[part 7 of 23: package /Cluster]
AUTOSAR XML (schema 4-3-0)
package /Cluster  (continued)
  can cluster E3V_EVCANFD: baudrate=500000, protocol-name=CAN, protocol-version=2.0, bus-off-recovery={bor-counter-l-1-to-l-2=1, bor-time-l-1=0.05, bor-time-l-2=0.2}, can-fd-baudrate=2000000  (continued)
    can physical channel CHNL: comm-connectors=CN_E3V_EVCANFD  (continued)
      frame Motor_52_XIX_E3V_EVCANFD: id 0x14A, to Klima, frame-length=32, can-addressing-mode=STANDARD, can-frame-rx-behavior=CAN-FD, can-frame-tx-behavior=CAN-FD
        pdu Motor_52_XIX_E3V_EVCANFD: length=32, transmission-mode-true-timing=cyclic-timing={time-offset=0, time-period=0.02}, unused-bit-pattern=0
          signal Motor_52_CRC_XIX_Motor_52_XIX_E3V_EVCANFD: start 0, 8 bit, little-endian, data-type-policy=OVERRIDE, i-signal-type=PRIMITIVE, init-value=0, base-type=BT_Motor_52_CRC, compu {phys=raw for raw 0..255}, range phys 0..255, raw 0..255, transfer-property=PENDING  # Für MLB: "Berechnung siehe Lastenheft "Kommunikationsabsicherung für FlexRay und CAN"" Ab MQB und MLBevo: "Berechnung siehe Lastenheft "End-to-End Kommunikationsabsicherung"" Endwerte siehe Begleitdokument "S-PDU Kennungsfolgen"
          signal Motor_52_BZ_XIX_Motor_52_XIX_E3V_EVCANFD: start 8, 4 bit, little-endian, data-type-policy=OVERRIDE, i-signal-type=PRIMITIVE, init-value=0, base-type=BT_Motor_52_BZ, compu {phys=raw for raw 0..15}, range phys 0..15, raw 0..15, transfer-property=PENDING
          signal MO_Hochschaltdrehz_XIX_Motor_52_XIX_E3V_EVCANFD: start 21, 12 bit, little-endian, data-type-policy=OVERRIDE, i-signal-type=PRIMITIVE, init-value=0, base-type=BT_MO_Hochschaltdrehz, invalid-value=Invalid_MO_Hochschaltdrehz_XIX_Motor_52_XIX_E3V_EVCANFD:4095, compu {0=Cx0_keine_manuelle_Hochschaltung (CM_MO_Hochschaltdrehz_Cx0_keine_manuelle_Hochschaltung), phys=raw*3 for raw 1..4094, 4095=Cxfff_Fehler (CM_MO_Hochschaltdrehz_Cxfff_Fehler); unit Unit_MinutInver}, range phys 3..12282 Unit_MinutInver, raw 0..4095, unit=Unit_MinutInver, transfer-property=PENDING  # Hochschaltdrehzahl bei manuellem Gangwechsel über Lenkrad Tip-Up oder Gangwahlhebel falls dieser in Tippgasse. Nur AUDI RS-Modelle!
          signal MO_Anzeige_Verbr_Einheit_XIX_Motor_52_XIX_E3V_EVCANFD: start 33, 2 bit, little-endian, data-type-policy=OVERRIDE, i-signal-type=PRIMITIVE, init-value=0, base-type=BT_MO_Anzeige_Verbr_Einheit, compu {0=Cx0_l_h (CM_MO_Anzeige_Verbr_Einheit_Cx0_l_h), 1=Cx1_kg_h (CM_MO_Anzeige_Verbr_Einheit_Cx1_kg_h)}, range raw 0..1, transfer-property=PENDING  # Signal steht im Kontext MO_Anzeige_Verbrauch und überträgt die Verbrauchseinheit der aktuellen Antriebsart. Signal muss in der gleichen Botschaft wie MO_Anzeige_Verbrauch übertragen werden
          signal MO_Schaltblitz_Anz_XIX_Motor_52_XIX_E3V_EVCANFD: start 35, 7 bit, little-endian, data-type-policy=OVERRIDE, i-signal-type=PRIMITIVE, init-value=126, base-type=BT_MO_Schaltblitz_Anz, invalid-value=Invalid_MO_Schaltblitz_Anz_XIX_Motor_52_XIX_E3V_EVCANFD:127, compu {phys=raw for raw 0..100, 101=Cx65_blinkende_Anzeige (CM_MO_Schaltblitz_Anz_Cx65_blinkende_Anzeige), 126=Cx7e_Init_Funktion_nicht_aktiv (CM_MO_Schaltblitz_Anz_Cx7e_Init_Funktion_nicht_aktiv), 127=Cx7f_Fehler (CM_MO_Schaltblitz_Anz_Cx7f_Fehler); unit Unit_PerCent}, range phys 0..100 Unit_PerCent, raw 0..127, unit=Unit_PerCent, transfer-property=PENDING  # Signalisierung der drehzahlabhängigen Schaltblitzanzeige im Kombiinstrument (0-100%)
          signal MO_Anzeige_Drehmoment_XIX_Motor_52_XIX_E3V_EVCANFD: start 42, 11 bit, little-endian, data-type-policy=OVERRIDE, i-signal-type=PRIMITIVE, init-value=0, base-type=BT_MO_Anzeige_Drehmoment, invalid-value=Invalid_MO_Anzeige_Drehmoment_XIX_Motor_52_XIX_E3V_EVCANFD:2047, compu {phys=raw for raw 0..2045, 2046=Cx7fe_nicht_verbaut (CM_MO_Anzeige_Drehmoment_Cx7fe_nicht_verbaut), 2047=Cx7ff_Fehler (CM_MO_Anzeige_Drehmoment_Cx7ff_Fehler); unit Unit_NewtoMeter}, range phys 0..2045 Unit_NewtoMeter, raw 0..2047, unit=Unit_NewtoMeter, transfer-property=PENDING  # Drehmomentssignal für Sport-HMI im Kombi.
          signal MO_Anzeige_Leistung_XIX_Motor_52_XIX_E3V_EVCANFD: start 53, 11 bit, little-endian, data-type-policy=OVERRIDE, i-signal-type=PRIMITIVE, init-value=0, base-type=BT_MO_Anzeige_Leistung, invalid-value=Invalid_MO_Anzeige_Leistung_XIX_Motor_52_XIX_E3V_EVCANFD:2047, compu {phys=raw*0.6 for raw 0..2045, 2046=Cx7fe_nicht_verbaut (CM_MO_Anzeige_Leistung_Cx7fe_nicht_verbaut), 2047=Cx7ff_Fehler (CM_MO_Anzeige_Leistung_Cx7ff_Fehler); unit Unit_KiloWatt}, range phys 0..1227 Unit_KiloWatt, raw 0..2047, unit=Unit_KiloWatt, transfer-property=PENDING  # Leistungssignal für Sport-HMI im Kombi.
          signal MO_rel_Ladedruck_XIX_Motor_52_XIX_E3V_EVCANFD: start 64, 8 bit, little-endian, data-type-policy=OVERRIDE, i-signal-type=PRIMITIVE, init-value=0, base-type=BT_MO_rel_Ladedruck, invalid-value=Invalid_MO_rel_Ladedruck_XIX_Motor_52_XIX_E3V_EVCANFD:255, compu {phys=raw*0.4 for raw 0..250, 255=Cxff_Fehler (CM_MO_rel_Ladedruck_Cxff_Fehler); unit Unit_PerCent}, range phys 0..100 Unit_PerCent, raw 0..255, unit=Unit_PerCent, transfer-property=PENDING  # relativer Ladedruck (für Boostanzeige)
          signal MO_Istgang_XIX_Motor_52_XIX_E3V_EVCANFD: start 72, 4 bit, little-endian, data-type-policy=OVERRIDE, i-signal-type=PRIMITIVE, init-value=0, base-type=BT_MO_Istgang, compu {0=Cx0_kein_Gang_eingelegt (CM_MO_Istgang_Cx0_kein_Gang_eingelegt), 1=Cx1_Gang_1 (CM_MO_Istgang_Cx1_Gang_1), 2=Cx2_Gang_2 (CM_MO_Istgang_Cx2_Gang_2), 3=Cx3_Gang_3 (CM_MO_Istgang_Cx3_Gang_3), 4=Cx4_Gang_4 (CM_MO_Istgang_Cx4_Gang_4), 5=Cx5_Gang_5 (CM_MO_Istgang_Cx5_Gang_5), 6=Cx6_Gang_6 (CM_MO_Istgang_Cx6_Gang_6), 7=Cx7_Gang_7 (CM_MO_Istgang_Cx7_Gang_7), 8=Cx8_Gang_8 (CM_MO_Istgang_Cx8_Gang_8), 9=Cx9_Gang_9 (CM_MO_Istgang_Cx9_Gang_9)}, range raw 0..9, transfer-property=PENDING  # Aktueller Gang für Anzeige Hochschaltempfehlung (gültig, wenn MO_Schaltempf_verfbar = 1). Anzeige im Kombi: Sollgang == Istgang ==> Anzeige Istgang Sollgang != Istgang ==> Schaltempfehlung Sollgang == Istgang == 0 ==> keine Anzeige
          signal MO_Sollgang_XIX_Motor_52_XIX_E3V_EVCANFD: start 76, 4 bit, little-endian, data-type-policy=OVERRIDE, i-signal-type=PRIMITIVE, init-value=0, base-type=BT_MO_Sollgang, compu {0=Cx0_keine_Empfehlung (CM_MO_Sollgang_Cx0_keine_Empfehlung), 1=Cx1_Gang_1 (CM_MO_Sollgang_Cx1_Gang_1), 2=Cx2_Gang_2 (CM_MO_Sollgang_Cx2_Gang_2), 3=Cx3_Gang_3 (CM_MO_Sollgang_Cx3_Gang_3), 4=Cx4_Gang_4 (CM_MO_Sollgang_Cx4_Gang_4), 5=Cx5_Gang_5 (CM_MO_Sollgang_Cx5_Gang_5), 6=Cx6_Gang_6 (CM_MO_Sollgang_Cx6_Gang_6), 7=Cx7_Gang_7 (CM_MO_Sollgang_Cx7_Gang_7), 8=Cx8_Gang_8 (CM_MO_Sollgang_Cx8_Gang_8), 9=Cx9_Gang_9 (CM_MO_Sollgang_Cx9_Gang_9), 15=Cxf_Neutralgang (CM_MO_Sollgang_Cxf_Neutralgang)}, range raw 0..15, transfer-property=PENDING  # Motor sendet den Sollgang in den der Fahrer schalten soll. Wird im Kombi als Hochschaltempfehlung hervorgehoben (gültig, wenn MO_Schaltempf_verfbar = 1). Anzeige im Kombi: Sollgang == Istgang ==> Anzeige Istgang Sollgang != Istgang ==> Schaltempfehlung Sollgang == Istgang == 0 ==> keine Anzeige Sollgang == 15 ==> Schaltempfehlung in N
          signal MO_Oeldruck_XIX_Motor_52_XIX_E3V_EVCANFD: start 80, 8 bit, little-endian, data-type-policy=OVERRIDE, i-signal-type=PRIMITIVE, init-value=254, base-type=BT_MO_Oeldruck, invalid-value=Invalid_MO_Oeldruck_XIX_Motor_52_XIX_E3V_EVCANFD:255, compu {phys=raw*0.04 for raw 0..250, 254=Cxfe_Init (CM_MO_Oeldruck_Cxfe_Init), 255=Cxff_Fehler (CM_MO_Oeldruck_Cxff_Fehler); unit Unit_Bar}, range phys 0..10 Unit_Bar, raw 0..255, unit=Unit_Bar, transfer-property=PENDING  # Öldruck analog zur Anzeige
          signal MO_Anzeigedrehz_XIX_Motor_52_XIX_E3V_EVCANFD: start 88, 12 bit, little-endian, data-type-policy=OVERRIDE, i-signal-type=PRIMITIVE, init-value=0, base-type=BT_MO_Anzeigedrehz, compu {phys=raw*3 for raw 0..4094, 4095=Cxfff_reserviert (CM_MO_Anzeigedrehz_Cxfff_reserviert); unit Unit_MinutInver}, range phys 0..12282 Unit_MinutInver, raw 0..4095, unit=Unit_MinutInver, transfer-property=PENDING  # Optimierte Anzeigedrehzahl wegen sportlicherem Drehzahlmesser im Kombi. Bei Parallelhybrid: Anzeige VKM- Drehzahl nach Anzeigekonzept Hinweis: Ehemaliger Fehlerwert 0xFFF wird senderseitig nicht unterstützt. Diesen Wert aus Kompatibilitätsgründen nicht neu belegen!
          signal MO_Effizienzmodus_XIX_Motor_52_XIX_E3V_EVCANFD: start 100, 1 bit, little-endian, data-type-policy=OVERRIDE, i-signal-type=PRIMITIVE, init-value=0, base-type=BT_MO_Effizienzmodus, compu {0=Cx0_nicht_im_Effizienz_Modus (CM_MO_Effizienzmodus_Cx0_nicht_im_Effizienz_Modus), 1=Cx1_Effizienz_Modus (CM_MO_Effizienzmodus_Cx1_Effizienz_Modus)}, range raw 0..1, transfer-property=PENDING  # Bei Handschaltern wird das Fahrprogramm Effizienz signalisiert. Bei Automatikgetrieben wird das Fahrprogramm "D" durch "E" ersetzt.
          signal MO_Fehler_Oeldrucksensor_XIX_Motor_52_XIX_E3V_EVCANFD: start 101, 1 bit, little-endian, data-type-policy=OVERRIDE, i-signal-type=PRIMITIVE, init-value=0, base-type=BT_MO_Fehler_Oeldrucksensor, invalid-value=Invalid_MO_Fehler_Oeldrucksensor_XIX_Motor_52_XIX_E3V_EVCANFD:1, compu {0=Cx0_kein_Fehler (CM_MO_Fehler_Oeldrucksensor_Cx0_kein_Fehler), 1=Cx1_Fehler (CM_MO_Fehler_Oeldrucksensor_Cx1_Fehler)}, range raw 0..1, transfer-property=PENDING  # Steuert im Kombiinstrument die gelbe zentrale Warnlampe und das Symbol "gelbe Ölkanne" mit der Textmeldung "Sensorfehler: Werkstatt aufsuchen" an
          signal MO_Schaltempf_verfbar_XIX_Motor_52_XIX_E3V_EVCANFD: start 102, 1 bit, little-endian, data-type-policy=OVERRIDE, i-signal-type=PRIMITIVE, init-value=0, base-type=BT_MO_Schaltempf_verfbar, compu {0=Cx0_nicht_verfuegbar (CM_MO_Schaltempf_verfbar_Cx0_nicht_verfuegbar), 1=Cx1_verfuegbar (CM_MO_Schaltempf_verfbar_Cx1_verfuegbar)}, range raw 0..1, transfer-property=PENDING  # Info, ob Schaltempfehlung im Fzg. verfügbar. Statischer Wert, ändert sich für ein Fzg. nicht!
          signal MO_Ladedruck_XIX_Motor_52_XIX_E3V_EVCANFD: start 103, 9 bit, little-endian, data-type-policy=OVERRIDE, i-signal-type=PRIMITIVE, init-value=0, base-type=BT_MO_Ladedruck, invalid-value=Invalid_MO_Ladedruck_XIX_Motor_52_XIX_E3V_EVCANFD:511, compu {phys=raw*0.01 for raw 0..510, 511=Cx1ff_Fehler (CM_MO_Ladedruck_Cx1ff_Fehler); unit Unit_Bar}, range phys 0..5.1 Unit_Bar, raw 0..511, unit=Unit_Bar, transfer-property=PENDING  # absoluter Ladedruck
          signal MO_KVS_XIX_Motor_52_XIX_E3V_EVCANFD: start 112, 15 bit, little-endian, data-type-policy=OVERRIDE, i-signal-type=PRIMITIVE, init-value=0, base-type=BT_MO_KVS, compu {phys=raw for raw 0..32767; unit Unit_MicroLiter}, range phys 0..32767 Unit_MicroLiter, raw 0..32767, unit=Unit_MicroLiter, transfer-property=PENDING  # Motorsteuergerätinterner Verbrauchszähler, der vom Kombi zyklisch ausgelesen wird, um die Einspritzmenge zur Verbrauchsmessung aufzusummieren; aus diesem Zählerstand werden Momentan- und Durchschnittsverbrauch berechnet; das Überlauf-Bit ist zu berücksichtigen
          signal MO_KVS_Ueberlauf_XIX_Motor_52_XIX_E3V_EVCANFD: start 127, 1 bit, little-endian, data-type-policy=OVERRIDE, i-signal-type=PRIMITIVE, init-value=0, base-type=BT_MO_KVS_Ueberlauf, compu {0=Cx0_kein_Ueberlauf (CM_MO_KVS_Ueberlauf_Cx0_kein_Ueberlauf) (kein Ueberlauf), 1=Cx1_Kraftstoffverbrauchsignale_mindestens_1x_uebergelaufen (CM_MO_KVS_Ueberlauf_Cx1_Kraftstoffverbrauchsignale_mindestens_1x_uebergelaufen) (Kraftstoffverbrauchsignale mindestens 1x übergelaufen)}, range raw 0..1, transfer-property=PENDING  # Der motorsteuergeräteinterne Verbrauchszähler ist mindestens einmal übergelaufen. Dieses Bit wird genutzt, um erkennen zu können, daß das Motorsteuergerät aus dem Reset-Zustand hochläuft.
          signal MO_ePowermeter_XIX_Motor_52_XIX_E3V_EVCANFD: start 128, 8 bit, little-endian, data-type-policy=OVERRIDE, i-signal-type=PRIMITIVE, init-value=0, base-type=BT_MO_ePowermeter, compu {0=Cx0_Init_keine_Anzeige (CM_MO_ePowermeter_Cx0_Init_keine_Anzeige), phys=raw*0.4-0.4 for raw 1..253, 254=Cxfe_Funktion_deaktiv_Anzeige_ausgegraut (CM_MO_ePowermeter_Cxfe_Funktion_deaktiv_Anzeige_ausgegraut), 255=Cxff_Fehler_keine_Anzeige (CM_MO_ePowermeter_Cxff_Fehler_keine_Anzeige); unit Unit_PerCent}, range phys 0..100.8 Unit_PerCent, raw 0..255, unit=Unit_PerCent, transfer-property=PENDING  # Anzeige ePowermeter (Fahrreserve elektrisch bis Start Verbrennungsmotor (Verbrenner startet bei 100%))
          signal MO_ePerformance_XIX_Motor_52_XIX_E3V_EVCANFD: start 136, 8 bit, little-endian, data-type-policy=OVERRIDE, i-signal-type=PRIMITIVE, init-value=0, base-type=BT_MO_ePerformance, invalid-value=Invalid_MO_ePerformance_XIX_Motor_52_XIX_E3V_EVCANFD:255, compu {0=Cx0_Init (CM_MO_ePerformance_Cx0_Init), phys=raw*0.4-0.4 for raw 1..253, 254=Cxfe_Funktion_deaktiv_Anz_ausgegraut (CM_MO_ePerformance_Cxfe_Funktion_deaktiv_Anz_ausgegraut), 255=Cxff_Fehler (CM_MO_ePerformance_Cxff_Fehler); unit Unit_PerCent}, range phys 0..100.8 Unit_PerCent, raw 0..255, unit=Unit_PerCent, transfer-property=PENDING  # Zeigt die elektrische Leistungreserve bei BEV und PHEV Projekten an. Bei Init und Fehler soll keine Anzeige erfolgen.
          signal MO_Zust_Antrieb_XIX_Motor_52_XIX_E3V_EVCANFD: start 144, 4 bit, little-endian, data-type-policy=OVERRIDE, i-signal-type=PRIMITIVE, init-value=0, base-type=BT_MO_Zust_Antrieb, compu {0=Cx0_VM_bzw_Brennstoffz_aktiv (CM_MO_Zust_Antrieb_Cx0_VM_bzw_Brennstoffz_aktiv) (VM bzw. Brennstoffz. aktiv), 1=Cx1_EM_aktiv (CM_MO_Zust_Antrieb_Cx1_EM_aktiv) (EM aktiv), 2=Cx2_VM_bzw_Brennstoffz_u_EM_aktiv (CM_MO_Zust_Antrieb_Cx2_VM_bzw_Brennstoffz_u_EM_aktiv) (VM bzw. Brennstoffz. u. EM aktiv), 3=Cx3_Segeln_oder_Reku_aktiv (CM_MO_Zust_Antrieb_Cx3_Segeln_oder_Reku_aktiv) (Segeln oder Reku aktiv)}, range raw 0..3, transfer-property=PENDING  # Signalisiert die Zuordnung der Antriebsverbräuche zu den Antriebsmaschinen für die Restreichweitenberechnung, nicht gleichbedeutend mit Motorlauf EM oder VM bzw. Brennstoffzelle
          signal MO_Zust_Betriebsstrategie_XIX_Motor_52_XIX_E3V_EVCANFD: start 148, 3 bit, little-endian, data-type-policy=OVERRIDE, i-signal-type=PRIMITIVE, init-value=0, base-type=BT_MO_Zust_Betriebsstrategie, compu {0=Cx0_Kein_Hybrid (CM_MO_Zust_Betriebsstrategie_Cx0_Kein_Hybrid) (Kein Hybrid), 1=Cx1_Depleting (CM_MO_Zust_Betriebsstrategie_Cx1_Depleting), 2=Cx2_Soft_Depleting (CM_MO_Zust_Betriebsstrategie_Cx2_Soft_Depleting) (Soft-Depleting), 3=Cx3_Sustaining (CM_MO_Zust_Betriebsstrategie_Cx3_Sustaining), 4=Cx4_Increasing (CM_MO_Zust_Betriebsstrategie_Cx4_Increasing), 5=Cx5_Fremdgesteuert (CM_MO_Zust_Betriebsstrategie_Cx5_Fremdgesteuert)}, range raw 0..5, transfer-property=PENDING  # Signalisiert den aktuellen Zustand der Betriebsstrategie
          signal Ladezustand_02_XIX_Motor_52_XIX_E3V_EVCANFD: start 152, 8 bit, little-endian, data-type-policy=OVERRIDE, i-signal-type=PRIMITIVE, init-value=254, base-type=BT_Ladezustand_02, invalid-value=Invalid_Ladezustand_02_XIX_Motor_52_XIX_E3V_EVCANFD:255, compu {phys=raw*0.5 for raw 0..200, 254=Cxfe_Init (CM_Ladezustand_02_Cxfe_Init), 255=Cxff_Fehler (CM_Ladezustand_02_Cxff_Fehler); unit Unit_PerCent}, range phys 0..100 Unit_PerCent, raw 0..255, unit=Unit_PerCent, transfer-property=PENDING, to Klima(timeout 0.5 s)  # Aktueller relativer Ladezustand der HV-Batterie
          signal Ladezustand_gering_XIX_Motor_52_XIX_E3V_EVCANFD: start 160, 2 bit, little-endian, data-type-policy=OVERRIDE, i-signal-type=PRIMITIVE, init-value=0, base-type=BT_Ladezustand_gering, compu {0=Cx0_keine_Anzeige (CM_Ladezustand_gering_Cx0_keine_Anzeige), 1=Cx1_Ladezustand_gering (CM_Ladezustand_gering_Cx1_Ladezustand_gering), 2=Cx2_Batterie_fast_leer (CM_Ladezustand_gering_Cx2_Batterie_fast_leer), 3=Cx3_Batterie_leer (CM_Ladezustand_gering_Cx3_Batterie_leer)}, range raw 0..3, transfer-property=PENDING  # Fahrerwarnung bezüglich geringem Ladezustand der HV-Batterie
          signal MO_Powermeter_Elm_02_XIX_Motor_52_XIX_E3V_EVCANFD: start 168, 12 bit, little-endian, data-type-policy=OVERRIDE, i-signal-type=PRIMITIVE, init-value=4094, base-type=BT_MO_Powermeter_Elm_02, compu {0=Cx0_nicht_verbaut (CM_MO_Powermeter_Elm_02_Cx0_nicht_verbaut), phys=raw*0.05-102.4 for raw 48..4048, 4094=Cxffe_Init (CM_MO_Powermeter_Elm_02_Cxffe_Init); unit Unit_PerCent}, range phys -100..100 Unit_PerCent, raw 0..4094, unit=Unit_PerCent, transfer-property=PENDING  # relatives Moment / relative Leistung der elektrischen Maschine
          signal MO_Powermeter_XIX_Motor_52_XIX_E3V_EVCANFD: start 180, 12 bit, little-endian, data-type-policy=OVERRIDE, i-signal-type=PRIMITIVE, init-value=4093, base-type=BT_MO_Powermeter, compu {phys=raw for raw 0..4092, 4093=Cxffd_Off (CM_MO_Powermeter_Cxffd_Off)}, range phys 0..4092, raw 0..4093, transfer-property=PENDING  # Anzeigewerte im Kombi 0 = Unteres Ende Bremsen/grau; 340 = Unteres Ende CHARGE; 1020 = READY; 1870 = Oberes Ende EFFICIENCY; 3400 = 100%; 4080 = MAX;
          signal MO_OnePedalDriving_Warnung_XIX_Motor_52_XIX_E3V_EVCANFD: start 192, 2 bit, little-endian, data-type-policy=OVERRIDE, i-signal-type=PRIMITIVE, init-value=0, base-type=BT_MO_OnePedalDriving_Warnung, compu {0=Cx0_keine_Warnung (CM_MO_OnePedalDriving_Warnung_Cx0_keine_Warnung), 1=Cx1_Warnstufe_1 (CM_MO_OnePedalDriving_Warnung_Cx1_Warnstufe_1)}, range raw 0..1, transfer-property=PENDING  # Bewarnung des Fahrers, wenn keine ausreichende Verzögerung aus der Funktion OnePedalDriving dargestellt werden kann. MO_OnePedalDriving_Warnung = 0 -> keine Warnung MO_OnePedalDriving_Warnung = 1 -> 1. Warnstufe
          signal MO_VKMVirt_Drehzahl_XIX_Motor_52_XIX_E3V_EVCANFD: start 200, 16 bit, little-endian, data-type-policy=OVERRIDE, i-signal-type=PRIMITIVE, init-value=0, base-type=BT_MO_VKMVirt_Drehzahl, compu {phys=raw*0.25 for raw 0..65532; unit Unit_MinutInver}, range phys 0..16383 Unit_MinutInver, raw 0..65532, unit=Unit_MinutInver, transfer-property=PENDING  # Signal zeigt die virtuelle, simulierte VKM-Drehzahl an
      frame Motor_54_XIX_E3V_EVCANFD: id 0x14C, to Klima, frame-length=32, can-addressing-mode=STANDARD, can-frame-rx-behavior=CAN-FD, can-frame-tx-behavior=CAN-FD
        pdu Motor_54_XIX_E3V_EVCANFD: length=32, minimum-delay=0.01, transmission-mode-true-timing={cyclic-timing={time-offset=0.0, time-period=0.1}, event-controlled-timing={number-of-repetitions=0, repetition-period=0.0}}, unused-bit-pattern=0
          signal Motor_54_CRC_XIX_Motor_54_XIX_E3V_EVCANFD: start 0, 8 bit, little-endian, data-type-policy=OVERRIDE, i-signal-type=PRIMITIVE, base-type=BT_Motor_54_CRC, compu {phys=raw for raw 0..255}, range phys 0..255, raw 0..255, transfer-property=PENDING  # Für MLB: Berechnung siehe Lastenheft "Kommunikationsabsicherung für FlexRay und CAN" Ab MQB und MLBevo: Berechnung siehe Lastenheft "End-to-End Kommunikationsabsicherung" Endwerte siehe Begleitdokument "S-PDU Kennungsfolgen"
          signal Motor_54_BZ_XIX_Motor_54_XIX_E3V_EVCANFD: start 8, 4 bit, little-endian, data-type-policy=OVERRIDE, i-signal-type=PRIMITIVE, base-type=BT_Motor_54_BZ, compu {phys=raw for raw 0..15}, range phys 0..15, raw 0..15, transfer-property=PENDING  # 4bit Botschaftszähler, wird mit jeder Sendebotschaft inkrementiert
          signal MO_Anforderung_HMS_XIX_Motor_54_XIX_E3V_EVCANFD: start 12, 3 bit, little-endian, data-type-policy=OVERRIDE, i-signal-type=PRIMITIVE, init-value=0, base-type=BT_MO_Anforderung_HMS, compu {0=Cx0_keine_Anforderung (CM_MO_Anforderung_HMS_Cx0_keine_Anforderung), 1=Cx1_halten (CM_MO_Anforderung_HMS_Cx1_halten), 2=Cx2_parken (CM_MO_Anforderung_HMS_Cx2_parken), 3=Cx3_halten_Standby (CM_MO_Anforderung_HMS_Cx3_halten_Standby), 4=Cx4_anfahren (CM_MO_Anforderung_HMS_Cx4_anfahren), 5=Cx5_Loesen_ueber_Rampe (CM_MO_Anforderung_HMS_Cx5_Loesen_ueber_Rampe), 7=Cx7_HMS_uebernehmen (CM_MO_Anforderung_HMS_Cx7_HMS_uebernehmen)}, range raw 0..7, transfer-property=TRIGGERED-ON-CHANGE-WITHOUT-REPETITION  # Halteanforderung vom Motor an HMS
          signal FoD_DTC_TSK_GRA_XIX_Motor_54_XIX_E3V_EVCANFD: start 15, 1 bit, little-endian, data-type-policy=OVERRIDE, i-signal-type=PRIMITIVE, init-value=0, base-type=BT_FoD_DTC_TSK_GRA, compu {0=Cx0_Kein_DTC (CM_FoD_DTC_TSK_GRA_Cx0_Kein_DTC), 1=Cx1_DTC_vorhanden_oder_in_Quali (CM_FoD_DTC_TSK_GRA_Cx1_DTC_vorhanden_oder_in_Quali)}, range raw 0..1, transfer-property=PENDING  # DTC ist entweder bereits eingetragen oder wird eingetragen, sobald die zugehörige FoD Funktion freigeschaltet wird.
          signal TSK_vMax_aktuell_XIX_Motor_54_XIX_E3V_EVCANFD: start 16, 8 bit, little-endian, data-type-policy=OVERRIDE, i-signal-type=PRIMITIVE, init-value=255, base-type=BT_TSK_vMax_aktuell, compu {phys=raw for raw 0..253, 254=Cxfe_kein_Limit_aktiv (CM_TSK_vMax_aktuell_Cxfe_kein_Limit_aktiv), 255=Cxff_Init (CM_TSK_vMax_aktuell_Cxff_Init); unit Unit_KiloMeterPerHour}, range phys 0..253 Unit_KiloMeterPerHour, raw 0..255, unit=Unit_KiloMeterPerHour, transfer-property=PENDING  # Im aktuellen Betriebszustand global gültige Geschwindigkeitslimitierung.
          signal ISA_Status_XIX_Motor_54_XIX_E3V_EVCANFD: start 24, 3 bit, little-endian, data-type-policy=OVERRIDE, i-signal-type=PRIMITIVE, init-value=1, base-type=BT_ISA_Status, compu {0=Cx0_ISA_nicht_aktiv (CM_ISA_Status_Cx0_ISA_nicht_aktiv), 1=Cx1_Init (CM_ISA_Status_Cx1_Init), 2=Cx2_ISA_degradiert (CM_ISA_Status_Cx2_ISA_degradiert), 3=Cx3_ISA_aktiv (CM_ISA_Status_Cx3_ISA_aktiv), 4=Cx4_reserviert (CM_ISA_Status_Cx4_reserviert), 5=Cx5_reserviert (CM_ISA_Status_Cx5_reserviert), 6=Cx6_reserviert (CM_ISA_Status_Cx6_reserviert), 7=Cx7_reserviert (CM_ISA_Status_Cx7_reserviert)}, range raw 0..7, transfer-property=TRIGGERED-ON-CHANGE-WITHOUT-REPETITION  # Signalisiert den Status der Funktion Intelligent Speed Assist (ISA). Der Status zeigt an, ob ISA Tempolimits übernimmt und einregelt. Dabei wird unterschieden, ob es sich um eine globale Aktivierung/Deaktivierung der Funktion, oder um eine temporäre Einschränkung der Tempolimit-Übernahme handelt.
          signal ISA_Regelung_aktiv_XIX_Motor_54_XIX_E3V_EVCANFD: start 27, 1 bit, little-endian, data-type-policy=OVERRIDE, i-signal-type=PRIMITIVE, init-value=0, base-type=BT_ISA_Regelung_aktiv, compu {0=Cx0_ISA_Regelung_nicht_aktiv (CM_ISA_Regelung_aktiv_Cx0_ISA_Regelung_nicht_aktiv), 1=Cx1_ISA_Regelung_aktiv (CM_ISA_Regelung_aktiv_Cx1_ISA_Regelung_aktiv)}, range raw 0..1, transfer-property=TRIGGERED-ON-CHANGE-WITHOUT-REPETITION  # Signalisiert, dass die Regelung zur Überführung der Fahrzeuggeschwindigkeit auf ein gültiges Tempolimit der Funktion Intelligent Speed Assist (ISA) aktiv ist.
          signal MO_Red_El_Fahrleistung_XIX_Motor_54_XIX_E3V_EVCANFD: start 29, 3 bit, little-endian, data-type-policy=OVERRIDE, i-signal-type=PRIMITIVE, init-value=0, base-type=BT_MO_Red_El_Fahrleistung, compu {0=Cx0_keine_Anzeige (CM_MO_Red_El_Fahrleistung_Cx0_keine_Anzeige), 1=Cx1_mehr_als_20Prcnt_Red (CM_MO_Red_El_Fahrleistung_Cx1_mehr_als_20Prcnt_Red), 2=Cx2_Reserve_1 (CM_MO_Red_El_Fahrleistung_Cx2_Reserve_1), 3=Cx3_Reserve_2 (CM_MO_Red_El_Fahrleistung_Cx3_Reserve_2), 4=Cx4_unter_GBB_Schwelle_Anhaenger (CM_MO_Red_El_Fahrleistung_Cx4_unter_GBB_Schwelle_Anhaenger), 5=Cx5_unter_GBB_Schwelle (CM_MO_Red_El_Fahrleistung_Cx5_unter_GBB_Schwelle), 6=Cx6_unter_minimal_Schwelle (CM_MO_Red_El_Fahrleistung_Cx6_unter_minimal_Schwelle), 7=Cx7_kein_Vortrieb (CM_MO_Red_El_Fahrleistung_Cx7_kein_Vortrieb)}, range raw 0..7, transfer-property=PENDING  # Anzeige einer eingeschränkten Fahrleistung
          signal TSK_Status_EA_XIX_Motor_54_XIX_E3V_EVCANFD: start 32, 3 bit, little-endian, data-type-policy=OVERRIDE, i-signal-type=PRIMITIVE, init-value=1, base-type=BT_TSK_Status_EA, invalid-value=Invalid_TSK_Status_EA_XIX_Motor_54_XIX_E3V_EVCANFD:7, compu {0=Cx0_Aus (CM_TSK_Status_EA_Cx0_Aus), 1=Cx1_Init_oder_nicht_verbaut (CM_TSK_Status_EA_Cx1_Init_oder_nicht_verbaut), 3=Cx3_Aktiv (CM_TSK_Status_EA_Cx3_Aktiv), 4=Cx4_Uebertreten (CM_TSK_Status_EA_Cx4_Uebertreten), 5=Cx5_Abschaltung_laeuft (CM_TSK_Status_EA_Cx5_Abschaltung_laeuft), 6=Cx6_Reversibel_aus (CM_TSK_Status_EA_Cx6_Reversibel_aus), 7=Cx7_Fehler (CM_TSK_Status_EA_Cx7_Fehler)}, range raw 0..7, transfer-property=TRIGGERED-ON-CHANGE-WITHOUT-REPETITION  # Funktionsstatus des Triebstrangkoordinators für den Anforderer Emergency Assist
          signal FoD_DTC_TSK_ACC_XIX_Motor_54_XIX_E3V_EVCANFD: start 35, 1 bit, little-endian, data-type-policy=OVERRIDE, i-signal-type=PRIMITIVE, init-value=0, base-type=BT_FoD_DTC_TSK_ACC, compu {0=Cx0_Kein_DTC (CM_FoD_DTC_TSK_ACC_Cx0_Kein_DTC), 1=Cx1_DTC_vorhanden_oder_in_Quali (CM_FoD_DTC_TSK_ACC_Cx1_DTC_vorhanden_oder_in_Quali)}, range raw 0..1, transfer-property=PENDING  # DTC ist entweder bereits eingetragen oder wird eingetragen, sobald die zugehörige FOD Funktion freigeschaltet wird.
          signal TSK_ACC_FoD_Status_XIX_Motor_54_XIX_E3V_EVCANFD: start 36, 2 bit, little-endian, data-type-policy=OVERRIDE, i-signal-type=PRIMITIVE, init-value=0, base-type=BT_TSK_ACC_FoD_Status, compu {0=Cx0_default (CM_TSK_ACC_FoD_Status_Cx0_default), 1=Cx1_nicht_aktiv (CM_TSK_ACC_FoD_Status_Cx1_nicht_aktiv), 2=Cx2_aktiv (CM_TSK_ACC_FoD_Status_Cx2_aktiv), 3=Cx3_nicht_genutzt (CM_TSK_ACC_FoD_Status_Cx3_nicht_genutzt)}, range raw 0..3, transfer-property=PENDING  # Information, ob die TSK-ACC-Funktion freigeschaltet ist oder nicht.
          signal TSK_GRA_FoD_Status_XIX_Motor_54_XIX_E3V_EVCANFD: start 38, 2 bit, little-endian, data-type-policy=OVERRIDE, i-signal-type=PRIMITIVE, init-value=0, base-type=BT_TSK_GRA_FoD_Status, compu {0=Cx0_default (CM_TSK_GRA_FoD_Status_Cx0_default), 1=Cx1_nicht_aktiv (CM_TSK_GRA_FoD_Status_Cx1_nicht_aktiv), 2=Cx2_aktiv (CM_TSK_GRA_FoD_Status_Cx2_aktiv), 3=Cx3_nicht_genutzt (CM_TSK_GRA_FoD_Status_Cx3_nicht_genutzt)}, range raw 0..3, transfer-property=PENDING  # Information, ob die TSK-GRA-Funktion freigeschaltet ist oder nicht.
          signal TSK_vMax_Fahrerassistenz_XIX_Motor_54_XIX_E3V_EVCANFD: start 40, 9 bit, little-endian, data-type-policy=OVERRIDE, i-signal-type=PRIMITIVE, init-value=511, base-type=BT_TSK_vMax_Fahrerassistenz, compu {phys=raw for raw 0..510, 511=Cx1ff_Init_ungueltig_keine_Beschraenkung (CM_TSK_vMax_Fahrerassistenz_Cx1ff_Init_ungueltig_keine_Beschraenkung)}, range phys 0..510, raw 0..511, transfer-property=PENDING  # maximale Sollgeschwindigkeit für GRA/ACC/Limiter Hinweis: Signal ist mit Signal TSK_Einheit_vMax_Fahrerassistenz zu interpretieren. Das Signal wird abwechselnd in km/h und mph gesendet.
          signal TSK_Einheit_vMax_Fahrerassistenz_XIX_Motor_54_XIX_E3V_EVCANFD: start 49, 1 bit, little-endian, data-type-policy=OVERRIDE, i-signal-type=PRIMITIVE, init-value=0, base-type=BT_TSK_Einheit_vMax_Fahrerassistenz, compu {0=Cx0_kmh (CM_TSK_Einheit_vMax_Fahrerassistenz_Cx0_kmh), 1=Cx1_mph (CM_TSK_Einheit_vMax_Fahrerassistenz_Cx1_mph)}, range raw 0..1, transfer-property=PENDING  # Einheit zu Signal TSK_vMax_Fahrerassistenz
          signal TSK_Status_PLA_XIX_Motor_54_XIX_E3V_EVCANFD: start 50, 3 bit, little-endian, data-type-policy=OVERRIDE, i-signal-type=PRIMITIVE, init-value=1, base-type=BT_TSK_Status_PLA, invalid-value=Invalid_TSK_Status_PLA_XIX_Motor_54_XIX_E3V_EVCANFD:7, compu {0=Cx0_Aus_Funktionsbereit (CM_TSK_Status_PLA_Cx0_Aus_Funktionsbereit), 1=Cx1_Init_oder_nicht_verbaut (CM_TSK_Status_PLA_Cx1_Init_oder_nicht_verbaut), 2=Cx2_aktivierbar (CM_TSK_Status_PLA_Cx2_aktivierbar), 3=Cx3_aktiv (CM_TSK_Status_PLA_Cx3_aktiv), 5=Cx5_Abschaltung_laeuft (CM_TSK_Status_PLA_Cx5_Abschaltung_laeuft), 6=Cx6_reversibel_aus (CM_TSK_Status_PLA_Cx6_reversibel_aus), 7=Cx7_Fehler (CM_TSK_Status_PLA_Cx7_Fehler)}, range raw 0..7, transfer-property=TRIGGERED-ON-CHANGE-WITHOUT-REPETITION  # Funktionsstatus des Triebstrangkoordinators für den Speedlimiter des Parkassistenten
          signal TSK_aktives_System_XIX_Motor_54_XIX_E3V_EVCANFD: start 53, 3 bit, little-endian, data-type-policy=OVERRIDE, i-signal-type=PRIMITIVE, init-value=0, base-type=BT_TSK_aktives_System, compu {0=Cx0_keine_Funktion_aktiv (CM_TSK_aktives_System_Cx0_keine_Funktion_aktiv), 1=Cx1_GRA_ACC (CM_TSK_aktives_System_Cx1_GRA_ACC), 2=Cx2_ARA (CM_TSK_aktives_System_Cx2_ARA), 3=Cx3_Speedlimiter (CM_TSK_aktives_System_Cx3_Speedlimiter), 4=Cx4_IPA (CM_TSK_aktives_System_Cx4_IPA), 5=Cx5_PLA (CM_TSK_aktives_System_Cx5_PLA), 6=Cx6_PEA_Ausrollassistent (CM_TSK_aktives_System_Cx6_PEA_Ausrollassistent), 7=Cx7_EA (CM_TSK_aktives_System_Cx7_EA)}, range raw 0..7, transfer-property=TRIGGERED-ON-CHANGE-WITHOUT-REPETITION  # Anzeige der in der TSK-Längsführung aktiven Funktion
          signal TSK_erhoehter_Fahrwiderstand_XIX_Motor_54_XIX_E3V_EVCANFD: start 56, 1 bit, little-endian, data-type-policy=OVERRIDE, i-signal-type=PRIMITIVE, init-value=0, base-type=BT_TSK_erhoehter_Fahrwiderstand, compu {0=Cx0_kein_erhoehter_Fahrwiderstand (CM_TSK_erhoehter_Fahrwiderstand_Cx0_kein_erhoehter_Fahrwiderstand), 1=Cx1_erhoehter_Fahrwiderstand (CM_TSK_erhoehter_Fahrwiderstand_Cx1_erhoehter_Fahrwiderstand)}, range raw 0..1, transfer-property=TRIGGERED-ON-CHANGE-WITHOUT-REPETITION  # Rueckmeldung vom Triebstrangkoordinator, dass eine große Reglerdifferenz detektiert wurde. Soll ermoeglichen, einen ggfs. unbekannten Fahrwiderstand am Boden zu erkennen.
          signal TSK_Anf_Antriebsmoment_XIX_Motor_54_XIX_E3V_EVCANFD: start 57, 1 bit, little-endian, data-type-policy=OVERRIDE, i-signal-type=PRIMITIVE, init-value=0, base-type=BT_TSK_Anf_Antriebsmoment, compu {0=Cx0_keine_Anforderung (CM_TSK_Anf_Antriebsmoment_Cx0_keine_Anforderung), 1=Cx1_Anforderung_aktiv (CM_TSK_Anf_Antriebsmoment_Cx1_Anforderung_aktiv)}, range raw 0..1, transfer-property=TRIGGERED-ON-CHANGE-WITHOUT-REPETITION  # Das Signal zeigt an, ob die TSK-Laengsregelung aktuell Antriebsmoment anfordert, zur Verwendung in der ASR/EDS-Funktion
          signal TSK_Status_ARA_XIX_Motor_54_XIX_E3V_EVCANFD: start 58, 3 bit, little-endian, data-type-policy=OVERRIDE, i-signal-type=PRIMITIVE, init-value=1, base-type=BT_TSK_Status_ARA, invalid-value=Invalid_TSK_Status_ARA_XIX_Motor_54_XIX_E3V_EVCANFD:7, compu {0=Cx0_Aus (CM_TSK_Status_ARA_Cx0_Aus), 1=Cx1_Init_oder_nicht_verbaut (CM_TSK_Status_ARA_Cx1_Init_oder_nicht_verbaut), 2=Cx2_aktivierbar (CM_TSK_Status_ARA_Cx2_aktivierbar), 3=Cx3_aktiv (CM_TSK_Status_ARA_Cx3_aktiv), 5=Cx5_abschaltung_laeuft (CM_TSK_Status_ARA_Cx5_abschaltung_laeuft), 6=Cx6_reversibel_aus (CM_TSK_Status_ARA_Cx6_reversibel_aus), 7=Cx7_Fehler (CM_TSK_Status_ARA_Cx7_Fehler)}, range raw 0..7, transfer-property=TRIGGERED-ON-CHANGE-WITHOUT-REPETITION  # Funktionsstatus des Triebstrangkoordinators für den Anhängerrangierassistenten
          signal TSK_Status_IPA_XIX_Motor_54_XIX_E3V_EVCANFD: start 61, 3 bit, little-endian, data-type-policy=OVERRIDE, i-signal-type=PRIMITIVE, init-value=1, base-type=BT_TSK_Status_IPA, invalid-value=Invalid_TSK_Status_IPA_XIX_Motor_54_XIX_E3V_EVCANFD:7, compu {0=Cx0_Aus_Funktionsbereit (CM_TSK_Status_IPA_Cx0_Aus_Funktionsbereit), 1=Cx1_Init_oder_nicht_verbaut (CM_TSK_Status_IPA_Cx1_Init_oder_nicht_verbaut), 2=Cx2_aktivierbar (CM_TSK_Status_IPA_Cx2_aktivierbar), 3=Cx3_aktiv (CM_TSK_Status_IPA_Cx3_aktiv), 4=Cx4_Fahreruebernahme_angefordert (CM_TSK_Status_IPA_Cx4_Fahreruebernahme_angefordert), 5=Cx5_Abschaltung_laueft (CM_TSK_Status_IPA_Cx5_Abschaltung_laueft), 6=Cx6_reversibel_aus (CM_TSK_Status_IPA_Cx6_reversibel_aus), 7=Cx7_Fehler (CM_TSK_Status_IPA_Cx7_Fehler)}, range raw 0..7, transfer-property=TRIGGERED-ON-CHANGE-WITHOUT-REPETITION  # Funktionsstatus des Triebstrangkoordinators für die Längsführung des Einparkassistenten
          signal TSK_aktives_System_02_XIX_Motor_54_XIX_E3V_EVCANFD: start 64, 4 bit, little-endian, data-type-policy=OVERRIDE, i-signal-type=PRIMITIVE, init-value=0, base-type=BT_TSK_aktives_System_02, compu {0=Cx0_keine_Funktion_aktiv (CM_TSK_aktives_System_02_Cx0_keine_Funktion_aktiv), 1=Cx1_GRA_ACC (CM_TSK_aktives_System_02_Cx1_GRA_ACC), 2=Cx2_ARA (CM_TSK_aktives_System_02_Cx2_ARA), 3=Cx3_Speedlimiter (CM_TSK_aktives_System_02_Cx3_Speedlimiter), 4=Cx4_IPA (CM_TSK_aktives_System_02_Cx4_IPA), 5=Cx5_PLA (CM_TSK_aktives_System_02_Cx5_PLA), 6=Cx6_PEA_Ausrollassistent (CM_TSK_aktives_System_02_Cx6_PEA_Ausrollassistent), 7=Cx7_EA (CM_TSK_aktives_System_02_Cx7_EA), 8=Cx8_Staupilot (CM_TSK_aktives_System_02_Cx8_Staupilot), 9=Cx9_RHP (CM_TSK_aktives_System_02_Cx9_RHP)}, range raw 0..9, transfer-property=TRIGGERED-ON-CHANGE-WITHOUT-REPETITION  # Anzeige der in der TSK-Längsführung aktiven Funktion
          signal TSK_Status_RHP_XIX_Motor_54_XIX_E3V_EVCANFD: start 68, 3 bit, little-endian, data-type-policy=OVERRIDE, i-signal-type=PRIMITIVE, init-value=0, base-type=BT_TSK_Status_RHP, compu {0=Cx0_off (CM_TSK_Status_RHP_Cx0_off), 1=Cx1_init (CM_TSK_Status_RHP_Cx1_init), 2=Cx2_standby (CM_TSK_Status_RHP_Cx2_standby), 3=Cx3_active (CM_TSK_Status_RHP_Cx3_active), 4=Cx4_driver_override (CM_TSK_Status_RHP_Cx4_driver_override), 5=Cx5_shutdown (CM_TSK_Status_RHP_Cx5_shutdown), 6=Cx6_reversible_failure (CM_TSK_Status_RHP_Cx6_reversible_failure), 7=Cx7_irreversible_failure (CM_TSK_Status_RHP_Cx7_irreversible_failure)}, range raw 0..7, transfer-property=TRIGGERED-ON-CHANGE-WITHOUT-REPETITION  # Functional status of the drive train coordinator for the longitudinal guidance of the rush hour pilot.
          signal MO_OnePedalDriving_integriert_XIX_Motor_54_XIX_E3V_EVCANFD: start 71, 1 bit, little-endian, data-type-policy=OVERRIDE, i-signal-type=PRIMITIVE, init-value=0, base-type=BT_MO_OnePedalDriving_integriert, compu {0=Cx0_OPD_nicht_integriert (CM_MO_OnePedalDriving_integriert_Cx0_OPD_nicht_integriert), 1=Cx1_OPD_integriert (CM_MO_OnePedalDriving_integriert_Cx1_OPD_integriert)}, range raw 0..1, transfer-property=PENDING  # Zeigt an, dass das Antriebssteuergerät die Funktion OnePedalDriving unterstützt.
          signal MO_Klima_Regelmodus_XIX_Motor_54_XIX_E3V_EVCANFD: start 74, 2 bit, little-endian, data-type-policy=OVERRIDE, i-signal-type=PRIMITIVE, init-value=0, base-type=BT_MO_Klima_Regelmodus, compu {0=Cx0_Init (CM_MO_Klima_Regelmodus_Cx0_Init), 1=Cx1_Regelmodus_1 (CM_MO_Klima_Regelmodus_Cx1_Regelmodus_1), 2=Cx2_Regelmodus_2 (CM_MO_Klima_Regelmodus_Cx2_Regelmodus_2), 3=Cx3_Regelmodus_3 (CM_MO_Klima_Regelmodus_Cx3_Regelmodus_3)}, range raw 0..3, transfer-property=PENDING, to Klima(timeout 1 s)  # Anforderung an Klima SG zur Regelungsanpassung der HV Klimakomponenten bei bestimmten Umweltbedingungen
          signal MO_Fahrbereitschaft_XIX_Motor_54_XIX_E3V_EVCANFD: start 76, 2 bit, little-endian, data-type-policy=OVERRIDE, i-signal-type=PRIMITIVE, init-value=0, base-type=BT_MO_Fahrbereitschaft, compu {0=Cx0_Fahrzykl_inaktiv_kein_Antrieb (CM_MO_Fahrbereitschaft_Cx0_Fahrzykl_inaktiv_kein_Antrieb) (Fahrzykl_inaktiv__kein_Antrieb), 1=Cx1_Fahrzykl_aktiv_kein_Antrieb (CM_MO_Fahrbereitschaft_Cx1_Fahrzykl_aktiv_kein_Antrieb) (Fahrzykl_aktiv__kein_Antrieb), 2=Cx2_Fahrzykl_aktiv_Antrieb_moeglich (CM_MO_Fahrbereitschaft_Cx2_Fahrzykl_aktiv_Antrieb_moeglich) (Fahrzykl_aktiv__Antrieb_moeglich)}, range raw 0..2, transfer-property=TRIGGERED-ON-CHANGE-WITHOUT-REPETITION  # Das Signal MO_Fahrbereitschaft zeigt in mehreren Stufen an, ob der Motor in einem anfahrbereiten Zustand ist.
          signal MO_Freilauf_Info_XIX_Motor_54_XIX_E3V_EVCANFD: start 78, 2 bit, little-endian, data-type-policy=OVERRIDE, i-signal-type=PRIMITIVE, init-value=0, base-type=BT_MO_Freilauf_Info, compu {0=Cx0_Freilauf_freigegeben (CM_MO_Freilauf_Info_Cx0_Freilauf_freigegeben), 1=Cx1_Weiches_Veto_uebertippbar (CM_MO_Freilauf_Info_Cx1_Weiches_Veto_uebertippbar), 2=Cx2_Hartes_Veto_Abbruch (CM_MO_Freilauf_Info_Cx2_Hartes_Veto_Abbruch), 3=Cx3_Freilauf_Anforderung (CM_MO_Freilauf_Info_Cx3_Freilauf_Anforderung)}, range raw 0..3, transfer-property=TRIGGERED-ON-CHANGE-WITHOUT-REPETITION  # Freilauf Informationssignal vom Motorsteuergerät zum Getriebesteuergerät. Das Motorsteuergerät kann über dieses Signal den Freilauf freigeben, verhindern bzw. explizit anfordern.
          signal MO_Krit_Heckobjekt_XIX_Motor_54_XIX_E3V_EVCANFD: start 81, 3 bit, little-endian, data-type-policy=OVERRIDE, i-signal-type=PRIMITIVE, init-value=0, base-type=BT_MO_Krit_Heckobjekt, invalid-value=Invalid_MO_Krit_Heckobjekt_XIX_Motor_54_XIX_E3V_EVCANFD:7, compu {0=Cx0_Init_kein_relevantes_Objekt (CM_MO_Krit_Heckobjekt_Cx0_Init_kein_relevantes_Objekt), 1=Cx1_Entfernung_grosser_Abstand (CM_MO_Krit_Heckobjekt_Cx1_Entfernung_grosser_Abstand), 2=Cx2_Annaeherung_grosser_Abstand (CM_MO_Krit_Heckobjekt_Cx2_Annaeherung_grosser_Abstand), 3=Cx3_Entfernung_geringer_Abstand (CM_MO_Krit_Heckobjekt_Cx3_Entfernung_geringer_Abstand), 4=Cx4_Annaeherung_geringer_Abstand (CM_MO_Krit_Heckobjekt_Cx4_Annaeherung_geringer_Abstand), 7=Cx7_Fehler (CM_MO_Krit_Heckobjekt_Cx7_Fehler)}, range raw 0..7, transfer-property=PENDING  # Beschreibt die Kritikalität des hinter einem in der Spur fahrenden Fahrzeuges
          signal MO_NGS_Gangpos_XIX_Motor_54_XIX_E3V_EVCANFD: start 84, 3 bit, little-endian, data-type-policy=OVERRIDE, i-signal-type=PRIMITIVE, init-value=0, base-type=BT_MO_NGS_Gangpos, invalid-value=Invalid_MO_NGS_Gangpos_XIX_Motor_54_XIX_E3V_EVCANFD:7, compu {0=Cx0_nicht_bedient (CM_MO_NGS_Gangpos_Cx0_nicht_bedient), 1=Cx1_1_3_oder_5 (CM_MO_NGS_Gangpos_Cx1_1_3_oder_5), 2=Cx2_2_4_6_oder_R (CM_MO_NGS_Gangpos_Cx2_2_4_6_oder_R), 3=Cx3_R (CM_MO_NGS_Gangpos_Cx3_R), 4=Cx4_Neutralposition (CM_MO_NGS_Gangpos_Cx4_Neutralposition), 5=Cx5_Zwischenposition (CM_MO_NGS_Gangpos_Cx5_Zwischenposition), 6=Cx6_Sensor_temp_nicht_verfuegbar (CM_MO_NGS_Gangpos_Cx6_Sensor_temp_nicht_verfuegbar), 7=Cx7_Fehler (CM_MO_NGS_Gangpos_Cx7_Fehler)}, range raw 0..7, transfer-property=TRIGGERED-ON-CHANGE-WITHOUT-REPETITION  # Gang- bzw. Neutralinformation des erweiterten Neutralgangsensors. Bedingt durch den eingeschränkten Erfassungssbereich des Sensors sind die Ganginformationen als eingelegt bzw. fast eingelegt/vorausgewählt zu interpretieren (nur Handschalter)
          signal MO_Freilauf_Status_XIX_Motor_54_XIX_E3V_EVCANFD: start 87, 3 bit, little-endian, data-type-policy=OVERRIDE, i-signal-type=PRIMITIVE, init-value=0, base-type=BT_MO_Freilauf_Status, invalid-value=Invalid_MO_Freilauf_Status_XIX_Motor_54_XIX_E3V_EVCANFD:7, compu {0=Cx0_Freilauf_inaktiv_aber_moeglich (CM_MO_Freilauf_Status_Cx0_Freilauf_inaktiv_aber_moeglich), 1=Cx1_Freilauf_aktiv (CM_MO_Freilauf_Status_Cx1_Freilauf_aktiv), 2=Cx2_Freilauf_nicht_moegl_1Verhinderer (CM_MO_Freilauf_Status_Cx2_Freilauf_nicht_moegl_1Verhinderer), 3=Cx3_Freilauf_nicht_moegl_gr_1Verhinderer (CM_MO_Freilauf_Status_Cx3_Freilauf_nicht_moegl_gr_1Verhinderer), 7=Cx7_Fehler (CM_MO_Freilauf_Status_Cx7_Fehler)}, range raw 0..7, transfer-property=TRIGGERED-ON-CHANGE-WITHOUT-REPETITION  # Freilauf-Status-Signal vom Frailauf-Master an aktive Freilauf-Teilnehmer. In diesem Signal zeigt der Freilauf-Master an, welchen aktuellen Status die Freilauf-Betriebsstrategie hat.
          signal MO_EBoost_verf_praed_XIX_Motor_54_XIX_E3V_EVCANFD: start 90, 2 bit, little-endian, data-type-policy=OVERRIDE, i-signal-type=PRIMITIVE, init-value=0, base-type=BT_MO_EBoost_verf_praed, compu {0=Cx0_Init_oder_nicht_verfuegbar (CM_MO_EBoost_verf_praed_Cx0_Init_oder_nicht_verfuegbar), 1=Cx1_EBoost_kurzzeit_verfuegbar (CM_MO_EBoost_verf_praed_Cx1_EBoost_kurzzeit_verfuegbar), 2=Cx2_EBoost_langzeit_verfuegbar (CM_MO_EBoost_verf_praed_Cx2_EBoost_langzeit_verfuegbar)}, range raw 0..2, transfer-property=PENDING  # Zeigt an, ob für eine im Projekt definierte Zeit (max. 10s) E-Boost in Höhe von EM1_maxPred_Moment verfügbar sein wird. 0 - Init_oder_nicht_verfügbar 1 - EBoost_kurzzeit_verfügbar (~3Sek.) 2 - EBoost_langzeit_verfügbar (~10Sek)
          signal MO_Heckspoiler_Anf_XIX_Motor_54_XIX_E3V_EVCANFD: start 92, 1 bit, little-endian, data-type-policy=OVERRIDE, i-signal-type=PRIMITIVE, init-value=0, base-type=BT_MO_Heckspoiler_Anf, compu {0=Cx0_nicht_angefordert (CM_MO_Heckspoiler_Anf_Cx0_nicht_angefordert), 1=Cx1_angefordert (CM_MO_Heckspoiler_Anf_Cx1_angefordert)}, range raw 0..1, transfer-property=PENDING  # Anforderung den Heckspoiler zur Ladeluft- bzw. Motorraumkühlung auszufahren.
          signal MO_eLaunch_verf_XIX_Motor_54_XIX_E3V_EVCANFD: start 93, 2 bit, little-endian, data-type-policy=OVERRIDE, i-signal-type=PRIMITIVE, init-value=0, base-type=BT_MO_eLaunch_verf, compu {0=Cx0_Init (CM_MO_eLaunch_verf_Cx0_Init), 1=Cx1_nicht_verfuegbar (CM_MO_eLaunch_verf_Cx1_nicht_verfuegbar), 2=Cx2_verfuegbar (CM_MO_eLaunch_verf_Cx2_verfuegbar)}, range raw 0..2, transfer-property=PENDING  # Zeigt an, ob aus Antriebssicht E-Launch verfügbar ist.
          signal MO_Positionierung_aktiv_XIX_Motor_54_XIX_E3V_EVCANFD: start 95, 1 bit, little-endian, data-type-policy=OVERRIDE, i-signal-type=PRIMITIVE, init-value=0, base-type=BT_MO_Positionierung_aktiv, compu {0=Cx0_keine_Positionierung_aktiv (CM_MO_Positionierung_aktiv_Cx0_keine_Positionierung_aktiv), 1=Cx1_Positionierung_aktiv (CM_MO_Positionierung_aktiv_Cx1_Positionierung_aktiv)}, range raw 0..1, transfer-property=PENDING  # Zeigt an, dass die Motorpositionierung mit Hilfe des Riemenstartergenerator momentan aktiv ist.
          signal MO_Startwunsch_XIX_Motor_54_XIX_E3V_EVCANFD: start 100, 1 bit, little-endian, data-type-policy=OVERRIDE, i-signal-type=PRIMITIVE, init-value=0, base-type=BT_MO_Startwunsch, compu {0=Cx0_kein_Startwunsch (CM_MO_Startwunsch_Cx0_kein_Startwunsch), 1=Cx1_Startwunsch (CM_MO_Startwunsch_Cx1_Startwunsch)}, range raw 0..1, transfer-property=TRIGGERED-ON-CHANGE-WITHOUT-REPETITION  # o Setzen bei Erfüllung der kompletten Fahrerbedienhandlung (z.B. Zündanlasstaster + Bremse + Fahrstufe P/N [klassisch] oder Fahrstufe D/R + Bremse [MEB]), je nach Fahrzeug z.T. bereits vor oder immer erst nach Einschalten der Klemme 15; o Rücksetzen bei Startausführung, bei Nichterfüllung der Startvoraussetzungen vor der Startausführung (z.B. Verlassen Bremspedal), bei Verhinderungsgrund (z.B. gesteckter Ladestecker, Diebstahlschutz) sowie bei Timeout (Ausbleiben von Freigabebedingungen, z.B. Klemme 15, WFS, Ladesteckerstatus etc.) o nie gesetzt bei konventionellem Start
          signal OBDProtocol_req_XIX_Motor_54_XIX_E3V_EVCANFD: start 112, 4 bit, little-endian, data-type-policy=OVERRIDE, i-signal-type=PRIMITIVE, base-type=BT_OBDProtocol_req, invalid-value=Invalid_OBDProtocol_req_XIX_Motor_54_XIX_E3V_EVCANFD:15, compu {0=Cx0_not_available (CM_OBDProtocol_req_Cx0_not_available), 1=Cx1_OBDclassic (CM_OBDProtocol_req_Cx1_OBDclassic), 2=Cx2_OBDonUDS (CM_OBDProtocol_req_Cx2_OBDonUDS), 3=Cx3_ZEVonUDS (CM_OBDProtocol_req_Cx3_ZEVonUDS), 14=Cxe_Init (CM_OBDProtocol_req_Cxe_Init), 15=Cxf_Fehler (CM_OBDProtocol_req_Cxf_Fehler)}, range raw 0..15, transfer-property=PENDING, to Klima(timeout 1 s)  # OBD protocol information 'used OBD protocol' from MIL master
          signal MO_Anforderung_Anzeige_Halten_XIX_Motor_54_XIX_E3V_EVCANFD: start 120, 1 bit, little-endian, data-type-policy=OVERRIDE, i-signal-type=PRIMITIVE, init-value=0, base-type=BT_MO_Anforderung_Anzeige_Halten, compu {0=Cx0_Keine_Anzeige_Halten (CM_MO_Anforderung_Anzeige_Halten_Cx0_Keine_Anzeige_Halten), 1=Cx1_Anzeige_Halten (CM_MO_Anforderung_Anzeige_Halten_Cx1_Anzeige_Halten)}, range raw 0..1, transfer-property=TRIGGERED-ON-CHANGE-WITHOUT-REPETITION  # Statusanzeige, ob "Hold"-Anzeige aktiv werden soll. Im Status Halten wird die "Hold" Anzeige aktiviert. Im Status Rückrollsicherung wird die "Hold" Anzeige nicht aktiviert.
          signal KVA_Ist_Pos_XIX_Motor_54_XIX_E3V_EVCANFD: start 121, 7 bit, little-endian, data-type-policy=OVERRIDE, i-signal-type=PRIMITIVE, init-value=126, base-type=BT_KVA_Ist_Pos, invalid-value=Invalid_KVA_Ist_Pos_XIX_Motor_54_XIX_E3V_EVCANFD:127, compu {phys=raw for raw 0..100, 125=Cx7d_SKE_nicht_verbaut (CM_KVA_Ist_Pos_Cx7d_SKE_nicht_verbaut), 126=Cx7e_Init (CM_KVA_Ist_Pos_Cx7e_Init), 127=Cx7f_Fehler (CM_KVA_Ist_Pos_Cx7f_Fehler); unit Unit_PerCent}, range phys 0..100 Unit_PerCent, raw 0..127, unit=Unit_PerCent, transfer-property=PENDING, to Klima(timeout 1 s)  # KVA Istpositionsrückmeldung
          signal OBD_Calc_Load_Val_XIX_Motor_54_XIX_E3V_EVCANFD: start 128, 8 bit, little-endian, data-type-policy=OVERRIDE, i-signal-type=PRIMITIVE, init-value=255, base-type=BT_OBD_Calc_Load_Val, compu {phys=raw*0.3921568627 for raw 0..255; unit Unit_PerCent}, range phys 0..100 Unit_PerCent, raw 0..255, unit=Unit_PerCent, transfer-property=PENDING, to Klima(timeout 1 s)  # Calculated Load Value Übertragung von Meßgrößen an das Getriebesteuergerät für Freeze Frame Abspeicherung bei Getriebefehlern PID $04 Calculated Load Value; 0 .. 100% mit 100/255 % per bit
          signal OBD_Eng_Cool_Temp_XIX_Motor_54_XIX_E3V_EVCANFD: start 136, 8 bit, little-endian, data-type-policy=OVERRIDE, i-signal-type=PRIMITIVE, init-value=255, base-type=BT_OBD_Eng_Cool_Temp, compu {phys=raw-40 for raw 0..255; unit Unit_DegreCelsi}, range phys -40..215 Unit_DegreCelsi, raw 0..255, unit=Unit_DegreCelsi, transfer-property=PENDING, to Klima(timeout 1 s)  # Engine Coolant Temperature Übertragung von Meßgrößen an das Getriebesteuergerät für Freeze Frame Abspeicherung bei Getriebefehlern PID $05 Engine Coolant Temperature; -40 .. +215°C mit 1°C/bit und 40°C Offset
          signal OBD_Abs_Throttle_Pos_XIX_Motor_54_XIX_E3V_EVCANFD: start 144, 8 bit, little-endian, data-type-policy=OVERRIDE, i-signal-type=PRIMITIVE, init-value=255, base-type=BT_OBD_Abs_Throttle_Pos, compu {phys=raw*0.3921568627 for raw 0..255; unit Unit_PerCent}, range phys 0..100 Unit_PerCent, raw 0..255, unit=Unit_PerCent, transfer-property=PENDING, to Klima(timeout 1 s)  # Absolute Throttle Position Übertragung von Meßgrößen an das Getriebesteuergerät für Freeze Frame Abspeicherung bei Getriebefehlern PID $11 Absolute Throttle Position; 0 .. 100% mit 100/255 %/bit
          signal OBD_Abs_Load_Val_XIX_Motor_54_XIX_E3V_EVCANFD: start 152, 16 bit, little-endian, data-type-policy=OVERRIDE, i-signal-type=PRIMITIVE, init-value=65535, base-type=BT_OBD_Abs_Load_Val, compu {phys=raw*0.3921568627 for raw 0..65535; unit Unit_PerCent}, range phys 0..25700 Unit_PerCent, raw 0..65535, unit=Unit_PerCent, transfer-property=PENDING, to Klima(timeout 1 s)  # Absolute Load Value Übertragung von Meßgrößen an das Getriebesteuergerät für Freeze Frame Abspeicherung bei Getriebefehlern PID $43 Absolute Load Value; 0 .. 25700% mit 100/255 %/bit
          signal OBD_Abs_Pedal_Pos_XIX_Motor_54_XIX_E3V_EVCANFD: start 168, 8 bit, little-endian, data-type-policy=OVERRIDE, i-signal-type=PRIMITIVE, init-value=255, base-type=BT_OBD_Abs_Pedal_Pos, compu {phys=raw*0.3921568627 for raw 0..255; unit Unit_PerCent}, range phys 0..100 Unit_PerCent, raw 0..255, unit=Unit_PerCent, transfer-property=PENDING, to Klima(timeout 1 s)  # Absolute Pedal Position Übertragung von Meßgrößen an das Getriebesteuergerät für Freeze Frame Abspeicherung bei Getriebefehlern PID $49 Accelerator Pedal Position D; 0 .. 100% mit 100/255 %/bit
          signal MO_Servicemodus_XIX_Motor_54_XIX_E3V_EVCANFD: start 176, 4 bit, little-endian, data-type-policy=OVERRIDE, i-signal-type=PRIMITIVE, init-value=0, base-type=BT_MO_Servicemodus, compu {0=Cx0_nicht_aktiv (CM_MO_Servicemodus_Cx0_nicht_aktiv), 1=Cx1_Service_Mode_1 (CM_MO_Servicemodus_Cx1_Service_Mode_1), 2=Cx2_Service_Mode_2 (CM_MO_Servicemodus_Cx2_Service_Mode_2), 3=Cx3_Service_Mode_3 (CM_MO_Servicemodus_Cx3_Service_Mode_3), 4=Cx4_Service_Mode_4 (CM_MO_Servicemodus_Cx4_Service_Mode_4), 5=Cx5_Service_Mode_5 (CM_MO_Servicemodus_Cx5_Service_Mode_5), 6=Cx6_Service_Mode_6 (CM_MO_Servicemodus_Cx6_Service_Mode_6), 7=Cx7_Service_Mode_7 (CM_MO_Servicemodus_Cx7_Service_Mode_7), 8=Cx8_Service_Mode_8 (CM_MO_Servicemodus_Cx8_Service_Mode_8), 9=Cx9_Service_Mode_9 (CM_MO_Servicemodus_Cx9_Service_Mode_9), 10=Cxa_Service_Mode_10 (CM_MO_Servicemodus_Cxa_Service_Mode_10), 11=Cxb_Service_Mode_11 (CM_MO_Servicemodus_Cxb_Service_Mode_11), 12=Cxc_Service_Mode_12 (CM_MO_Servicemodus_Cxc_Service_Mode_12), 13=Cxd_Service_Mode_13 (CM_MO_Servicemodus_Cxd_Service_Mode_13), 14=Cxe_Service_Mode_14 (CM_MO_Servicemodus_Cxe_Service_Mode_14), 15=Cxf_Service_Mode_15 (CM_MO_Servicemodus_Cxf_Service_Mode_15)}, range raw 0..15, transfer-property=PENDING  # Ausgabe aktiver Service-Mode
          signal MO_FoD_Performance_Status_XIX_Motor_54_XIX_E3V_EVCANFD: start 181, 2 bit, little-endian, data-type-policy=OVERRIDE, i-signal-type=PRIMITIVE, init-value=0, base-type=BT_MO_FoD_Performance_Status, compu {0=Cx0_init (CM_MO_FoD_Performance_Status_Cx0_init), 1=Cx1_notPossible (CM_MO_FoD_Performance_Status_Cx1_notPossible), 2=Cx2_notActivated (CM_MO_FoD_Performance_Status_Cx2_notActivated), 3=Cx3_activated (CM_MO_FoD_Performance_Status_Cx3_activated)}, range raw 0..3, transfer-property=TRIGGERED-ON-CHANGE-WITHOUT-REPETITION  # Aktueller Fahrzeug Performanceupgrade Status
          signal OBD_ClearMem_Inhibit_XIX_Motor_54_XIX_E3V_EVCANFD: start 183, 1 bit, little-endian, data-type-policy=OVERRIDE, i-signal-type=PRIMITIVE, init-value=0, base-type=BT_OBD_ClearMem_Inhibit, compu {0=Cx0_FSP_Loeschen_zulaessig (CM_OBD_ClearMem_Inhibit_Cx0_FSP_Loeschen_zulaessig), 1=Cx1_FSP_Loeschen_nicht_zulaessig (CM_OBD_ClearMem_Inhibit_Cx1_FSP_Loeschen_nicht_zulaessig)}, range raw 0..1, transfer-property=PENDING  # Bei FSP_Loeschen_zulässig müssen alle OBD-ECUs im Gesamtfahrzeug einen Service 04hex Request (Ereignisspeicher löschen) korrekt ausführen. In MLB-, MLBevo-, MQB-Fahrzeugkonzepten muss der MIL-Master/Motorsteuergerät bei Kl.15 ein, projektabhängig, konstant OBD_ClearMem_Inhibit = 0 senden, sofern das Löschen des Ereignisspeichers noch in jedem Betriebszustand (auch bei laufendem Motor, etc.) gefordert ist. Projektspezifisch im MLB-, MLBevo-, und MQB-Fahrzeugkonzepten und vollumfänglich in MQB_37W- und MLB3-Fahrzeugkonzepten wird das Ereignisspeicher löschen in allen OBD-ECUs auf den Betriebszustand stehendes Fahrzeug und stehender Motor beschränkt und die entsprechende Freigabe das Ereignisspeicher Löschens vom MIL-Master über das Bussignal OBD_ClearMem_Inhibit für alle anderen OBD-ECUs im Gesamtfahrzeug signalisiert. Hinweis: Steuergerät- oder Komponentenspezifische Randbedingungen sind unter Abhängigkeit des Sicherheitskonzepts zu prüfen und zu bewerten.
          signal OBD_Sperrung_Kaltstart_Denom_XIX_Motor_54_XIX_E3V_EVCANFD: start 184, 1 bit, little-endian, data-type-policy=OVERRIDE, i-signal-type=PRIMITIVE, init-value=0, base-type=BT_OBD_Sperrung_Kaltstart_Denom, compu {0=Cx0_EVAP_Berechnung_freigegeben (CM_OBD_Sperrung_Kaltstart_Denom_Cx0_EVAP_Berechnung_freigegeben), 1=Cx1_EVAP_Berechnung_gesperrt (CM_OBD_Sperrung_Kaltstart_Denom_Cx1_EVAP_Berechnung_gesperrt)}, range raw 0..1, transfer-property=PENDING  # Information vom MIL Master, dass die Bildung des EVAP Denominators im Motor nicht möglich ist und damit der noECM-Denominator gesperrt werden darf.
          signal MO_QBit_Aussen_Temp_XIX_Motor_54_XIX_E3V_EVCANFD: start 185, 1 bit, little-endian, data-type-policy=OVERRIDE, i-signal-type=PRIMITIVE, init-value=1, base-type=BT_MO_QBit_Aussen_Temp, compu {0=Cx0_gueltiger_Wert (CM_MO_QBit_Aussen_Temp_Cx0_gueltiger_Wert), 1=Cx1_Ersatz_Init_oder_Fehlerwert (CM_MO_QBit_Aussen_Temp_Cx1_Ersatz_Init_oder_Fehlerwert)}, range raw 0..1, transfer-property=PENDING, to Klima(timeout 1 s)  # QBit der Aussentemperatur. Gesetzt bei Ersatzwert, Init oder Fehler.
          signal OBD_Sperrung_IUMPR_XIX_Motor_54_XIX_E3V_EVCANFD: start 186, 1 bit, little-endian, data-type-policy=OVERRIDE, i-signal-type=PRIMITIVE, init-value=0, base-type=BT_OBD_Sperrung_IUMPR, compu {0=Cx0_IUMPR_Berechnung_freigegeben (CM_OBD_Sperrung_IUMPR_Cx0_IUMPR_Berechnung_freigegeben), 1=Cx1_IUMPR_Berechnung_gesperrt (CM_OBD_Sperrung_IUMPR_Cx1_IUMPR_Berechnung_gesperrt)}, range raw 0..1, transfer-property=PENDING, to Klima(timeout 1 s)  # Wenn der General Denominator auf Grund eines Fehlers in den Eingangsgrößen gesperrt wird, wird diese Information über Bussystem als OBD-Statusinformation OBD_Sperrung_IUMPR für andere OBD-Steuergeräte bereitgestellt. Das MSG (MIL-Master) setzt dieses Bit, wenn auf Grund vorliegender Sperrbedingungen keine Inkrementierung des GeneralDenominator mehr stattfindet. Im Empfänger-SG ist entsprechend die Inkrementierung des oder der Numeratoren einzufrieren.
          signal OBD_Kaltstart_Denominator_XIX_Motor_54_XIX_E3V_EVCANFD: start 187, 1 bit, little-endian, data-type-policy=OVERRIDE, i-signal-type=PRIMITIVE, init-value=0, base-type=BT_OBD_Kaltstart_Denominator, compu {0=Cx0_Denominator_nicht_hochzaehlen (CM_OBD_Kaltstart_Denominator_Cx0_Denominator_nicht_hochzaehlen), 1=Cx1_Bedingungen_zum_Inkr_des_Kaltstart_Denom_erf (CM_OBD_Kaltstart_Denominator_Cx1_Bedingungen_zum_Inkr_des_Kaltstart_Denom_erf)}, range raw 0..1, transfer-property=PENDING, to Klima(timeout 1 s)  # Bestimmte Diagnosen werden nur unter Kaltstartbedingungen durchgeführt, der entsprechende Denominator bei IUMPR-pflichtigen Systemen wird anhand dieses vom MSG gebildeten Signals inkrementiert. (Entspricht EVAP-Denominator)
          signal OBD_Minimum_Trip_XIX_Motor_54_XIX_E3V_EVCANFD: start 188, 1 bit, little-endian, data-type-policy=OVERRIDE, i-signal-type=PRIMITIVE, init-value=0, base-type=BT_OBD_Minimum_Trip, compu {0=Cx0_kein_Min_Normed_Trip (CM_OBD_Minimum_Trip_Cx0_kein_Min_Normed_Trip), 1=Cx1_Min_Normed_Trip (CM_OBD_Minimum_Trip_Cx1_Min_Normed_Trip)}, range raw 0..1, transfer-property=PENDING, to Klima(timeout 1 s)  # Grundlage OBD-Gesetz CCR 1968.2 (d)(4.3) Denominator Specifications Bildung des General Denominator "Normed Trip": 600 sec. (kumulativ) Zeit nach Motorstart 300 sec. (kumulativ) mit Fahrzeuggeschwindigkeit > 25 mph (40 km/h) 30 sec. (kontinuierlich) Leerlauf Wenn alle diese Bedingungen erfüllt wurden ist ein OBD_Min_Normed_Trip erfüllt
          signal OBD_Driving_Cycle_XIX_Motor_54_XIX_E3V_EVCANFD: start 189, 1 bit, little-endian, data-type-policy=OVERRIDE, i-signal-type=PRIMITIVE, init-value=0, base-type=BT_OBD_Driving_Cycle, compu {0=Cx0_kein_Driving_Cycle_erkannt (CM_OBD_Driving_Cycle_Cx0_kein_Driving_Cycle_erkannt), 1=Cx1_Driving_Cycle_erkannt (CM_OBD_Driving_Cycle_Cx1_Driving_Cycle_erkannt)}, range raw 0..1, transfer-property=PENDING, to Klima(timeout 1 s)  # Signalisierung Driving Cycle Qualifizierung - Trigger Ignition Cycle Counter
          signal OBD_Warm_Up_Cycle_XIX_Motor_54_XIX_E3V_EVCANFD: start 190, 1 bit, little-endian, data-type-policy=OVERRIDE, i-signal-type=PRIMITIVE, init-value=0, base-type=BT_OBD_Warm_Up_Cycle, compu {0=Cx0_kein_Warm_Up_Cycle_erkannt (CM_OBD_Warm_Up_Cycle_Cx0_kein_Warm_Up_Cycle_erkannt), 1=Cx1_Warm_Up_Cycle_erkannt (CM_OBD_Warm_Up_Cycle_Cx1_Warm_Up_Cycle_erkannt)}, range raw 0..1, transfer-property=PENDING, to Klima(timeout 1 s)  # Mit dem Warm-Up-Cycle wird der zentrale Verlernzähler vom Gateway inkrementiert
          signal OBD_Normed_Trip_XIX_Motor_54_XIX_E3V_EVCANFD: start 191, 1 bit, little-endian, data-type-policy=OVERRIDE, i-signal-type=PRIMITIVE, init-value=0, base-type=BT_OBD_Normed_Trip, compu {0=Cx0_kein_Normed_Trip (CM_OBD_Normed_Trip_Cx0_kein_Normed_Trip), 1=Cx1_Normed_Trip (CM_OBD_Normed_Trip_Cx1_Normed_Trip)}, range raw 0..1, transfer-property=PENDING, to Klima(timeout 1 s)  # Gesetzlich definierte "Normed Condition" erfüllt, "General Denominator" darf erhöht werden
          signal MO_FoD_Performance_Switch_Status_XIX_Motor_54_XIX_E3V_EVCANFD: start 234, 3 bit, little-endian, data-type-policy=OVERRIDE, i-signal-type=PRIMITIVE, init-value=0, base-type=BT_MO_FoD_Performance_Switch_Status, compu {0=Cx0_init (CM_MO_FoD_Performance_Switch_Status_Cx0_init), 1=Cx1_notActiv (CM_MO_FoD_Performance_Switch_Status_Cx1_notActiv), 2=Cx2_changeInProgress (CM_MO_FoD_Performance_Switch_Status_Cx2_changeInProgress), 3=Cx3_changeFailedRetryInNextClampCycl (CM_MO_FoD_Performance_Switch_Status_Cx3_changeFailedRetryInNextClampCycl), 4=Cx4_changeFailed (CM_MO_FoD_Performance_Switch_Status_Cx4_changeFailed)}, range raw 0..4, transfer-property=TRIGGERED-ON-CHANGE-WITHOUT-REPETITION  # Status zum Wechsel des Performance upgrades
          signal MO_UBE_Reserve_XIX_Motor_54_XIX_E3V_EVCANFD: start 238, 10 bit, little-endian, data-type-policy=OVERRIDE, i-signal-type=PRIMITIVE, init-value=1023, base-type=BT_MO_UBE_Reserve, compu {phys=raw*5 for raw 0..1022, 1023=Cx3ff_Init (CM_MO_UBE_Reserve_Cx3ff_Init); unit Unit_WattHour}, range phys 0..5110 Unit_WattHour, raw 0..1023, unit=Unit_WattHour, transfer-property=PENDING  # Seitens Antrieb erforderliche Energiereserve der HV-Batterie, die den Fußpunkt der „Usable Battery Energy“ (BMS_UBE) verschiebt. Die Reserve dient der Gewährleistung von Sicherheitsfunktionen und ggf. Emissionierungsmaßnahmen unterhalb des Fahrbetriebs im EV-Mode eines Hybridfahrzeuges bzw. dem regulären Fahrbetrieb eines Elektrofahrzeuges. Der Reservewert ist für eine Homologation (z.B. Interpolationsfamilie der WLTP Homologation) fest definiert.
          signal OBD_Aussen_Temp_gef_XIX_Motor_54_XIX_E3V_EVCANFD: start 248, 8 bit, little-endian, data-type-policy=OVERRIDE, i-signal-type=PRIMITIVE, init-value=254, base-type=BT_OBD_Aussen_Temp_gef, invalid-value=Invalid_OBD_Aussen_Temp_gef_XIX_Motor_54_XIX_E3V_EVCANFD:255, compu {phys=raw-40 for raw 0..253, 254=Cxfe_Initwert (CM_OBD_Aussen_Temp_gef_Cxfe_Initwert), 255=Cxff_Fehler (CM_OBD_Aussen_Temp_gef_Cxff_Fehler); unit Unit_DegreCelsi}, range phys -40..213 Unit_DegreCelsi, raw 0..255, unit=Unit_DegreCelsi, transfer-property=PENDING  # Gefilterte Aussentemperatur vom Motor für OBD Funktionen.
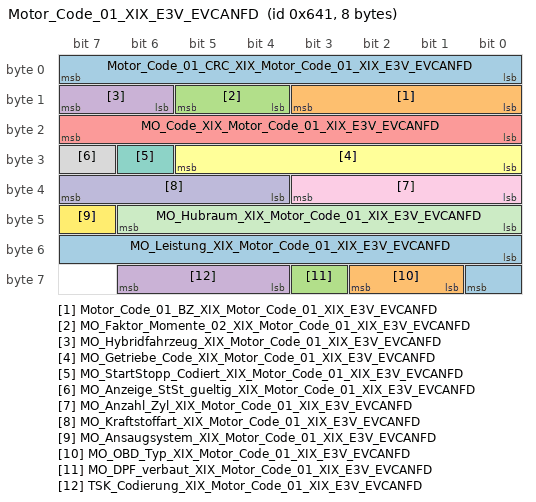
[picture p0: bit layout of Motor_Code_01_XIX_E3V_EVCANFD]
      frame Motor_Code_01_XIX_E3V_EVCANFD: id 0x641, to Klima, frame-length=8, can-addressing-mode=STANDARD, can-frame-rx-behavior=CAN-FD, can-frame-tx-behavior=CAN-FD
        pdu Motor_Code_01_XIX_E3V_EVCANFD: length=8, transmission-mode-true-timing=cyclic-timing={time-offset=0.0, time-period=1.0}, unused-bit-pattern=0  # ab MQB mit CRC-8
          signal Motor_Code_01_CRC_XIX_Motor_Code_01_XIX_E3V_EVCANFD: start 0, 8 bit, little-endian, data-type-policy=OVERRIDE, i-signal-type=PRIMITIVE, base-type=BT_Motor_Code_01_CRC, compu {phys=raw for raw 0..255}, range phys 0..255, raw 0..255, transfer-property=PENDING  # Für MLB: "Berechnung siehe Lastenheft "Kommunikationsabsicherung für FlexRay und CAN"" Ab MQB und MLBevo: "Berechnung siehe Lastenheft "End-to-End Kommunikationsabsicherung"" Endwerte siehe Begleitdokument "S-PDU Kennungsfolgen"
          signal Motor_Code_01_BZ_XIX_Motor_Code_01_XIX_E3V_EVCANFD: start 8, 4 bit, little-endian, data-type-policy=OVERRIDE, i-signal-type=PRIMITIVE, base-type=BT_Motor_Code_01_BZ, compu {phys=raw for raw 0..15}, range phys 0..15, raw 0..15, transfer-property=PENDING
          signal MO_Faktor_Momente_02_XIX_Motor_Code_01_XIX_E3V_EVCANFD: start 12, 2 bit, little-endian, data-type-policy=OVERRIDE, i-signal-type=PRIMITIVE, base-type=BT_MO_Faktor_Momente_02, compu {0=Cx0_nicht_belegt (CM_MO_Faktor_Momente_02_Cx0_nicht_belegt), phys=raw for raw 1..3; unit Unit_NewtoMeter}, range phys 1..3 Unit_NewtoMeter, raw 0..3, unit=Unit_NewtoMeter, transfer-property=PENDING  # Dieses Signal schaltet den Wertebereich aller Momente vom Motor, Getriebe, TSK, Bremse ... um! Die Momente besitzen somit einen variablen Wertebereich, weil sich durch den Faktor die Momente sowohl in Auflösung als auch Maximalwerten ändert. 0x0 nicht belegt 0x1 Faktor x 1 Nm 0x2 Faktor x 2 Nm 0x3 Faktor x 3 Nm Defaultwert ist 0x3. Dieser Wert muss angenommen werden wenn für Empfänger kein Signal "MO_Fakor_Momente_02" zur Verfügung steht.
          signal MO_Hybridfahrzeug_XIX_Motor_Code_01_XIX_E3V_EVCANFD: start 14, 2 bit, little-endian, data-type-policy=OVERRIDE, i-signal-type=PRIMITIVE, base-type=BT_MO_Hybridfahrzeug, compu {0=Cx0_kein_Hybridfahrzeug (CM_MO_Hybridfahrzeug_Cx0_kein_Hybridfahrzeug), 1=Cx1_Mild_Hybrid (CM_MO_Hybridfahrzeug_Cx1_Mild_Hybrid), 2=Cx2_Full_Hybrid (CM_MO_Hybridfahrzeug_Cx2_Full_Hybrid), 3=Cx3_PlugIn_Hybrid (CM_MO_Hybridfahrzeug_Cx3_PlugIn_Hybrid)}, range raw 0..3, transfer-property=PENDING, to Klima(timeout 5 s)  # Anhand dieses Signals plausibilisiert die Lenkhilfe das Bit Fahrbereitschaft. Im Projekt Cayenne PHEV (und ggf. auch VW526 PHEV) ist aus Gründen der Abwärtskompatibilität der Wert "2" zu senden.
          signal MO_Code_XIX_Motor_Code_01_XIX_E3V_EVCANFD: start 16, 8 bit, little-endian, data-type-policy=OVERRIDE, i-signal-type=PRIMITIVE, init-value=0, base-type=BT_MO_Code, compu {phys=raw for raw 0..255}, range phys 0..255, raw 0..255, transfer-property=PENDING  # Motorcodierinformation Version 16 (Details siehe Anhang)
          signal MO_Getriebe_Code_XIX_Motor_Code_01_XIX_E3V_EVCANFD: start 24, 6 bit, little-endian, data-type-policy=OVERRIDE, i-signal-type=PRIMITIVE, init-value=0, base-type=BT_MO_Getriebe_Code, compu {0=Cx0_Init (CM_MO_Getriebe_Code_Cx0_Init), 2=Cx2_DL501 (CM_MO_Getriebe_Code_Cx2_DL501), 3=Cx3_DL800 (CM_MO_Getriebe_Code_Cx3_DL800), 4=Cx4_VL381 (CM_MO_Getriebe_Code_Cx4_VL381), 5=Cx5_DL382_Front (CM_MO_Getriebe_Code_Cx5_DL382_Front), 6=Cx6_DL382_Allrad (CM_MO_Getriebe_Code_Cx6_DL382_Allrad), 7=Cx7_DL702 (CM_MO_Getriebe_Code_Cx7_DL702), 8=Cx8_AL552_Allrad (CM_MO_Getriebe_Code_Cx8_AL552_Allrad), 9=Cx9_AL552_Front (CM_MO_Getriebe_Code_Cx9_AL552_Front), 10=Cxa_AL651 (CM_MO_Getriebe_Code_Cxa_AL651), 11=Cxb_AL551_AL951_AL1000_8A (CM_MO_Getriebe_Code_Cxb_AL551_AL951_AL1000_8A) (AL551__AL951__AL1000_8A), 12=Cxc_PDK_PAG (CM_MO_Getriebe_Code_Cxc_PDK_PAG), 13=Cxd_AL551_Hybrid (CM_MO_Getriebe_Code_Cxd_AL551_Hybrid), 15=Cxf_Handschalter_konventionell (CM_MO_Getriebe_Code_Cxf_Handschalter_konventionell), 16=Cx10_AQ250_160 (CM_MO_Getriebe_Code_Cx10_AQ250_160), 17=Cx11_AQ450 (CM_MO_Getriebe_Code_Cx11_AQ450), 18=Cx12_DQ200 (CM_MO_Getriebe_Code_Cx12_DQ200), 19=Cx13_DQ250 (CM_MO_Getriebe_Code_Cx13_DQ250), 20=Cx14_DQ500 (CM_MO_Getriebe_Code_Cx14_DQ500), 21=Cx15_SQ100 (CM_MO_Getriebe_Code_Cx15_SQ100), 22=Cx16_SQ200 (CM_MO_Getriebe_Code_Cx16_SQ200), 23=Cx17_DQ400E (CM_MO_Getriebe_Code_Cx17_DQ400E), 24=Cx18_DQ381 (CM_MO_Getriebe_Code_Cx18_DQ381), 25=Cx19_AL550 (CM_MO_Getriebe_Code_Cx19_AL550), 26=Cx1a_AQ300 (CM_MO_Getriebe_Code_Cx1a_AQ300), 31=Cx1f_DL800E (CM_MO_Getriebe_Code_Cx1f_DL800E), 32=Cx20_Single_Gear_ohne_GSG_WH_am_MSG (CM_MO_Getriebe_Code_Cx20_Single_Gear_ohne_GSG_WH_am_MSG) (Single_Gear__ohne_GSG_WH_am_MSG), 33=Cx21_EQ550_2P (CM_MO_Getriebe_Code_Cx21_EQ550_2P)}, range raw 0..33, transfer-property=PENDING  # Getriebecodierung des Motors
          signal MO_StartStopp_Codiert_XIX_Motor_Code_01_XIX_E3V_EVCANFD: start 30, 1 bit, little-endian, data-type-policy=OVERRIDE, i-signal-type=PRIMITIVE, init-value=0, base-type=BT_MO_StartStopp_Codiert, compu {0=Cx0_Start_Stopp_nicht_verbaut (CM_MO_StartStopp_Codiert_Cx0_Start_Stopp_nicht_verbaut), 1=Cx1_Start_Stopp_verbaut (CM_MO_StartStopp_Codiert_Cx1_Start_Stopp_verbaut)}, range raw 0..1, transfer-property=PENDING  # Funktion StartStopp im aktuellen Klemmenzyklus verbaut
          signal MO_Anzeige_StSt_gueltig_XIX_Motor_Code_01_XIX_E3V_EVCANFD: start 31, 1 bit, little-endian, data-type-policy=OVERRIDE, i-signal-type=PRIMITIVE, init-value=0, base-type=BT_MO_Anzeige_StSt_gueltig, compu {0=Cx0_MO_Text_Motorstart_gueltig (CM_MO_Anzeige_StSt_gueltig_Cx0_MO_Text_Motorstart_gueltig), 1=Cx1_Signale_MO_Anzeige_StSt_gueltig (CM_MO_Anzeige_StSt_gueltig_Cx1_Signale_MO_Anzeige_StSt_gueltig)}, range raw 0..1, transfer-property=PENDING  # Zeigt die Gültigkeit der neuen StSt-Anzeigesignale an, MO_Anzeige_StSt_Text und MO_Anzeige_Symbol. Mo_Text_Motorstart 1..5 sind zu ignorieren.
          signal MO_Anzahl_Zyl_XIX_Motor_Code_01_XIX_E3V_EVCANFD: start 32, 4 bit, little-endian, data-type-policy=OVERRIDE, i-signal-type=PRIMITIVE, init-value=0, base-type=BT_MO_Anzahl_Zyl, compu {0=Cx0_kein_Zylinder (CM_MO_Anzahl_Zyl_Cx0_kein_Zylinder), 1=Cx1_1_Zylinder (CM_MO_Anzahl_Zyl_Cx1_1_Zylinder), 2=Cx2_2_Zylinder (CM_MO_Anzahl_Zyl_Cx2_2_Zylinder), 3=Cx3_3_Zylinder (CM_MO_Anzahl_Zyl_Cx3_3_Zylinder), 4=Cx4_4_Zylinder (CM_MO_Anzahl_Zyl_Cx4_4_Zylinder), 5=Cx5_5_Zylinder (CM_MO_Anzahl_Zyl_Cx5_5_Zylinder), 6=Cx6_6_Zylinder (CM_MO_Anzahl_Zyl_Cx6_6_Zylinder), 7=Cx7_7_Zylinder (CM_MO_Anzahl_Zyl_Cx7_7_Zylinder), 8=Cx8_8_Zylinder (CM_MO_Anzahl_Zyl_Cx8_8_Zylinder), 9=Cx9_9_Zylinder (CM_MO_Anzahl_Zyl_Cx9_9_Zylinder), 10=Cxa_10_Zylinder (CM_MO_Anzahl_Zyl_Cxa_10_Zylinder), 11=Cxb_11_Zylinder (CM_MO_Anzahl_Zyl_Cxb_11_Zylinder), 12=Cxc_12_Zylinder (CM_MO_Anzahl_Zyl_Cxc_12_Zylinder), 13=Cxd_15_Zylinder (CM_MO_Anzahl_Zyl_Cxd_15_Zylinder), 14=Cxe_16_Zylinder (CM_MO_Anzahl_Zyl_Cxe_16_Zylinder), 15=Cxf_18_Zylinder (CM_MO_Anzahl_Zyl_Cxf_18_Zylinder)}, range raw 0..15, transfer-property=PENDING  # Zylinderzahl des Verbrennungsmotors
          signal MO_Kraftstoffart_XIX_Motor_Code_01_XIX_E3V_EVCANFD: start 36, 4 bit, little-endian, data-type-policy=OVERRIDE, i-signal-type=PRIMITIVE, base-type=BT_MO_Kraftstoffart, compu {0=Cx0_Diesel (CM_MO_Kraftstoffart_Cx0_Diesel), 1=Cx1_Benzin_inkl_E25_E85 (CM_MO_Kraftstoffart_Cx1_Benzin_inkl_E25_E85), 2=Cx2_CNG (CM_MO_Kraftstoffart_Cx2_CNG), 3=Cx3_LPG (CM_MO_Kraftstoffart_Cx3_LPG), 4=Cx4_Wasserstoff (CM_MO_Kraftstoffart_Cx4_Wasserstoff), 5=Cx5_E100_Ethanol (CM_MO_Kraftstoffart_Cx5_E100_Ethanol), 15=Cxf_kein_Verbrennungskraftstoff (CM_MO_Kraftstoffart_Cxf_kein_Verbrennungskraftstoff)}, range raw 0..15, transfer-property=PENDING  # Primärkraftstoff zum Antrieb des Fahrzeugs
          signal MO_Hubraum_XIX_Motor_Code_01_XIX_E3V_EVCANFD: start 40, 7 bit, little-endian, data-type-policy=OVERRIDE, i-signal-type=PRIMITIVE, base-type=BT_MO_Hubraum, compu {phys=raw*0.1 for raw 0..127; unit Unit_Liter}, range phys 0..12.7 Unit_Liter, raw 0..127, unit=Unit_Liter, transfer-property=PENDING  # Hubraum des Verbrennungsmotors
          signal MO_Ansaugsystem_XIX_Motor_Code_01_XIX_E3V_EVCANFD: start 47, 1 bit, little-endian, data-type-policy=OVERRIDE, i-signal-type=PRIMITIVE, init-value=0, base-type=BT_MO_Ansaugsystem, compu {0=Cx0_Turbo (CM_MO_Ansaugsystem_Cx0_Turbo), 1=Cx1_Sauger (CM_MO_Ansaugsystem_Cx1_Sauger)}, range raw 0..1, transfer-property=PENDING  # Art des Ansaugsystems des Verbrennungsmotors
          signal MO_Leistung_XIX_Motor_Code_01_XIX_E3V_EVCANFD: start 48, 9 bit, little-endian, data-type-policy=OVERRIDE, i-signal-type=PRIMITIVE, base-type=BT_MO_Leistung, compu {phys=raw for raw 0..511; unit Unit_KiloWatt}, range phys 0..511 Unit_KiloWatt, raw 0..511, unit=Unit_KiloWatt, transfer-property=PENDING  # Nennleistung des Verbrennungsmotors Im reinen E-Fahrzeug (BEV): Ausgabe der elektrischen Systemleistung
          signal MO_OBD_Typ_XIX_Motor_Code_01_XIX_E3V_EVCANFD: start 57, 2 bit, little-endian, data-type-policy=OVERRIDE, i-signal-type=PRIMITIVE, base-type=BT_MO_OBD_Typ, compu {0=Cx0_NoOBD_RdW (CM_MO_OBD_Typ_Cx0_NoOBD_RdW), 1=Cx1_EOBD (CM_MO_OBD_Typ_Cx1_EOBD), 2=Cx2_US_OBD (CM_MO_OBD_Typ_Cx2_US_OBD), 3=Cx3_reserviert (CM_MO_OBD_Typ_Cx3_reserviert)}, range raw 0..3, transfer-property=PENDING, to Klima(timeout 5 s)  # Abgastyp OBD Hinweis: In Fahrzeugen mit dem Zielmarkt China und einer Zertifizierung ab China 6 muss auf dem Signal "MO_OBD_Typ" der Wert "US_OBD" gesendet werden.
          signal MO_DPF_verbaut_XIX_Motor_Code_01_XIX_E3V_EVCANFD: start 59, 1 bit, little-endian, data-type-policy=OVERRIDE, i-signal-type=PRIMITIVE, init-value=0, base-type=BT_MO_DPF_verbaut, compu {0=Cx0_kein_DPF_verbaut (CM_MO_DPF_verbaut_Cx0_kein_DPF_verbaut), 1=Cx1_DPF_verbaut (CM_MO_DPF_verbaut_Cx1_DPF_verbaut)}, range raw 0..1, transfer-property=PENDING  # Verbauinformation Diesel-Partikel-Filter
          signal TSK_Codierung_XIX_Motor_Code_01_XIX_E3V_EVCANFD: start 60, 3 bit, little-endian, data-type-policy=OVERRIDE, i-signal-type=PRIMITIVE, init-value=7, base-type=BT_TSK_Codierung, compu {0=Cx0_kein_Fahrgeschwindigkeitsregler (CM_TSK_Codierung_Cx0_kein_Fahrgeschwindigkeitsregler), 1=Cx1_GRA (CM_TSK_Codierung_Cx1_GRA), 2=Cx2_GRA_Plus (CM_TSK_Codierung_Cx2_GRA_Plus), 3=Cx3_Basis_ACC (CM_TSK_Codierung_Cx3_Basis_ACC), 4=Cx4_ACC_Follow_to_Stop (CM_TSK_Codierung_Cx4_ACC_Follow_to_Stop), 5=Cx5_ACC_Stop_and_Go (CM_TSK_Codierung_Cx5_ACC_Stop_and_Go), 7=Cx7_Codierung_in_Plausibilisierungsphase (CM_TSK_Codierung_Cx7_Codierung_in_Plausibilisierungsphase)}, range raw 0..7, transfer-property=PENDING  # Information über den plausibilisierten Codierungszustand des Triebstrangskoordinators auf ACC oder GRA.
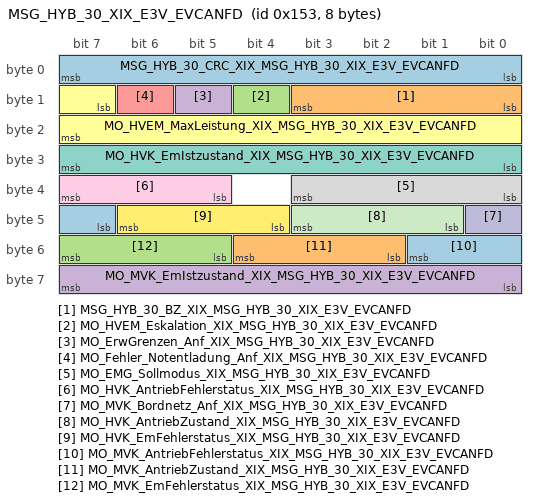
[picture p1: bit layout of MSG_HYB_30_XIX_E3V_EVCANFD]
      frame MSG_HYB_30_XIX_E3V_EVCANFD: id 0x153, to Klima, frame-length=8, can-addressing-mode=STANDARD, can-frame-rx-behavior=CAN-FD, can-frame-tx-behavior=CAN-FD
        pdu MSG_HYB_30_XIX_E3V_EVCANFD: length=8, minimum-delay=0.01, transmission-mode-true-timing={cyclic-timing={time-offset=0.0, time-period=0.2}, event-controlled-timing={number-of-repetitions=0, repetition-period=0.0}}, unused-bit-pattern=0  # CAN-Botschaft
          signal MSG_HYB_30_CRC_XIX_MSG_HYB_30_XIX_E3V_EVCANFD: start 0, 8 bit, little-endian, data-type-policy=OVERRIDE, i-signal-type=PRIMITIVE, init-value=0, base-type=BT_MSG_HYB_30_CRC, compu {phys=raw for raw 0..255}, range phys 0..255, raw 0..255, transfer-property=PENDING  # CRC für die Botschaft MSG_HYB_30
          signal MSG_HYB_30_BZ_XIX_MSG_HYB_30_XIX_E3V_EVCANFD: start 8, 4 bit, little-endian, data-type-policy=OVERRIDE, i-signal-type=PRIMITIVE, init-value=0, base-type=BT_MSG_HYB_30_BZ, compu {phys=raw for raw 0..15}, range phys 0..15, raw 0..15, transfer-property=PENDING  # BZ für die Botschaft MSG_HYB_30
          signal MO_HVEM_Eskalation_XIX_MSG_HYB_30_XIX_E3V_EVCANFD: start 12, 1 bit, little-endian, data-type-policy=OVERRIDE, i-signal-type=PRIMITIVE, init-value=0, base-type=BT_MO_HVEM_Eskalation, compu {0=Cx0_keine_Eskalation_HVEM (CM_MO_HVEM_Eskalation_Cx0_keine_Eskalation_HVEM), 1=Cx1_Eskalation_HVEM (CM_MO_HVEM_Eskalation_Cx1_Eskalation_HVEM)}, range raw 0..1, transfer-property=TRIGGERED-ON-CHANGE-WITHOUT-REPETITION  # Eskalationsbit, mit diesem zusammen darf MO_HVEM_MaxLeistung < der minimal angeforderten Leistung sein und ist durch das HVEM durch Ergreifung aller Eskalationsmaßnahmen umzusetzen (Bei neg. Ladebilanz z.B. im Leerlauf nötig, um die HVBatt vor Entladung etc. zu schützen) VW120/7 und MQB Omega: Anforderung, HV-Verbraucher sofort abzuschalten (minimale Reaktionszeit gefordert).
          signal MO_ErwGrenzen_Anf_XIX_MSG_HYB_30_XIX_E3V_EVCANFD: start 13, 1 bit, little-endian, data-type-policy=OVERRIDE, i-signal-type=PRIMITIVE, init-value=0, base-type=BT_MO_ErwGrenzen_Anf, compu {0=Cx0_normal (CM_MO_ErwGrenzen_Anf_Cx0_normal), 1=Cx1_erweitert (CM_MO_ErwGrenzen_Anf_Cx1_erweitert)}, range raw 0..1, transfer-property=TRIGGERED-ON-CHANGE-WITHOUT-REPETITION  # temporäre Anforderung erweiterter Leistungsgrenzen 0 = normaler Betrieb angefordert 1 = erweiterte Leistungsgrenzen angefordert BMS und EMS liefern ggf. erweiterte Leistungsgrenzen, um VKM-Start auch unter schwierigen Bedingungen gewährleisten zu können
          signal MO_Fehler_Notentladung_Anf_XIX_MSG_HYB_30_XIX_E3V_EVCANFD: start 14, 1 bit, little-endian, data-type-policy=OVERRIDE, i-signal-type=PRIMITIVE, init-value=0, base-type=BT_MO_Fehler_Notentladung_Anf, compu {0=Cx0_Init (CM_MO_Fehler_Notentladung_Anf_Cx0_Init)}, range raw 0, transfer-property=TRIGGERED-ON-CHANGE-WITHOUT-REPETITION  # Aufforderung zur schnellstmöglichen Entladeung des HV-Zwischenkreises aufgrund Crash-Erkennung / Abriss Pilotlinie
          signal MO_HVEM_MaxLeistung_XIX_MSG_HYB_30_XIX_E3V_EVCANFD: start 15, 9 bit, little-endian, data-type-policy=OVERRIDE, i-signal-type=PRIMITIVE, init-value=510, base-type=BT_MO_HVEM_MaxLeistung, compu {phys=raw*50 for raw 0..509, 510=Cx1fe_Init (CM_MO_HVEM_MaxLeistung_Cx1fe_Init); unit Unit_Watt}, range phys 0..25450 Unit_Watt, raw 0..510, unit=Unit_Watt, transfer-property=PENDING, to Klima(timeout 2 s)  # Maximal zulässige Leistung, die das HVEM einzustellen hat. Ohne Eskalationsbit ist diese Anforderung >= der Minimal benötigten Leistung des HVEM Hinweis: Ehemaliger Fehlerwert 0x1FF wird senderseitig nicht unterstützt. Diesen Wert aus Kompatibilitätsgründen nicht neu belegen!
          signal MO_HVK_EmIstzustand_XIX_MSG_HYB_30_XIX_E3V_EVCANFD: start 24, 8 bit, little-endian, data-type-policy=OVERRIDE, i-signal-type=PRIMITIVE, init-value=255, base-type=BT_MO_HVK_EmIstzustand, compu {0=Cx0_HvOff (CM_MO_HVK_EmIstzustand_Cx0_HvOff), 1=Cx1_HvStbyReq (CM_MO_HVK_EmIstzustand_Cx1_HvStbyReq), 2=Cx2_HvStbyOk (CM_MO_HVK_EmIstzustand_Cx2_HvStbyOk), 3=Cx3_HvBattOnReq (CM_MO_HVK_EmIstzustand_Cx3_HvBattOnReq), 4=Cx4_HvBattOnOk (CM_MO_HVK_EmIstzustand_Cx4_HvBattOnOk), 10=Cxa_HvOnIdle (CM_MO_HVK_EmIstzustand_Cxa_HvOnIdle), 18=Cx12_HvOnDrvReq (CM_MO_HVK_EmIstzustand_Cx12_HvOnDrvReq), 19=Cx13_HvOnDrvOk (CM_MO_HVK_EmIstzustand_Cx13_HvOnDrvOk), 20=Cx14_HvOnDrvRdy (CM_MO_HVK_EmIstzustand_Cx14_HvOnDrvRdy), 28=Cx1c_HvStepUpReq (CM_MO_HVK_EmIstzustand_Cx1c_HvStepUpReq), 29=Cx1d_HvStepUpOk (CM_MO_HVK_EmIstzustand_Cx1d_HvStepUpOk), 30=Cx1e_HvStepUp (CM_MO_HVK_EmIstzustand_Cx1e_HvStepUp), 38=Cx26_HvStepDownReq (CM_MO_HVK_EmIstzustand_Cx26_HvStepDownReq), 39=Cx27_HvStepDownOk (CM_MO_HVK_EmIstzustand_Cx27_HvStepDownOk), 40=Cx28_HvStepDown (CM_MO_HVK_EmIstzustand_Cx28_HvStepDown), 46=Cx2e_HvAcChPreReq (CM_MO_HVK_EmIstzustand_Cx2e_HvAcChPreReq), 47=Cx2f_HvAcChPreOk (CM_MO_HVK_EmIstzustand_Cx2f_HvAcChPreOk), 48=Cx30_HvAcChReq (CM_MO_HVK_EmIstzustand_Cx30_HvAcChReq), 49=Cx31_HvAcChOk (CM_MO_HVK_EmIstzustand_Cx31_HvAcChOk), 50=Cx32_HvAcCh (CM_MO_HVK_EmIstzustand_Cx32_HvAcCh), 56=Cx38_HvDcChPreReq (CM_MO_HVK_EmIstzustand_Cx38_HvDcChPreReq), 57=Cx39_HvDcChPreOk (CM_MO_HVK_EmIstzustand_Cx39_HvDcChPreOk), 58=Cx3a_HvDcChReq (CM_MO_HVK_EmIstzustand_Cx3a_HvDcChReq), 59=Cx3b_HvDcChOk (CM_MO_HVK_EmIstzustand_Cx3b_HvDcChOk), 60=Cx3c_HvDcCh (CM_MO_HVK_EmIstzustand_Cx3c_HvDcCh), 67=Cx43_HvChOffReq (CM_MO_HVK_EmIstzustand_Cx43_HvChOffReq), 68=Cx44_HvChOffOk (CM_MO_HVK_EmIstzustand_Cx44_HvChOffOk), 69=Cx45_HvOnIdleReq (CM_MO_HVK_EmIstzustand_Cx45_HvOnIdleReq), 70=Cx46_HvOnIdleOk (CM_MO_HVK_EmIstzustand_Cx46_HvOnIdleOk), 96=Cx60_HvCpntOffReq (CM_MO_HVK_EmIstzustand_Cx60_HvCpntOffReq), 97=Cx61_HvCpntOffOk (CM_MO_HVK_EmIstzustand_Cx61_HvCpntOffOk), 98=Cx62_HvBattOffReq (CM_MO_HVK_EmIstzustand_Cx62_HvBattOffReq), 99=Cx63_HvBattOffOk (CM_MO_HVK_EmIstzustand_Cx63_HvBattOffOk), 109=Cx6d_HvDcDcFailOffReq (CM_MO_HVK_EmIstzustand_Cx6d_HvDcDcFailOffReq), 110=Cx6e_HvDcDcFail (CM_MO_HVK_EmIstzustand_Cx6e_HvDcDcFail), 119=Cx77_HvElmOffReq (CM_MO_HVK_EmIstzustand_Cx77_HvElmOffReq), 120=Cx78_HvElmOff (CM_MO_HVK_EmIstzustand_Cx78_HvElmOff), 126=Cx7e_HvFailCpntOffReq (CM_MO_HVK_EmIstzustand_Cx7e_HvFailCpntOffReq), 127=Cx7f_HvFailCpntOffOk (CM_MO_HVK_EmIstzustand_Cx7f_HvFailCpntOffOk), 128=Cx80_HvFailBattOffReq (CM_MO_HVK_EmIstzustand_Cx80_HvFailBattOffReq), 129=Cx81_HvFailBattOffOk (CM_MO_HVK_EmIstzustand_Cx81_HvFailBattOffOk), 130=Cx82_HvFailBattOff (CM_MO_HVK_EmIstzustand_Cx82_HvFailBattOff), 138=Cx8a_HvFailUCtlReq (CM_MO_HVK_EmIstzustand_Cx8a_HvFailUCtlReq), 139=Cx8b_HvFailUCtlOk (CM_MO_HVK_EmIstzustand_Cx8b_HvFailUCtlOk), 140=Cx8c_HvFailUCtl (CM_MO_HVK_EmIstzustand_Cx8c_HvFailUCtl), 150=Cx96_HvEmgcyOff (CM_MO_HVK_EmIstzustand_Cx96_HvEmgcyOff), 255=Cxff_Init (CM_MO_HVK_EmIstzustand_Cxff_Init)}, range raw 0..255, transfer-property=TRIGGERED-ON-CHANGE-WITHOUT-REPETITION  # Aktueller Istzustand der Elm_State 0 : HvOff 1 : HvStbyReq 2 : HvStbyOk 3 : HvBattOnReq 4 : HvBattOnOk 10 : HvOnIdle 18 : HvOnDrvReq 19 : HvOnDrvOk 20 : HvOnDrvRdy 28 : HvStepUpReq 29 : HvStepUpOk 30 : HvStepUp 38 : HvStepDownReq 39 : HvStepDownOk 40 : HvStepDown 46 : HvAcChPreReq 47 : HvAcChPreOk 48 : HvAcChReq 49 : HvAcChOk 50 : HvAcCh 56 : HvDcChPreReq 57 : HvDcChPreOk 58 : HvDcChReq 59 : HvDcChOk 60 : HvDcCh 67 : HvChOffReq 68 : HvChOffOk 69 : HvOnIdleReq 70 : HvOnIdleOk 96 : HvCpntOffReq 97 : HvCpntOffOk 98 : HvBattOffReq 99 : HvBattOffOk 109 : HvDcDcFailOffReq 110 : HvDcDcFail 119 : HvElmOffReq 120 : HvElmOff 126 : HvFailCpntOffReq 127 : HvFailCpntOffOk 128 : HvBattFailOffReq 129 : HvBattFailOffOk 130 : HvBattFail 138 : HvFailUCtlReq 139 : HvFailUCtlOk 140 : HvFailUCtl 150 : HvEmgcyOff 255 : Init
          signal MO_EMG_Sollmodus_XIX_MSG_HYB_30_XIX_E3V_EVCANFD: start 32, 4 bit, little-endian, data-type-policy=OVERRIDE, i-signal-type=PRIMITIVE, init-value=15, base-type=BT_MO_EMG_Sollmodus, compu {0=Cx0_Standby (CM_MO_EMG_Sollmodus_Cx0_Standby), 1=Cx1_Momentenreg (CM_MO_EMG_Sollmodus_Cx1_Momentenreg), 2=Cx2_Int_Drehzahlreg (CM_MO_EMG_Sollmodus_Cx2_Int_Drehzahlreg), 3=Cx3_Spannungsreg (CM_MO_EMG_Sollmodus_Cx3_Spannungsreg), 4=Cx4_Spannungsreg_Batt_Ab (CM_MO_EMG_Sollmodus_Cx4_Spannungsreg_Batt_Ab), 6=Cx6_Kalibrierung (CM_MO_EMG_Sollmodus_Cx6_Kalibrierung), 8=Cx8_Freilauf (CM_MO_EMG_Sollmodus_Cx8_Freilauf), 9=Cx9_Momentenreg_Komfortfunktionen (CM_MO_EMG_Sollmodus_Cx9_Momentenreg_Komfortfunktionen), 10=Cxa_Asynchrones_Bremsen (CM_MO_EMG_Sollmodus_Cxa_Asynchrones_Bremsen), 11=Cxb_Positionieren (CM_MO_EMG_Sollmodus_Cxb_Positionieren), 12=Cxc_Int_Diagnose (CM_MO_EMG_Sollmodus_Cxc_Int_Diagnose), 15=Cxf_Init (CM_MO_EMG_Sollmodus_Cxf_Init)}, range raw 0..15, transfer-property=TRIGGERED-ON-CHANGE-WITHOUT-REPETITION  # Anforderung der Betriebsart der E-Maschine Werte: 0: Standby; Kommunikation aktiv 1: Momentenregelung 2: Drehzahlregelung (interner Regelkreis) 3: Spannungsregelung 4: Spannungsregelung Batterie Ab 6: Kalibrierung / Anlernen einer neuen EM 8: Freilauf (nur im VW360/7 und VW120/7) 9: Momentenregelung (Komfortfunktionen) 10: Asynchrones Bremsen 11: Positionieren 12: Int_Diagnose 15: MSG befindet sich in der Init-Phase; aktuelle Signalwerte nicht gültig; PWR soll aktuellen Modus beibehalten (Beibehalten des aktuellen Modus ohne gültigen Sollmodus nur für eine maximale Dauer erlaubt)
          signal MO_HVK_AntriebFehlerstatus_XIX_MSG_HYB_30_XIX_E3V_EVCANFD: start 37, 3 bit, little-endian, data-type-policy=OVERRIDE, i-signal-type=PRIMITIVE, init-value=7, base-type=BT_MO_HVK_AntriebFehlerstatus, compu {0=Cx0_Komponente_IO (CM_MO_HVK_AntriebFehlerstatus_Cx0_Komponente_IO), 6=Cx6_Keine_Komponentenfunktion (CM_MO_HVK_AntriebFehlerstatus_Cx6_Keine_Komponentenfunktion), 7=Cx7_Init (CM_MO_HVK_AntriebFehlerstatus_Cx7_Init)}, range raw 0..7, transfer-property=TRIGGERED-ON-CHANGE-WITHOUT-REPETITION  # aktueller Fehlerstatus des Antriebs 0: Komponente IO (keine HVK relevanter Fehler) 1 - 5: reserve 6: Keine Komponentenfunktion (Aus) 7: Init
          signal MO_MVK_Bordnetz_Anf_XIX_MSG_HYB_30_XIX_E3V_EVCANFD: start 40, 1 bit, little-endian, data-type-policy=OVERRIDE, i-signal-type=PRIMITIVE, init-value=0, base-type=BT_MO_MVK_Bordnetz_Anf, compu {0=Cx0_keine_Anforderung (CM_MO_MVK_Bordnetz_Anf_Cx0_keine_Anforderung), 1=Cx1_Bordnetzaktivitaet_gefordert (CM_MO_MVK_Bordnetz_Anf_Cx1_Bordnetzaktivitaet_gefordert)}, range raw 0..1, transfer-property=TRIGGERED-ON-CHANGE-WITHOUT-REPETITION  # Explizite Anforderung des Motors zur Aktivierung bzw. Aufrechterhaltung des Mittelvolt-Bordnetzes für die Ausführung von Motorfunktionen
          signal MO_HVK_AntriebZustand_XIX_MSG_HYB_30_XIX_E3V_EVCANFD: start 41, 3 bit, little-endian, data-type-policy=OVERRIDE, i-signal-type=PRIMITIVE, init-value=7, base-type=BT_MO_HVK_AntriebZustand, compu {0=Cx0_Antrieb_AUS (CM_MO_HVK_AntriebZustand_Cx0_Antrieb_AUS), 1=Cx1_Antrieb_Startphase (CM_MO_HVK_AntriebZustand_Cx1_Antrieb_Startphase), 2=Cx2_E_Fahren (CM_MO_HVK_AntriebZustand_Cx2_E_Fahren), 3=Cx3_Hybrid_Fahren (CM_MO_HVK_AntriebZustand_Cx3_Hybrid_Fahren), 7=Cx7_Init (CM_MO_HVK_AntriebZustand_Cx7_Init)}, range raw 0..7, transfer-property=TRIGGERED-ON-CHANGE-WITHOUT-REPETITION  # Aktueller Zustand des Antriebs: 0 : Antrieb_AUS 1 : Antrieb_Startphase 2 : E-Fahren 3 : Hybrid-Fahren 4 : reserve 5 : reserve 6 : Keine_Komponentenfunktion 7 : Init
          signal MO_HVK_EmFehlerstatus_XIX_MSG_HYB_30_XIX_E3V_EVCANFD: start 44, 3 bit, little-endian, data-type-policy=OVERRIDE, i-signal-type=PRIMITIVE, init-value=7, base-type=BT_MO_HVK_EmFehlerstatus, compu {0=Cx0_Komponente_IO (CM_MO_HVK_EmFehlerstatus_Cx0_Komponente_IO), 1=Cx1_Eingeschr_KompFkt_Teilbetrieb (CM_MO_HVK_EmFehlerstatus_Cx1_Eingeschr_KompFkt_Teilbetrieb), 3=Cx3_Eingeschr_KompFkt_Interlock (CM_MO_HVK_EmFehlerstatus_Cx3_Eingeschr_KompFkt_Interlock), 6=Cx6_Keine_Komponentenfunktion (CM_MO_HVK_EmFehlerstatus_Cx6_Keine_Komponentenfunktion), 7=Cx7_Init (CM_MO_HVK_EmFehlerstatus_Cx7_Init)}, range raw 0..7, transfer-property=TRIGGERED-ON-CHANGE-WITHOUT-REPETITION  # aktueller Fehlerstatus des elektrischen Antriebes (E-Maschine und PWR) 0: Komponente IO (keine HVK relevanter Fehler) 1: Eingeschränkter Betrieb wg. Teilbetrieb 2: reserve 3: Eingeschr_KompFkt_Interlock 4 - 5: reserve 6: Keine Komponentenfunktion (Aus) 7: Init
          signal MO_MVK_AntriebFehlerstatus_XIX_MSG_HYB_30_XIX_E3V_EVCANFD: start 47, 3 bit, little-endian, data-type-policy=OVERRIDE, i-signal-type=PRIMITIVE, init-value=7, base-type=BT_MO_MVK_AntriebFehlerstatus, compu {0=Cx0_Komponente_IO (CM_MO_MVK_AntriebFehlerstatus_Cx0_Komponente_IO), 6=Cx6_Keine_Komponentenfunktion (CM_MO_MVK_AntriebFehlerstatus_Cx6_Keine_Komponentenfunktion), 7=Cx7_Init (CM_MO_MVK_AntriebFehlerstatus_Cx7_Init)}, range raw 0..7, transfer-property=TRIGGERED-ON-CHANGE-WITHOUT-REPETITION  # aktueller Fehlerstatus des Antriebs 0: Komponente IO (keine MVK relevanter Fehler) 1 - 5: reserve 6: Keine Komponentenfunktion (Aus) 7: Init
          signal MO_MVK_AntriebZustand_XIX_MSG_HYB_30_XIX_E3V_EVCANFD: start 50, 3 bit, little-endian, data-type-policy=OVERRIDE, i-signal-type=PRIMITIVE, init-value=7, base-type=BT_MO_MVK_AntriebZustand, compu {0=Cx0_Antrieb_AUS (CM_MO_MVK_AntriebZustand_Cx0_Antrieb_AUS), 1=Cx1_Antrieb_Startphase (CM_MO_MVK_AntriebZustand_Cx1_Antrieb_Startphase), 2=Cx2_FreilaufMotorAus (CM_MO_MVK_AntriebZustand_Cx2_FreilaufMotorAus), 7=Cx7_Init (CM_MO_MVK_AntriebZustand_Cx7_Init)}, range raw 0..7, transfer-property=TRIGGERED-ON-CHANGE-WITHOUT-REPETITION  # Aktueller Zustand des Antriebs: 0 : Antrieb_AUS 1 : Antrieb_Startphase 2 : FreilaufMotorAus 3 : reserve 4 : reserve 5 : reserve 6 : Keine_Komponentenfunktion 7 : Init
          signal MO_MVK_EmFehlerstatus_XIX_MSG_HYB_30_XIX_E3V_EVCANFD: start 53, 3 bit, little-endian, data-type-policy=OVERRIDE, i-signal-type=PRIMITIVE, init-value=7, base-type=BT_MO_MVK_EmFehlerstatus, compu {0=Cx0_Komponente_IO (CM_MO_MVK_EmFehlerstatus_Cx0_Komponente_IO), 1=Cx1_Eingeschr_KompFkt_Teilbetrieb (CM_MO_MVK_EmFehlerstatus_Cx1_Eingeschr_KompFkt_Teilbetrieb), 6=Cx6_Keine_Komponentenfunktion (CM_MO_MVK_EmFehlerstatus_Cx6_Keine_Komponentenfunktion), 7=Cx7_Init (CM_MO_MVK_EmFehlerstatus_Cx7_Init)}, range raw 0..7, transfer-property=TRIGGERED-ON-CHANGE-WITHOUT-REPETITION  # aktueller Fehlerstatus der elektrischen Maschine (RSG) 0: Komponente IO (keine MVK relevanter Fehler) 1: Eingeschränkter Betrieb wg. Teilbetrieb 2: reserve 3 - 5: reserve 6: Keine Komponentenfunktion (Aus) 7: Init
          signal MO_MVK_EmIstzustand_XIX_MSG_HYB_30_XIX_E3V_EVCANFD: start 56, 8 bit, little-endian, data-type-policy=OVERRIDE, i-signal-type=PRIMITIVE, init-value=255, base-type=BT_MO_MVK_EmIstzustand, compu {0=Cx0_MvOff (CM_MO_MVK_EmIstzustand_Cx0_MvOff), 1=Cx1_MvStbyReq (CM_MO_MVK_EmIstzustand_Cx1_MvStbyReq), 2=Cx2_MvStbyOk (CM_MO_MVK_EmIstzustand_Cx2_MvStbyOk), 3=Cx3_MvBattOnReq (CM_MO_MVK_EmIstzustand_Cx3_MvBattOnReq), 4=Cx4_MvBattOnOk (CM_MO_MVK_EmIstzustand_Cx4_MvBattOnOk), 10=Cxa_MvOnIdle (CM_MO_MVK_EmIstzustand_Cxa_MvOnIdle), 18=Cx12_MvOnDrvReq (CM_MO_MVK_EmIstzustand_Cx12_MvOnDrvReq), 19=Cx13_MvOnDrvOk (CM_MO_MVK_EmIstzustand_Cx13_MvOnDrvOk), 20=Cx14_MvOnDrv (CM_MO_MVK_EmIstzustand_Cx14_MvOnDrv), 28=Cx1c_MvStepUpReq (CM_MO_MVK_EmIstzustand_Cx1c_MvStepUpReq), 29=Cx1d_MvStepUpOk (CM_MO_MVK_EmIstzustand_Cx1d_MvStepUpOk), 30=Cx1e_MvStepUp (CM_MO_MVK_EmIstzustand_Cx1e_MvStepUp), 38=Cx26_MvStepDownReq (CM_MO_MVK_EmIstzustand_Cx26_MvStepDownReq), 39=Cx27_MvStepDownOk (CM_MO_MVK_EmIstzustand_Cx27_MvStepDownOk), 40=Cx28_MvStepDown (CM_MO_MVK_EmIstzustand_Cx28_MvStepDown), 96=Cx60_MvCpntOffReq (CM_MO_MVK_EmIstzustand_Cx60_MvCpntOffReq), 97=Cx61_MvCpntOffOk (CM_MO_MVK_EmIstzustand_Cx61_MvCpntOffOk), 98=Cx62_MvBattOffReq (CM_MO_MVK_EmIstzustand_Cx62_MvBattOffReq), 99=Cx63_MvBattOffOk (CM_MO_MVK_EmIstzustand_Cx63_MvBattOffOk), 109=Cx6d_MvDcDcFailOffReq (CM_MO_MVK_EmIstzustand_Cx6d_MvDcDcFailOffReq), 110=Cx6e_MvDcDcFail (CM_MO_MVK_EmIstzustand_Cx6e_MvDcDcFail), 119=Cx77_MvElmFailOffReq (CM_MO_MVK_EmIstzustand_Cx77_MvElmFailOffReq), 120=Cx78_MvElmFail (CM_MO_MVK_EmIstzustand_Cx78_MvElmFail), 126=Cx7e_MvFailCpntOffReq (CM_MO_MVK_EmIstzustand_Cx7e_MvFailCpntOffReq), 127=Cx7f_MvFailCpntOffOk (CM_MO_MVK_EmIstzustand_Cx7f_MvFailCpntOffOk), 128=Cx80_MvFailBattOffReq (CM_MO_MVK_EmIstzustand_Cx80_MvFailBattOffReq), 129=Cx81_MvFailBattOffOk (CM_MO_MVK_EmIstzustand_Cx81_MvFailBattOffOk), 130=Cx82_MvFailBattOff (CM_MO_MVK_EmIstzustand_Cx82_MvFailBattOff), 138=Cx8a_MvFailUCtlReq (CM_MO_MVK_EmIstzustand_Cx8a_MvFailUCtlReq), 139=Cx8b_MvFailUCtlOk (CM_MO_MVK_EmIstzustand_Cx8b_MvFailUCtlOk), 140=Cx8c_MvFailUCtl (CM_MO_MVK_EmIstzustand_Cx8c_MvFailUCtl), 150=Cx96_MvEmgcyOff (CM_MO_MVK_EmIstzustand_Cx96_MvEmgcyOff), 255=Cxff_Init (CM_MO_MVK_EmIstzustand_Cxff_Init)}, range raw 0..255, transfer-property=TRIGGERED-ON-CHANGE-WITHOUT-REPETITION  # Aktueller Istzustand der Elm_State 0 : MvOff 1 : MvStbyReq 2 : MvStbyOk 3 : MvBattOnReq 4 : MvBattOnOk 10 : MvOnIdle 18 : MvOnDrvReq 19 : MvOnDrvOk 20 : MvOnDrv 28 : MvStepUpReq 29 : MvStepUpOk 30 : MvStepUp 38 : MvStepDownReq 39 : MvStepDownOk 40 : MvStepDown 96 : MvCpntOffReq 97 : MvCpntOffOk 98 : MvBattOffReq 99 : MvBattOffOk 109 : MvDcDcFailOffReq 110 : MvDcDcFail 119 : MvElmFailOffReq 120 : MvElmFail 126 : MvFailCpntOffReq 127 : MvFailCpntOffOk 128 : MvBattFailOffReq 129 : MvBattFailOffOk 130 : MvBattFail 138 : MvFailUCtlReq 139 : MvFailUCtlOk 140 : MvFailUCtl 150 : MvEmgcyOff 255 : Init
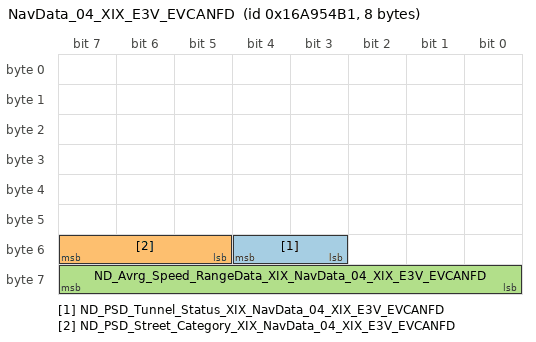
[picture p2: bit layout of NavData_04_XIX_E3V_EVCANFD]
      frame NavData_04_XIX_E3V_EVCANFD: id 0x16A954B1, to Klima, frame-length=8, can-addressing-mode=EXTENDED, can-frame-rx-behavior=CAN-FD, can-frame-tx-behavior=CAN-FD
        pdu NavData_04_XIX_E3V_EVCANFD: length=8, transmission-mode-true-timing=cyclic-timing={time-offset=0, time-period=0.2}, unused-bit-pattern=0
          signal ND_PSD_Tunnel_Status_XIX_NavData_04_XIX_E3V_EVCANFD: start 51, 2 bit, little-endian, data-type-policy=OVERRIDE, i-signal-type=PRIMITIVE, init-value=0, base-type=BT_ND_PSD_Tunnel_Status, compu {0=Cx0_keine_Information_Init (CM_ND_PSD_Tunnel_Status_Cx0_keine_Information_Init), 1=Cx1_freie_Strecke (CM_ND_PSD_Tunnel_Status_Cx1_freie_Strecke), 2=Cx2_Tunnelvorwarnung (CM_ND_PSD_Tunnel_Status_Cx2_Tunnelvorwarnung), 3=Cx3_Tunneldurchfahrt (CM_ND_PSD_Tunnel_Status_Cx3_Tunneldurchfahrt)}, range raw 0..3, transfer-property=PENDING, to Klima(timeout 2 s)  # Information von Navigation/PSD über Tunneldurchfahrt und Tunnelvorwarnung
          signal ND_PSD_Street_Category_XIX_NavData_04_XIX_E3V_EVCANFD: start 53, 3 bit, little-endian, data-type-policy=OVERRIDE, i-signal-type=PRIMITIVE, init-value=7, base-type=BT_ND_PSD_Street_Category, compu {0=Cx0_Rest_Feldweg_Schotterweg_Privatw (CM_ND_PSD_Street_Category_Cx0_Rest_Feldweg_Schotterweg_Privatw), 1=Cx1_Ortsstrasse (CM_ND_PSD_Street_Category_Cx1_Ortsstrasse), 2=Cx2_Kreisstrasse (CM_ND_PSD_Street_Category_Cx2_Kreisstrasse), 3=Cx3_Landstrasse (CM_ND_PSD_Street_Category_Cx3_Landstrasse), 4=Cx4_Bundesstrasse (CM_ND_PSD_Street_Category_Cx4_Bundesstrasse), 5=Cx5_Autobahn (CM_ND_PSD_Street_Category_Cx5_Autobahn), 6=Cx6_nicht_belegt (CM_ND_PSD_Street_Category_Cx6_nicht_belegt), 7=Cx7_Init (CM_ND_PSD_Street_Category_Cx7_Init)}, range raw 0..7, transfer-property=PENDING  # The navigation system shall sent the street category for the current car position within the CAN signal ND_PSD_Street_Category. The street category shall correspond to the category sent in the signal PSD_Strassenkategorie for this position.
          signal ND_Avrg_Speed_RangeData_XIX_NavData_04_XIX_E3V_EVCANFD: start 56, 8 bit, little-endian, data-type-policy=OVERRIDE, i-signal-type=PRIMITIVE, init-value=254, base-type=BT_ND_Avrg_Speed_RangeData, invalid-value=Invalid_ND_Avrg_Speed_RangeData_XIX_NavData_04_XIX_E3V_EVCANFD:255, compu {phys=raw for raw 0..253, 254=Cxfe_Init (CM_ND_Avrg_Speed_RangeData_Cxfe_Init), 255=Cxff_Fehler (CM_ND_Avrg_Speed_RangeData_Cxff_Fehler); unit Unit_KiloMeterPerHour}, range phys 0..253 Unit_KiloMeterPerHour, raw 0..255, unit=Unit_KiloMeterPerHour, transfer-property=PENDING  # Durchschnittsgeschwindigkeit der aktuell befahrenen Strassenkante (Ist-Position Fahrzeug) fuer die Berechnung der routenbasierenden Reichweite.
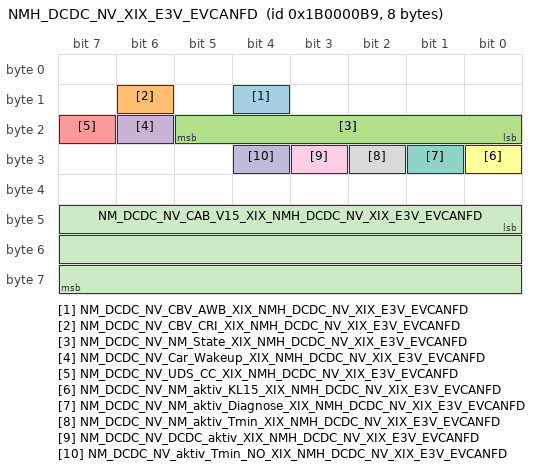
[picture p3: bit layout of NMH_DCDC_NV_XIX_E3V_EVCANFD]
      frame NMH_DCDC_NV_XIX_E3V_EVCANFD: id 0x1B0000B9, to Klima, frame-length=8, can-addressing-mode=EXTENDED, can-frame-rx-behavior=CAN-20, can-frame-tx-behavior=CAN-20, rx-identifier-range={lower-can-id=452984832, upper-can-id=452985855}
        nm pdu NMH_DCDC_NV_XIX_E3V_EVCANFD: length=8, unused-bit-pattern=0
          signal NM_DCDC_NV_CBV_AWB_XIX_NMH_DCDC_NV_XIX_E3V_EVCANFD: start 12, 1 bit, little-endian, data-type-policy=OVERRIDE, i-signal-type=PRIMITIVE, init-value=0, base-type=BT_NM_DCDC_NV_CBV_AWB, compu {0=Cx0_Passiver_WakeUp (CM_NM_DCDC_NV_CBV_AWB_Cx0_Passiver_WakeUp), 1=Cx1_Aktiver_WakeUp (CM_NM_DCDC_NV_CBV_AWB_Cx1_Aktiver_WakeUp)}, range raw 0..1, transfer-property=TRIGGERED  # Das Signal ist zu setzen, wenn das SG aktiv den Bus geweckt hat 0 = Passiver_WakeUp = SG hat das Netzwerk nicht aktiv geweckt 1 = Akitiver_WakeUp = SG hat das Netzwerk aktiv geweckt
          signal NM_DCDC_NV_CBV_CRI_XIX_NMH_DCDC_NV_XIX_E3V_EVCANFD: start 14, 1 bit, little-endian, data-type-policy=OVERRIDE, i-signal-type=PRIMITIVE, init-value=0, base-type=BT_NM_DCDC_NV_CBV_CRI, compu {0=Cx0_NM_ohne_Clusteranforderungen (CM_NM_DCDC_NV_CBV_CRI_Cx0_NM_ohne_Clusteranforderungen), 1=Cx1_NM_mit_Clusteranforderungen (CM_NM_DCDC_NV_CBV_CRI_Cx1_NM_mit_Clusteranforderungen)}, range raw 0..1, transfer-property=TRIGGERED  # Das Signal ist dauerhaft gesetzt, wenn das NM-Layout Cluster- Anforderungen enthält
          signal NM_DCDC_NV_NM_State_XIX_NMH_DCDC_NV_XIX_E3V_EVCANFD: start 16, 6 bit, little-endian, data-type-policy=OVERRIDE, i-signal-type=PRIMITIVE, init-value=0, base-type=BT_NM_DCDC_NV_NM_State, compu {0=Cx0_Init (CM_NM_DCDC_NV_NM_State_Cx0_Init), 1=Cx1_NM_RM_aus_BSM (CM_NM_DCDC_NV_NM_State_Cx1_NM_RM_aus_BSM), 2=Cx2_NM_RM_aus_PBSM (CM_NM_DCDC_NV_NM_State_Cx2_NM_RM_aus_PBSM), 4=Cx4_NM_NO_aus_RM (CM_NM_DCDC_NV_NM_State_Cx4_NM_NO_aus_RM), 8=Cx8_NM_NO_aus_RS (CM_NM_DCDC_NV_NM_State_Cx8_NM_NO_aus_RS), 16=Cx10_reserved (CM_NM_DCDC_NV_NM_State_Cx10_reserved), 32=Cx20_reserved (CM_NM_DCDC_NV_NM_State_Cx20_reserved)}, range raw 0..32, transfer-property=TRIGGERED, to Klima(timeout 2 s)  # 1 = Zustand Repeat Message (<-- Bus-Sleep Mode) 2 = Zustand Repeat Message (<-- Prepare Bus-Sleep Mode) 4 = Zustand Normal Operation (<-- Repeat Message) 8 = Zustand Normal Operation (<-- Ready Sleep)
          signal NM_DCDC_NV_Car_Wakeup_XIX_NMH_DCDC_NV_XIX_E3V_EVCANFD: start 22, 1 bit, little-endian, data-type-policy=OVERRIDE, i-signal-type=PRIMITIVE, init-value=0, base-type=BT_NM_DCDC_NV_Car_Wakeup, compu {0=Cx0_Inaktiv (CM_NM_DCDC_NV_Car_Wakeup_Cx0_Inaktiv), 1=Cx1_Car_Wakeup (CM_NM_DCDC_NV_Car_Wakeup_Cx1_Car_Wakeup)}, range raw 0..1, transfer-property=TRIGGERED  # Car Wakeup (Gateway wertet aus) MQB: aktuell kein Car Wakeup Grund seitens DCDC NV
          signal NM_DCDC_NV_UDS_CC_XIX_NMH_DCDC_NV_XIX_E3V_EVCANFD: start 23, 1 bit, little-endian, data-type-policy=OVERRIDE, i-signal-type=PRIMITIVE, init-value=0, base-type=BT_NM_DCDC_NV_UDS_CC, compu {0=Cx0_Inaktiv (CM_NM_DCDC_NV_UDS_CC_Cx0_Inaktiv), 1=Cx1_CC_aktiv (CM_NM_DCDC_NV_UDS_CC_Cx1_CC_aktiv)}, range raw 0..1, transfer-property=TRIGGERED  # Funktionseinschränkung aufgrund aktivem UDS-Communication Control, siehe VW80124
          signal NM_DCDC_NV_NM_aktiv_KL15_XIX_NMH_DCDC_NV_XIX_E3V_EVCANFD: start 24, 1 bit, little-endian, data-type-policy=OVERRIDE, i-signal-type=PRIMITIVE, init-value=0, base-type=BT_NM_DCDC_NV_NM_aktiv_KL15, compu {0=Cx0_Inaktiv (CM_NM_DCDC_NV_NM_aktiv_KL15_Cx0_Inaktiv), 1=Cx1_KL15_EIN (CM_NM_DCDC_NV_NM_aktiv_KL15_Cx1_KL15_EIN)}, range raw 0..1, transfer-property=TRIGGERED  # Steuergerät hat KL15-EIN erkannt
          signal NM_DCDC_NV_NM_aktiv_Diagnose_XIX_NMH_DCDC_NV_XIX_E3V_EVCANFD: start 25, 1 bit, little-endian, data-type-policy=OVERRIDE, i-signal-type=PRIMITIVE, init-value=0, base-type=BT_NM_DCDC_NV_NM_aktiv_Diagnose, compu {0=Cx0_Inaktiv (CM_NM_DCDC_NV_NM_aktiv_Diagnose_Cx0_Inaktiv), 1=Cx1_Diagnose_aktiv (CM_NM_DCDC_NV_NM_aktiv_Diagnose_Cx1_Diagnose_aktiv)}, range raw 0..1, transfer-property=TRIGGERED  # Diagnose befindet sich nach VW80124 in einer NonDefaultDiagnostic-Session, z.B. ExtendedDiagnostic-Session
          signal NM_DCDC_NV_NM_aktiv_Tmin_XIX_NMH_DCDC_NV_XIX_E3V_EVCANFD: start 26, 1 bit, little-endian, data-type-policy=OVERRIDE, i-signal-type=PRIMITIVE, init-value=0, base-type=BT_NM_DCDC_NV_NM_aktiv_Tmin, compu {0=Cx0_Inaktiv (CM_NM_DCDC_NV_NM_aktiv_Tmin_Cx0_Inaktiv), 1=Cx1_Mindestaktivzeit (CM_NM_DCDC_NV_NM_aktiv_Tmin_Cx1_Mindestaktivzeit)}, range raw 0..1, transfer-property=TRIGGERED  # Mindestaktivzeit ist noch nicht abgelaufen (bei jedem Weckereignis wird die Mindestaktivzeit neu gestartet)
          signal NM_DCDC_NV_DCDC_aktiv_XIX_NMH_DCDC_NV_XIX_E3V_EVCANFD: start 27, 1 bit, little-endian, data-type-policy=OVERRIDE, i-signal-type=PRIMITIVE, init-value=0, base-type=BT_NM_DCDC_NV_DCDC_aktiv, compu {0=Cx0_Inaktiv (CM_NM_DCDC_NV_DCDC_aktiv_Cx0_Inaktiv), 1=Cx1_DCDC_NV_aktiv (CM_NM_DCDC_NV_DCDC_aktiv_Cx1_DCDC_NV_aktiv)}, range raw 0..1, transfer-property=TRIGGERED  # Dieser Bus wird wachgehalten, weil DCDC_NV aktiv
          signal NM_DCDC_NV_aktiv_Tmin_NO_XIX_NMH_DCDC_NV_XIX_E3V_EVCANFD: start 28, 1 bit, little-endian, data-type-policy=OVERRIDE, i-signal-type=PRIMITIVE, init-value=0, base-type=BT_NM_DCDC_NV_aktiv_Tmin_NO, compu {0=Cx0_Inaktiv (CM_NM_DCDC_NV_aktiv_Tmin_NO_Cx0_Inaktiv), 1=Cx1_Mindestaktivzeit_NormalOperation (CM_NM_DCDC_NV_aktiv_Tmin_NO_Cx1_Mindestaktivzeit_NormalOperation)}, range raw 0..1, transfer-property=TRIGGERED  # Mindestaktivzeit in NormalOperation ist noch nicht abgelaufen
          signal NM_DCDC_NV_CAB_V15_XIX_NMH_DCDC_NV_XIX_E3V_EVCANFD: start 40, 24 bit, opaque, data-type-policy=OVERRIDE, i-signal-type=ARRAY, init-value=[0b00000000, 0b00000000, 0b00000000], base-type=BT_NM_DCDC_NV_CAB_V15, compu {0=Cx0_Init (CM_NM_DCDC_NV_CAB_V15_Cx0_Init), 1=Cx1_CAB_01_Antrieb (CM_NM_DCDC_NV_CAB_V15_Cx1_CAB_01_Antrieb), 2=Cx2_CAB_02_Hybrid_Laden (CM_NM_DCDC_NV_CAB_V15_Cx2_CAB_02_Hybrid_Laden), 4=Cx4_CAB_03_Fahrwerk (CM_NM_DCDC_NV_CAB_V15_Cx4_CAB_03_Fahrwerk), 8=Cx8_CAB_04_Fahrerassistenz (CM_NM_DCDC_NV_CAB_V15_Cx8_CAB_04_Fahrerassistenz), 16=Cx10_CAB_05_Komfort (CM_NM_DCDC_NV_CAB_V15_Cx10_CAB_05_Komfort), 32=Cx20_CAB_06_Anzeige (CM_NM_DCDC_NV_CAB_V15_Cx20_CAB_06_Anzeige), 64=Cx40_CAB_07_Connect (CM_NM_DCDC_NV_CAB_V15_Cx40_CAB_07_Connect), 128=Cx80_CAB_08_MIB (CM_NM_DCDC_NV_CAB_V15_Cx80_CAB_08_MIB), 256=Cx100_CAB_09_Standheizung (CM_NM_DCDC_NV_CAB_V15_Cx100_CAB_09_Standheizung), 512=Cx200_CAB_10_MDK (CM_NM_DCDC_NV_CAB_V15_Cx200_CAB_10_MDK), 1024=Cx400_CAB_11_VLAN_Fahrerassistenz (CM_NM_DCDC_NV_CAB_V15_Cx400_CAB_11_VLAN_Fahrerassistenz), 4096=Cx1000_CAB_13_VLAN_Connect (CM_NM_DCDC_NV_CAB_V15_Cx1000_CAB_13_VLAN_Connect), 8192=Cx2000_CAB_14_VLAN_Infotainment (CM_NM_DCDC_NV_CAB_V15_Cx2000_CAB_14_VLAN_Infotainment), 16384=Cx4000_CAB_15_Laden (CM_NM_DCDC_NV_CAB_V15_Cx4000_CAB_15_Laden), 32768=Cx8000_CAB_16_Licht (CM_NM_DCDC_NV_CAB_V15_Cx8000_CAB_16_Licht), 65536=Cx10000_CAB_17_RTM (CM_NM_DCDC_NV_CAB_V15_Cx10000_CAB_17_RTM)}, range raw 0..65536, transfer-property=TRIGGERED  # CAB = Clusteraktivbits (V15)
      frame NMH_Gateway_XIX_E3V_EVCANFD: id 0x1B000010, to Klima, frame-length=8, can-addressing-mode=EXTENDED, can-frame-rx-behavior=CAN-20, can-frame-tx-behavior=CAN-20, rx-identifier-range={lower-can-id=452984832, upper-can-id=452985855}
        nm pdu NMH_Gateway_XIX_E3V_EVCANFD: length=8, unused-bit-pattern=0
          signal NM_Gateway_CBV_AWB_XIX_NMH_Gateway_XIX_E3V_EVCANFD: start 12, 1 bit, little-endian, data-type-policy=OVERRIDE, i-signal-type=PRIMITIVE, init-value=0, base-type=BT_NM_Gateway_CBV_AWB, compu {0=Cx0_Passiver_WakeUp (CM_NM_Gateway_CBV_AWB_Cx0_Passiver_WakeUp), 1=Cx1_Aktiver_WakeUp (CM_NM_Gateway_CBV_AWB_Cx1_Aktiver_WakeUp)}, range raw 0..1, transfer-property=TRIGGERED  # Das Signal ist zu setzen, wenn das SG aktiv den Bus geweckt hat 0 = Passiver_WakeUp = SG hat das Netzwerk nicht aktiv geweckt 1 = Akitiver_WakeUp = SG hat das Netzwerk aktiv geweckt
          signal NM_Gateway_CBV_CRI_XIX_NMH_Gateway_XIX_E3V_EVCANFD: start 14, 1 bit, little-endian, data-type-policy=OVERRIDE, i-signal-type=PRIMITIVE, base-type=BT_NM_Gateway_CBV_CRI, compu {0=Cx0_NM_ohne_Clusteranforderungen (CM_NM_Gateway_CBV_CRI_Cx0_NM_ohne_Clusteranforderungen), 1=Cx1_NM_mit_Clusteranforderungen (CM_NM_Gateway_CBV_CRI_Cx1_NM_mit_Clusteranforderungen)}, range raw 0..1, transfer-property=TRIGGERED  # Das Signal ist dauerhaft gesetzt, wenn das NM-Layout Cluster- Anforderungen enthält
          signal NM_Gateway_NM_State_XIX_NMH_Gateway_XIX_E3V_EVCANFD: start 16, 6 bit, little-endian, data-type-policy=OVERRIDE, i-signal-type=PRIMITIVE, init-value=0, base-type=BT_NM_Gateway_NM_State, compu {0=Cx0_Init (CM_NM_Gateway_NM_State_Cx0_Init), 1=Cx1_NM_RM_aus_BSM (CM_NM_Gateway_NM_State_Cx1_NM_RM_aus_BSM), 2=Cx2_NM_RM_aus_PBSM (CM_NM_Gateway_NM_State_Cx2_NM_RM_aus_PBSM), 4=Cx4_NM_NO_aus_RM (CM_NM_Gateway_NM_State_Cx4_NM_NO_aus_RM), 8=Cx8_NM_NO_aus_RS (CM_NM_Gateway_NM_State_Cx8_NM_NO_aus_RS), 16=Cx10_NM_RM_aus_RS (CM_NM_Gateway_NM_State_Cx10_NM_RM_aus_RS), 32=Cx20_NM_RM_aus_NO (CM_NM_Gateway_NM_State_Cx20_NM_RM_aus_NO)}, range raw 0..32, transfer-property=TRIGGERED, to Klima(timeout 2 s)  # 1 = Zustand Repeat Message (<-- Bus-Sleep Mode) 2 = Zustand Repeat Message (<-- Prepare Bus-Sleep Mode) 4 = Zustand Normal Operation (<-- Repeat Message) 8 = Zustand Normal Operation (<-- Ready Sleep) 16 = Zustand Repeat Message (<-- Ready Sleep) 32 = Zustand Repeat Message (<-- Normal Operation)
          signal NM_Gateway_Car_Wakeup_XIX_NMH_Gateway_XIX_E3V_EVCANFD: start 22, 1 bit, little-endian, data-type-policy=OVERRIDE, i-signal-type=PRIMITIVE, init-value=0, base-type=BT_NM_Gateway_Car_Wakeup, compu {0=Cx0_Inaktiv (CM_NM_Gateway_Car_Wakeup_Cx0_Inaktiv), 1=Cx1_Car_Wakeup (CM_NM_Gateway_Car_Wakeup_Cx1_Car_Wakeup)}, range raw 0..1, transfer-property=TRIGGERED  # Car Wakeup (Subbusmaster wertet aus) MQB: -Diagnose- oder Komponentenschutzmaster-Funktion weckt den schlafenden Subbus (z.B. MOST) E3_Volumen: - Diagnose aktiv -aktive Diagnosekommunikation am OBD-Stecker MQBw_Baseline: - Diagnose aktiv -aktive Diagnosekommunikation am OBD-Stecker
          signal NM_Gateway_UDS_CC_XIX_NMH_Gateway_XIX_E3V_EVCANFD: start 23, 1 bit, little-endian, data-type-policy=OVERRIDE, i-signal-type=PRIMITIVE, init-value=0, base-type=BT_NM_Gateway_UDS_CC, compu {0=Cx0_Inaktiv (CM_NM_Gateway_UDS_CC_Cx0_Inaktiv), 1=Cx1_CC_aktiv (CM_NM_Gateway_UDS_CC_Cx1_CC_aktiv)}, range raw 0..1, transfer-property=TRIGGERED  # Funktionseinschränkung aufgrund aktivem UDS-Communication Control, siehe VW80124
          signal NM_Gateway_NM_aktiv_KL15_XIX_NMH_Gateway_XIX_E3V_EVCANFD: start 24, 1 bit, little-endian, data-type-policy=OVERRIDE, i-signal-type=PRIMITIVE, init-value=0, base-type=BT_NM_Gateway_NM_aktiv_KL15, compu {0=Cx0_Inaktiv (CM_NM_Gateway_NM_aktiv_KL15_Cx0_Inaktiv), 1=Cx1_KL15_EIN (CM_NM_Gateway_NM_aktiv_KL15_Cx1_KL15_EIN)}, range raw 0..1, transfer-property=TRIGGERED  # Steuergerät hat KL15-EIN erkannt
          signal NM_Gateway_NM_aktiv_Diagnose_XIX_NMH_Gateway_XIX_E3V_EVCANFD: start 25, 1 bit, little-endian, data-type-policy=OVERRIDE, i-signal-type=PRIMITIVE, init-value=0, base-type=BT_NM_Gateway_NM_aktiv_Diagnose, compu {0=Cx0_Init (CM_NM_Gateway_NM_aktiv_Diagnose_Cx0_Init), 1=Cx1_Diagnose_aktiv (CM_NM_Gateway_NM_aktiv_Diagnose_Cx1_Diagnose_aktiv)}, range raw 0..1, transfer-property=TRIGGERED  # Diagnose befindet sich nach VW80124 in einer NonDefaultDiagnostic-Session, z.B. ExtendedDiagnostic-Session
          signal NM_Gateway_NM_aktiv_Tmin_XIX_NMH_Gateway_XIX_E3V_EVCANFD: start 26, 1 bit, little-endian, data-type-policy=OVERRIDE, i-signal-type=PRIMITIVE, init-value=0, base-type=BT_NM_Gateway_NM_aktiv_Tmin, compu {0=Cx0_Inaktiv (CM_NM_Gateway_NM_aktiv_Tmin_Cx0_Inaktiv), 1=Cx1_Mindestaktivzeit (CM_NM_Gateway_NM_aktiv_Tmin_Cx1_Mindestaktivzeit)}, range raw 0..1, transfer-property=TRIGGERED  # Mindestaktivzeit ist noch nicht abgelaufen (bei jedem Weckereignis wird die Mindestaktivzeit neu gestartet)
          signal NM_Gateway_NM_aktiv_Kessy_XIX_NMH_Gateway_XIX_E3V_EVCANFD: start 27, 1 bit, little-endian, data-type-policy=OVERRIDE, i-signal-type=PRIMITIVE, init-value=0, base-type=BT_NM_Gateway_NM_aktiv_Kessy, compu {0=Cx0_Inaktiv (CM_NM_Gateway_NM_aktiv_Kessy_Cx0_Inaktiv), 1=Cx1_Kessy_aktiv (CM_NM_Gateway_NM_aktiv_Kessy_Cx1_Kessy_aktiv)}, range raw 0..1, transfer-property=TRIGGERED  # Dieser Bus wird auf Grund einer Aktivität der Funktion Kessy wachgehalten
          signal NM_Gateway_NM_aktiv_Energie_XIX_NMH_Gateway_XIX_E3V_EVCANFD: start 28, 1 bit, little-endian, data-type-policy=OVERRIDE, i-signal-type=PRIMITIVE, init-value=0, base-type=BT_NM_Gateway_NM_aktiv_Energie, compu {0=Cx0_Inaktiv (CM_NM_Gateway_NM_aktiv_Energie_Cx0_Inaktiv), 1=Cx1_Energie_aktiv (CM_NM_Gateway_NM_aktiv_Energie_Cx1_Energie_aktiv)}, range raw 0..1, transfer-property=TRIGGERED  # Dieser Bus wird auf Grund einer Aktivität der Funktion EMHLR, HVEM, Dynamic Charging POI, Charging-Management-Server oder Extended Charging Monitoring wachgehalten
          signal NM_Gateway_NM_aktiv_Licht_XIX_NMH_Gateway_XIX_E3V_EVCANFD: start 29, 1 bit, little-endian, data-type-policy=OVERRIDE, i-signal-type=PRIMITIVE, init-value=0, base-type=BT_NM_Gateway_NM_aktiv_Licht, compu {0=Cx0_Inaktiv (CM_NM_Gateway_NM_aktiv_Licht_Cx0_Inaktiv), 1=Cx1_Licht_aktiv (CM_NM_Gateway_NM_aktiv_Licht_Cx1_Licht_aktiv)}, range raw 0..1, transfer-property=TRIGGERED  # Dieser Bus wird auf Grund einer Aktivität der Funktion Dimmung oder Standard Außenlicht wachgehalten
          signal NM_Gateway_NM_aktiv_USS_XIX_NMH_Gateway_XIX_E3V_EVCANFD: start 30, 1 bit, little-endian, data-type-policy=OVERRIDE, i-signal-type=PRIMITIVE, init-value=0, base-type=BT_NM_Gateway_NM_aktiv_USS, compu {0=Cx0_Inaktiv (CM_NM_Gateway_NM_aktiv_USS_Cx0_Inaktiv), 1=Cx1_USS_aktiv (CM_NM_Gateway_NM_aktiv_USS_Cx1_USS_aktiv)}, range raw 0..1, transfer-property=TRIGGERED  # Dieser Bus wird auf Grund einer Aktivität des User State Servers wachgehalten
          signal NM_Gateway_NM_aktiv_IAA_PSO_XIX_NMH_Gateway_XIX_E3V_EVCANFD: start 31, 1 bit, little-endian, data-type-policy=OVERRIDE, i-signal-type=PRIMITIVE, init-value=0, base-type=BT_NM_Gateway_NM_aktiv_IAA_PSO, compu {0=Cx0_Inaktiv (CM_NM_Gateway_NM_aktiv_IAA_PSO_Cx0_Inaktiv), 1=Cx1_Personalisierung_aktiv (CM_NM_Gateway_NM_aktiv_IAA_PSO_Cx1_Personalisierung_aktiv)}, range raw 0..1, transfer-property=TRIGGERED  # Dieser Bus wird auf Grund einer Aktivität der Personalisierung wachgehalten
          signal NM_Gateway_NM_aktiv_CAB_XIX_NMH_Gateway_XIX_E3V_EVCANFD: start 32, 1 bit, little-endian, data-type-policy=OVERRIDE, i-signal-type=PRIMITIVE, init-value=0, base-type=BT_NM_Gateway_NM_aktiv_CAB, compu {0=Cx0_Inaktiv (CM_NM_Gateway_NM_aktiv_CAB_Cx0_Inaktiv), 1=Cx1_CAB_aktiv (CM_NM_Gateway_NM_aktiv_CAB_Cx1_CAB_aktiv)}, range raw 0..1, transfer-property=TRIGGERED  # Nachlauf aufgrund Kopplung mehrerer Busse. z.B. K-CAN und K2-CAN, Clusteranforderung über CAB und Car Wakeup Anforderung.
          signal NM_Gateway_NM_aktiv_KS_XIX_NMH_Gateway_XIX_E3V_EVCANFD: start 33, 1 bit, little-endian, data-type-policy=OVERRIDE, i-signal-type=PRIMITIVE, init-value=0, base-type=BT_NM_Gateway_NM_aktiv_KS, compu {0=Cx0_Inaktiv (CM_NM_Gateway_NM_aktiv_KS_Cx0_Inaktiv), 1=Cx1_KS_aktiv (CM_NM_Gateway_NM_aktiv_KS_Cx1_KS_aktiv)}, range raw 0..1, transfer-property=TRIGGERED  # Dieser Bus wird auf Grund einer Aktivität des Komponentenschutzes wachgehalten
          signal NM_Gateway_NM_aktiv_PaCo_XIX_NMH_Gateway_XIX_E3V_EVCANFD: start 34, 1 bit, little-endian, data-type-policy=OVERRIDE, i-signal-type=PRIMITIVE, init-value=0, base-type=BT_NM_Gateway_NM_aktiv_PaCo, compu {0=Cx0_Inaktiv (CM_NM_Gateway_NM_aktiv_PaCo_Cx0_Inaktiv), 1=Cx1_PaCo_aktiv (CM_NM_Gateway_NM_aktiv_PaCo_Cx1_PaCo_aktiv)}, range raw 0..1, transfer-property=TRIGGERED  # Dieser Bus wird auf Grund einer Aktivität des Park Koordinators wachgehalten
          signal NM_Gateway_NM_aktiv_Standklima_XIX_NMH_Gateway_XIX_E3V_EVCANFD: start 35, 1 bit, little-endian, data-type-policy=OVERRIDE, i-signal-type=PRIMITIVE, init-value=0, base-type=BT_NM_Gateway_NM_aktiv_Standklima, compu {0=Cx0_Inaktiv (CM_NM_Gateway_NM_aktiv_Standklima_Cx0_Inaktiv), 1=Cx1_STK_aktiv (CM_NM_Gateway_NM_aktiv_Standklima_Cx1_STK_aktiv)}, range raw 0..1, transfer-property=TRIGGERED  # Dieser Bus wird auf Grund einer Aktivität der Standklimatisierung wachgehalten
          signal NM_Gateway_NM_aktiv_ZV_XIX_NMH_Gateway_XIX_E3V_EVCANFD: start 36, 1 bit, little-endian, data-type-policy=OVERRIDE, i-signal-type=PRIMITIVE, init-value=0, base-type=BT_NM_Gateway_NM_aktiv_ZV, compu {0=Cx0_Inaktiv (CM_NM_Gateway_NM_aktiv_ZV_Cx0_Inaktiv), 1=Cx1_ZV_aktiv (CM_NM_Gateway_NM_aktiv_ZV_Cx1_ZV_aktiv)}, range raw 0..1, transfer-property=TRIGGERED  # Dieser Bus wird auf Grund einer Aktivität der Zentralverriegelung wachgehalten
          signal NM_Gateway_NM_aktiv_RTM_XIX_NMH_Gateway_XIX_E3V_EVCANFD: start 37, 1 bit, little-endian, data-type-policy=OVERRIDE, i-signal-type=PRIMITIVE, init-value=0, base-type=BT_NM_Gateway_NM_aktiv_RTM, compu {0=Cx0_Inaktiv (CM_NM_Gateway_NM_aktiv_RTM_Cx0_Inaktiv), 1=Cx1_RTM_aktiv (CM_NM_Gateway_NM_aktiv_RTM_Cx1_RTM_aktiv)}, range raw 0..1, transfer-property=TRIGGERED  # Dieser Bus wird auf Grund einer Aktivität des Real Time Monitors wachgehalten
          signal NM_Gateway_NM_aktiv_ZM_XIX_NMH_Gateway_XIX_E3V_EVCANFD: start 38, 1 bit, little-endian, data-type-policy=OVERRIDE, i-signal-type=PRIMITIVE, init-value=0, base-type=BT_NM_Gateway_NM_aktiv_ZM, compu {0=Cx0_Inaktiv (CM_NM_Gateway_NM_aktiv_ZM_Cx0_Inaktiv), 1=Cx1_ZM_aktiv (CM_NM_Gateway_NM_aktiv_ZM_Cx1_ZM_aktiv)}, range raw 0..1, transfer-property=TRIGGERED  # Dieser Bus wird auf Grund einer Aktivität des Zeitmasters wachgehalten
          signal NM_Gateway_NM_aktiv_FoD_XIX_NMH_Gateway_XIX_E3V_EVCANFD: start 39, 1 bit, little-endian, data-type-policy=OVERRIDE, i-signal-type=PRIMITIVE, init-value=0, base-type=BT_NM_Gateway_NM_aktiv_FoD, compu {0=Cx0_Inaktiv (CM_NM_Gateway_NM_aktiv_FoD_Cx0_Inaktiv), 1=Cx1_FoD_aktiv (CM_NM_Gateway_NM_aktiv_FoD_Cx1_FoD_aktiv)}, range raw 0..1, transfer-property=TRIGGERED  # Dieser Bus wird auf Grund einer Aktivität der Function on Demand wachgehalten
          signal NM_Gateway_CAB_V15_XIX_NMH_Gateway_XIX_E3V_EVCANFD: start 40, 24 bit, opaque, data-type-policy=OVERRIDE, i-signal-type=ARRAY, init-value=[0b00000000, 0b00000000, 0b00000000], base-type=BT_NM_Gateway_CAB_V15, compu {0=Cx0_Init (CM_NM_Gateway_CAB_V15_Cx0_Init), 1=Cx1_CAB_01_Antrieb (CM_NM_Gateway_CAB_V15_Cx1_CAB_01_Antrieb), 2=Cx2_CAB_02_Hybrid_Laden (CM_NM_Gateway_CAB_V15_Cx2_CAB_02_Hybrid_Laden), 4=Cx4_CAB_03_Fahrwerk (CM_NM_Gateway_CAB_V15_Cx4_CAB_03_Fahrwerk), 8=Cx8_CAB_04_Fahrerassistenz (CM_NM_Gateway_CAB_V15_Cx8_CAB_04_Fahrerassistenz), 16=Cx10_CAB_05_Komfort (CM_NM_Gateway_CAB_V15_Cx10_CAB_05_Komfort), 32=Cx20_CAB_06_Anzeige (CM_NM_Gateway_CAB_V15_Cx20_CAB_06_Anzeige), 64=Cx40_CAB_07_Connect (CM_NM_Gateway_CAB_V15_Cx40_CAB_07_Connect), 128=Cx80_CAB_08_MIB (CM_NM_Gateway_CAB_V15_Cx80_CAB_08_MIB), 256=Cx100_CAB_09_Standheizung (CM_NM_Gateway_CAB_V15_Cx100_CAB_09_Standheizung), 512=Cx200_CAB_10_MDK (CM_NM_Gateway_CAB_V15_Cx200_CAB_10_MDK), 1024=Cx400_CAB_11_VLAN_Fahrerassistenz (CM_NM_Gateway_CAB_V15_Cx400_CAB_11_VLAN_Fahrerassistenz), 4096=Cx1000_CAB_13_VLAN_Connect (CM_NM_Gateway_CAB_V15_Cx1000_CAB_13_VLAN_Connect), 8192=Cx2000_CAB_14_VLAN_Infotainment (CM_NM_Gateway_CAB_V15_Cx2000_CAB_14_VLAN_Infotainment), 16384=Cx4000_CAB_15_Laden (CM_NM_Gateway_CAB_V15_Cx4000_CAB_15_Laden), 32768=Cx8000_CAB_16_Licht (CM_NM_Gateway_CAB_V15_Cx8000_CAB_16_Licht), 65536=Cx10000_CAB_17_RTM (CM_NM_Gateway_CAB_V15_Cx10000_CAB_17_RTM)}, range raw 0..65536, transfer-property=TRIGGERED  # CAB = Clusteraktivbits (V15)
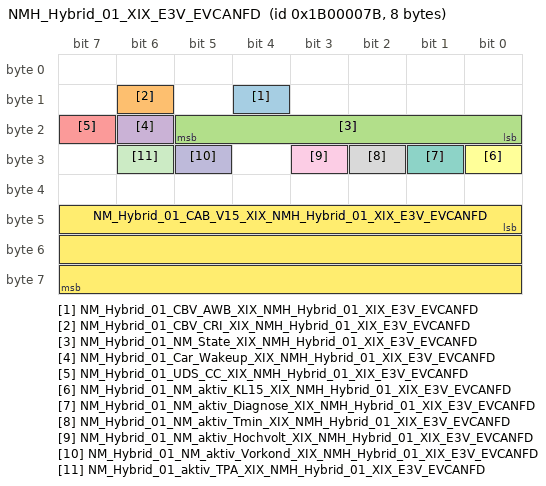
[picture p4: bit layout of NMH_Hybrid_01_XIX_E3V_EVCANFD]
      frame NMH_Hybrid_01_XIX_E3V_EVCANFD: id 0x1B00007B, to Klima, frame-length=8, can-addressing-mode=EXTENDED, can-frame-rx-behavior=CAN-20, can-frame-tx-behavior=CAN-20, rx-identifier-range={lower-can-id=452984832, upper-can-id=452985855}
        nm pdu NMH_Hybrid_01_XIX_E3V_EVCANFD: length=8, unused-bit-pattern=0
          signal NM_Hybrid_01_CBV_AWB_XIX_NMH_Hybrid_01_XIX_E3V_EVCANFD: start 12, 1 bit, little-endian, data-type-policy=OVERRIDE, i-signal-type=PRIMITIVE, init-value=0, base-type=BT_NM_Hybrid_01_CBV_AWB, compu {0=Cx0_Passiver_WakeUp (CM_NM_Hybrid_01_CBV_AWB_Cx0_Passiver_WakeUp), 1=Cx1_Aktiver_WakeUp (CM_NM_Hybrid_01_CBV_AWB_Cx1_Aktiver_WakeUp)}, range raw 0..1, transfer-property=TRIGGERED  # Das Signal ist zu setzen, wenn das SG aktiv den Bus geweckt hat 0 = Passiver_WakeUp = SG hat das Netzwerk nicht aktiv geweckt 1 = Akitiver_WakeUp = SG hat das Netzwerk aktiv geweckt
          signal NM_Hybrid_01_CBV_CRI_XIX_NMH_Hybrid_01_XIX_E3V_EVCANFD: start 14, 1 bit, little-endian, data-type-policy=OVERRIDE, i-signal-type=PRIMITIVE, base-type=BT_NM_Hybrid_01_CBV_CRI, compu {0=Cx0_NM_ohne_Clusteranforderungen (CM_NM_Hybrid_01_CBV_CRI_Cx0_NM_ohne_Clusteranforderungen), 1=Cx1_NM_mit_Clusteranforderungen (CM_NM_Hybrid_01_CBV_CRI_Cx1_NM_mit_Clusteranforderungen)}, range raw 0..1, transfer-property=TRIGGERED  # Das Signal ist dauerhaft gesetzt, wenn das NM-Layout Cluster- Anforderungen enthält
          signal NM_Hybrid_01_NM_State_XIX_NMH_Hybrid_01_XIX_E3V_EVCANFD: start 16, 6 bit, little-endian, data-type-policy=OVERRIDE, i-signal-type=PRIMITIVE, init-value=0, base-type=BT_NM_Hybrid_01_NM_State, compu {0=Cx0_Init (CM_NM_Hybrid_01_NM_State_Cx0_Init), 1=Cx1_NM_RM_aus_BSM (CM_NM_Hybrid_01_NM_State_Cx1_NM_RM_aus_BSM), 2=Cx2_NM_RM_aus_PBSM (CM_NM_Hybrid_01_NM_State_Cx2_NM_RM_aus_PBSM), 4=Cx4_NM_NO_aus_RM (CM_NM_Hybrid_01_NM_State_Cx4_NM_NO_aus_RM), 8=Cx8_NM_NO_aus_RS (CM_NM_Hybrid_01_NM_State_Cx8_NM_NO_aus_RS), 16=Cx10_reserved (CM_NM_Hybrid_01_NM_State_Cx10_reserved), 32=Cx20_reserved (CM_NM_Hybrid_01_NM_State_Cx20_reserved)}, range raw 0..32, transfer-property=TRIGGERED, to Klima(timeout 2 s)  # 1 = Zustand Repeat Message (<-- Bus-Sleep Mode) 2 = Zustand Repeat Message (<-- Prepare Bus-Sleep Mode) 4 = Zustand Normal Operation (<-- Repeat Message) 8 = Zustand Normal Operation (<-- Ready Sleep)
          signal NM_Hybrid_01_Car_Wakeup_XIX_NMH_Hybrid_01_XIX_E3V_EVCANFD: start 22, 1 bit, little-endian, data-type-policy=OVERRIDE, i-signal-type=PRIMITIVE, init-value=0, base-type=BT_NM_Hybrid_01_Car_Wakeup, compu {0=Cx0_Inaktiv (CM_NM_Hybrid_01_Car_Wakeup_Cx0_Inaktiv), 1=Cx1_Car_Wakeup (CM_NM_Hybrid_01_Car_Wakeup_Cx1_Car_Wakeup)}, range raw 0..1, transfer-property=TRIGGERED  # Car Wakeup (Gateway wertet aus)
          signal NM_Hybrid_01_UDS_CC_XIX_NMH_Hybrid_01_XIX_E3V_EVCANFD: start 23, 1 bit, little-endian, data-type-policy=OVERRIDE, i-signal-type=PRIMITIVE, init-value=0, base-type=BT_NM_Hybrid_01_UDS_CC, compu {0=Cx0_Inaktiv (CM_NM_Hybrid_01_UDS_CC_Cx0_Inaktiv), 1=Cx1_CC_aktiv (CM_NM_Hybrid_01_UDS_CC_Cx1_CC_aktiv)}, range raw 0..1, transfer-property=TRIGGERED  # Funktionseinschränkung aufgrund aktivem UDS-Communication Control, siehe VW80124
          signal NM_Hybrid_01_NM_aktiv_KL15_XIX_NMH_Hybrid_01_XIX_E3V_EVCANFD: start 24, 1 bit, little-endian, data-type-policy=OVERRIDE, i-signal-type=PRIMITIVE, init-value=0, base-type=BT_NM_Hybrid_01_NM_aktiv_KL15, compu {0=Cx0_Inaktiv (CM_NM_Hybrid_01_NM_aktiv_KL15_Cx0_Inaktiv), 1=Cx1_KL15_EIN (CM_NM_Hybrid_01_NM_aktiv_KL15_Cx1_KL15_EIN)}, range raw 0..1, transfer-property=TRIGGERED  # Steuergerät hat KL15-EIN erkannt
          signal NM_Hybrid_01_NM_aktiv_Diagnose_XIX_NMH_Hybrid_01_XIX_E3V_EVCANFD: start 25, 1 bit, little-endian, data-type-policy=OVERRIDE, i-signal-type=PRIMITIVE, init-value=0, base-type=BT_NM_Hybrid_01_NM_aktiv_Diagnose, compu {0=Cx0_Init (CM_NM_Hybrid_01_NM_aktiv_Diagnose_Cx0_Init), 1=Cx1_Diagnose_aktiv (CM_NM_Hybrid_01_NM_aktiv_Diagnose_Cx1_Diagnose_aktiv)}, range raw 0..1, transfer-property=TRIGGERED  # Diagnose befindet sich nach VW80124 in einer NonDefaultDiagnostic-Session, z.B. ExtendedDiagnostic-Session
          signal NM_Hybrid_01_NM_aktiv_Tmin_XIX_NMH_Hybrid_01_XIX_E3V_EVCANFD: start 26, 1 bit, little-endian, data-type-policy=OVERRIDE, i-signal-type=PRIMITIVE, init-value=0, base-type=BT_NM_Hybrid_01_NM_aktiv_Tmin, compu {0=Cx0_Inaktiv (CM_NM_Hybrid_01_NM_aktiv_Tmin_Cx0_Inaktiv), 1=Cx1_Mindestaktivzeit (CM_NM_Hybrid_01_NM_aktiv_Tmin_Cx1_Mindestaktivzeit)}, range raw 0..1, transfer-property=TRIGGERED  # Mindestaktivzeit ist noch nicht abgelaufen (bei jedem Weckereignis wird die Mindestaktivzeit neu gestartet)
          signal NM_Hybrid_01_NM_aktiv_Hochvolt_XIX_NMH_Hybrid_01_XIX_E3V_EVCANFD: start 27, 1 bit, little-endian, data-type-policy=OVERRIDE, i-signal-type=PRIMITIVE, init-value=0, base-type=BT_NM_Hybrid_01_NM_aktiv_Hochvolt, compu {0=Cx0_kein_Nachlauf (CM_NM_Hybrid_01_NM_aktiv_Hochvolt_Cx0_kein_Nachlauf), 1=Cx1_Hochvolt_aktiv (CM_NM_Hybrid_01_NM_aktiv_Hochvolt_Cx1_Hochvolt_aktiv)}, range raw 0..1, transfer-property=TRIGGERED  # Hochvolt aktiv
          signal NM_Hybrid_01_NM_aktiv_Vorkond_XIX_NMH_Hybrid_01_XIX_E3V_EVCANFD: start 29, 1 bit, little-endian, data-type-policy=OVERRIDE, i-signal-type=PRIMITIVE, init-value=0, base-type=BT_NM_Hybrid_01_NM_aktiv_Vorkond, compu {0=Cx0_kein_Nachlauf (CM_NM_Hybrid_01_NM_aktiv_Vorkond_Cx0_kein_Nachlauf), 1=Cx1_Vorkonditionierung_aktiv (CM_NM_Hybrid_01_NM_aktiv_Vorkond_Cx1_Vorkonditionierung_aktiv)}, range raw 0..1, transfer-property=TRIGGERED  # Vorkonditionierung aktiv
          signal NM_Hybrid_01_aktiv_TPA_XIX_NMH_Hybrid_01_XIX_E3V_EVCANFD: start 30, 1 bit, little-endian, data-type-policy=OVERRIDE, i-signal-type=PRIMITIVE, init-value=0, base-type=BT_NM_Hybrid_01_aktiv_TPA, compu {0=Cx0_kein_Nachlauf (CM_NM_Hybrid_01_aktiv_TPA_Cx0_kein_Nachlauf), 1=Cx1_TPA_aktiv (CM_NM_Hybrid_01_aktiv_TPA_Cx1_TPA_aktiv)}, range raw 0..1, transfer-property=TRIGGERED  # TPA aktiv (Thermische Propagation)
          signal NM_Hybrid_01_CAB_V15_XIX_NMH_Hybrid_01_XIX_E3V_EVCANFD: start 40, 24 bit, opaque, data-type-policy=OVERRIDE, i-signal-type=ARRAY, init-value=[0b00000000, 0b00000000, 0b00000000], base-type=BT_NM_Hybrid_01_CAB_V15, compu {0=Cx0_Init (CM_NM_Hybrid_01_CAB_V15_Cx0_Init), 1=Cx1_CAB_01_Antrieb (CM_NM_Hybrid_01_CAB_V15_Cx1_CAB_01_Antrieb), 2=Cx2_CAB_02_Hybrid_Laden (CM_NM_Hybrid_01_CAB_V15_Cx2_CAB_02_Hybrid_Laden), 4=Cx4_CAB_03_Fahrwerk (CM_NM_Hybrid_01_CAB_V15_Cx4_CAB_03_Fahrwerk), 8=Cx8_CAB_04_Fahrerassistenz (CM_NM_Hybrid_01_CAB_V15_Cx8_CAB_04_Fahrerassistenz), 16=Cx10_CAB_05_Komfort (CM_NM_Hybrid_01_CAB_V15_Cx10_CAB_05_Komfort), 32=Cx20_CAB_06_Anzeige (CM_NM_Hybrid_01_CAB_V15_Cx20_CAB_06_Anzeige), 64=Cx40_CAB_07_Connect (CM_NM_Hybrid_01_CAB_V15_Cx40_CAB_07_Connect), 128=Cx80_CAB_08_MIB (CM_NM_Hybrid_01_CAB_V15_Cx80_CAB_08_MIB), 256=Cx100_CAB_09_Standheizung (CM_NM_Hybrid_01_CAB_V15_Cx100_CAB_09_Standheizung), 512=Cx200_CAB_10_MDK (CM_NM_Hybrid_01_CAB_V15_Cx200_CAB_10_MDK), 1024=Cx400_CAB_11_VLAN_Fahrerassistenz (CM_NM_Hybrid_01_CAB_V15_Cx400_CAB_11_VLAN_Fahrerassistenz), 4096=Cx1000_CAB_13_VLAN_Connect (CM_NM_Hybrid_01_CAB_V15_Cx1000_CAB_13_VLAN_Connect), 8192=Cx2000_CAB_14_VLAN_Infotainment (CM_NM_Hybrid_01_CAB_V15_Cx2000_CAB_14_VLAN_Infotainment), 16384=Cx4000_CAB_15_Laden (CM_NM_Hybrid_01_CAB_V15_Cx4000_CAB_15_Laden), 32768=Cx8000_CAB_16_Licht (CM_NM_Hybrid_01_CAB_V15_Cx8000_CAB_16_Licht), 65536=Cx10000_CAB_17_RTM (CM_NM_Hybrid_01_CAB_V15_Cx10000_CAB_17_RTM)}, range raw 0..65536, transfer-property=TRIGGERED  # CAB = Clusteraktivbits (V15)
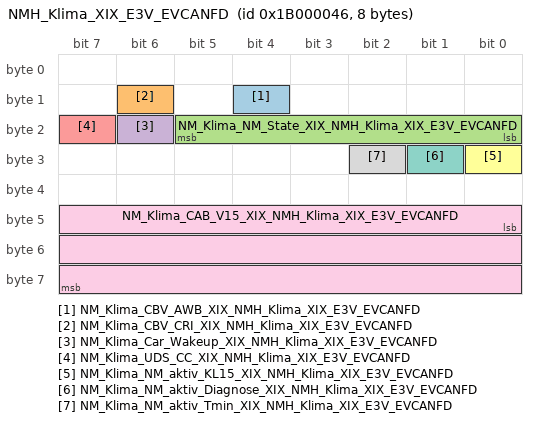
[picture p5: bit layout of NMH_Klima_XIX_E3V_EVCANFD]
      frame NMH_Klima_XIX_E3V_EVCANFD: id 0x1B000046, from Klima, frame-length=8, can-addressing-mode=EXTENDED, can-frame-rx-behavior=CAN-20, can-frame-tx-behavior=CAN-20, rx-identifier-range={lower-can-id=452984832, upper-can-id=452985855}
        nm pdu NMH_Klima_XIX_E3V_EVCANFD: length=8, unused-bit-pattern=0
          signal NM_Klima_CBV_AWB_XIX_NMH_Klima_XIX_E3V_EVCANFD: start 12, 1 bit, little-endian, data-type-policy=OVERRIDE, i-signal-type=PRIMITIVE, init-value=0, base-type=BT_NM_Klima_CBV_AWB, compu {0=Cx0_Passiver_WakeUp (CM_NM_Klima_CBV_AWB_Cx0_Passiver_WakeUp), 1=Cx1_Aktiver_WakeUp (CM_NM_Klima_CBV_AWB_Cx1_Aktiver_WakeUp)}, range raw 0..1, transfer-property=TRIGGERED  # Das Signal ist zu setzen, wenn das SG aktiv den Bus geweckt hat
          signal NM_Klima_CBV_CRI_XIX_NMH_Klima_XIX_E3V_EVCANFD: start 14, 1 bit, little-endian, data-type-policy=OVERRIDE, i-signal-type=PRIMITIVE, base-type=BT_NM_Klima_CBV_CRI, compu {0=Cx0_Standard_Layout (CM_NM_Klima_CBV_CRI_Cx0_Standard_Layout), 1=Cx1_TNB_Layout (CM_NM_Klima_CBV_CRI_Cx1_TNB_Layout)}, range raw 0..1, transfer-property=TRIGGERED  # Das Signal ist dauerhaft gesetzt, wenn das NM-Layout dem neuen NM-Layout für Teilnetzbetrieb entspricht
          signal NM_Klima_NM_State_XIX_NMH_Klima_XIX_E3V_EVCANFD: start 16, 6 bit, little-endian, data-type-policy=OVERRIDE, i-signal-type=PRIMITIVE, init-value=0, base-type=BT_NM_Klima_NM_State, compu {0=Cx0_Init (CM_NM_Klima_NM_State_Cx0_Init), 1=Cx1_NM_RM_aus_BSM (CM_NM_Klima_NM_State_Cx1_NM_RM_aus_BSM), 2=Cx2_NM_RM_aus_PBSM (CM_NM_Klima_NM_State_Cx2_NM_RM_aus_PBSM), 4=Cx4_NM_NO_aus_RM (CM_NM_Klima_NM_State_Cx4_NM_NO_aus_RM), 8=Cx8_NM_NO_aus_RS (CM_NM_Klima_NM_State_Cx8_NM_NO_aus_RS), 16=Cx10_reserved (CM_NM_Klima_NM_State_Cx10_reserved), 32=Cx20_reserved (CM_NM_Klima_NM_State_Cx20_reserved)}, range raw 0..32, transfer-property=TRIGGERED  # 1 = Zustand Repeat Message (<-- Bus-Sleep Mode) 2 = Zustand Repeat Message (<-- Prepare Bus-Sleep Mode) 4 = Zustand Normal Operation (<-- Repeat Message) 8 = Zustand Normal Operation (<-- Ready Sleep)
          signal NM_Klima_Car_Wakeup_XIX_NMH_Klima_XIX_E3V_EVCANFD: start 22, 1 bit, little-endian, data-type-policy=OVERRIDE, i-signal-type=PRIMITIVE, init-value=0, base-type=BT_NM_Klima_Car_Wakeup, compu {0=Cx0_Inaktiv (CM_NM_Klima_Car_Wakeup_Cx0_Inaktiv), 1=Cx1_Car_Wakeup (CM_NM_Klima_Car_Wakeup_Cx1_Car_Wakeup)}, range raw 0..1, transfer-property=TRIGGERED  # Car Wakeup (Gateway wertet aus) MQB: STH einschalten (Zielzeitlogik), Standheizbetrieb angefordert (Sofortheiztaste gedrückt, Ein- und Ausschalten), Restwärmefunktion angefordert, Umentscheidung STL nach STH, Ablauf max Betriebsdauer MLBevo: STH einschalten (Zielzeitlogik), Standheizbetrieb angefordert (Sofortheiztaste gedrückt, Ein- und Ausschalten), Restwärmefunktion angefordert, Umentscheidung STL nach STH, Ablauf max Betriebsdauer
          signal NM_Klima_UDS_CC_XIX_NMH_Klima_XIX_E3V_EVCANFD: start 23, 1 bit, little-endian, data-type-policy=OVERRIDE, i-signal-type=PRIMITIVE, init-value=0, base-type=BT_NM_Klima_UDS_CC, compu {0=Cx0_Init (CM_NM_Klima_UDS_CC_Cx0_Init), 1=Cx1_CC_aktiv (CM_NM_Klima_UDS_CC_Cx1_CC_aktiv)}, range raw 0..1, transfer-property=TRIGGERED  # Funktionseinschränkung aufgrund aktivem UDS-Communication Control; siehe VW80124
          signal NM_Klima_NM_aktiv_KL15_XIX_NMH_Klima_XIX_E3V_EVCANFD: start 24, 1 bit, little-endian, data-type-policy=OVERRIDE, i-signal-type=PRIMITIVE, init-value=0, base-type=BT_NM_Klima_NM_aktiv_KL15, compu {0=Cx0_Inaktiv (CM_NM_Klima_NM_aktiv_KL15_Cx0_Inaktiv), 1=Cx1_KL15_EIN (CM_NM_Klima_NM_aktiv_KL15_Cx1_KL15_EIN)}, range raw 0..1, transfer-property=TRIGGERED  # Steuergerät hat KL15-EIN erkannt
          signal NM_Klima_NM_aktiv_Diagnose_XIX_NMH_Klima_XIX_E3V_EVCANFD: start 25, 1 bit, little-endian, data-type-policy=OVERRIDE, i-signal-type=PRIMITIVE, init-value=0, base-type=BT_NM_Klima_NM_aktiv_Diagnose, compu {0=Cx0_Init (CM_NM_Klima_NM_aktiv_Diagnose_Cx0_Init), 1=Cx1_Diagnose_aktiv (CM_NM_Klima_NM_aktiv_Diagnose_Cx1_Diagnose_aktiv)}, range raw 0..1, transfer-property=TRIGGERED  # Diagnose befindet sich nach VW80124 in einer NonDefaultDiagnostic-Session, z.B. ExtendedDiagnostic-Session
          signal NM_Klima_NM_aktiv_Tmin_XIX_NMH_Klima_XIX_E3V_EVCANFD: start 26, 1 bit, little-endian, data-type-policy=OVERRIDE, i-signal-type=PRIMITIVE, init-value=0, base-type=BT_NM_Klima_NM_aktiv_Tmin, compu {0=Cx0_Inaktiv (CM_NM_Klima_NM_aktiv_Tmin_Cx0_Inaktiv), 1=Cx1_Mindestaktivzeit (CM_NM_Klima_NM_aktiv_Tmin_Cx1_Mindestaktivzeit)}, range raw 0..1, transfer-property=TRIGGERED  # Mindestaktivzeit ist noch nicht abgelaufen (bei jedem Weckereignis wird die Mindestaktivzeit neu gestartet)
          signal NM_Klima_CAB_V15_XIX_NMH_Klima_XIX_E3V_EVCANFD: start 40, 24 bit, opaque, data-type-policy=OVERRIDE, i-signal-type=ARRAY, init-value=[0b00000000, 0b00000000, 0b00000000], base-type=BT_NM_Klima_CAB_V15, compu {0=Cx0_Init (CM_NM_Klima_CAB_V15_Cx0_Init), 1=Cx1_CAB_01_Antrieb (CM_NM_Klima_CAB_V15_Cx1_CAB_01_Antrieb), 2=Cx2_CAB_02_Hybrid_Laden (CM_NM_Klima_CAB_V15_Cx2_CAB_02_Hybrid_Laden), 4=Cx4_CAB_03_Fahrwerk (CM_NM_Klima_CAB_V15_Cx4_CAB_03_Fahrwerk), 8=Cx8_CAB_04_Fahrerassistenz (CM_NM_Klima_CAB_V15_Cx8_CAB_04_Fahrerassistenz), 16=Cx10_CAB_05_Komfort (CM_NM_Klima_CAB_V15_Cx10_CAB_05_Komfort), 32=Cx20_CAB_06_Anzeige (CM_NM_Klima_CAB_V15_Cx20_CAB_06_Anzeige), 64=Cx40_CAB_07_Connect (CM_NM_Klima_CAB_V15_Cx40_CAB_07_Connect), 128=Cx80_CAB_08_MIB (CM_NM_Klima_CAB_V15_Cx80_CAB_08_MIB), 256=Cx100_CAB_09_Standheizung (CM_NM_Klima_CAB_V15_Cx100_CAB_09_Standheizung), 512=Cx200_CAB_10_MDK (CM_NM_Klima_CAB_V15_Cx200_CAB_10_MDK), 1024=Cx400_CAB_11_VLAN_Fahrerassistenz (CM_NM_Klima_CAB_V15_Cx400_CAB_11_VLAN_Fahrerassistenz), 4096=Cx1000_CAB_13_VLAN_Connect (CM_NM_Klima_CAB_V15_Cx1000_CAB_13_VLAN_Connect), 8192=Cx2000_CAB_14_VLAN_Infotainment (CM_NM_Klima_CAB_V15_Cx2000_CAB_14_VLAN_Infotainment), 16384=Cx4000_CAB_15_Laden (CM_NM_Klima_CAB_V15_Cx4000_CAB_15_Laden), 32768=Cx8000_CAB_16_Licht (CM_NM_Klima_CAB_V15_Cx8000_CAB_16_Licht), 65536=Cx10000_CAB_17_RTM (CM_NM_Klima_CAB_V15_Cx10000_CAB_17_RTM)}, range raw 0..65536, transfer-property=TRIGGERED  # CAB = Clusteraktivbits (V15)
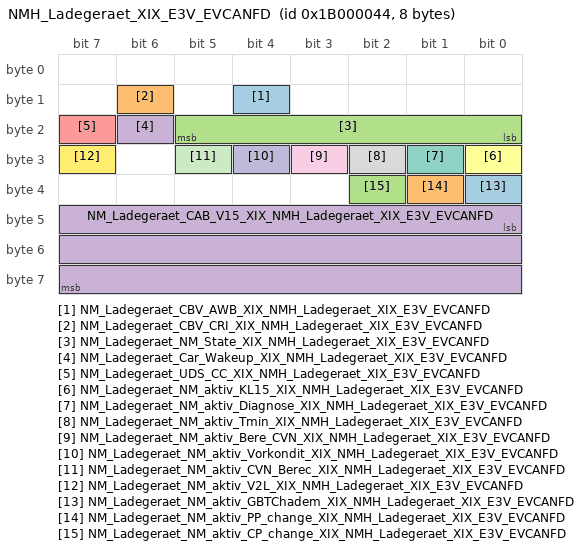
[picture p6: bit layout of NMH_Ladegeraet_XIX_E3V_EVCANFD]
      frame NMH_Ladegeraet_XIX_E3V_EVCANFD: id 0x1B000044, to Klima, frame-length=8, can-addressing-mode=EXTENDED, can-frame-rx-behavior=CAN-20, can-frame-tx-behavior=CAN-20, rx-identifier-range={lower-can-id=452984832, upper-can-id=452985855}
        nm pdu NMH_Ladegeraet_XIX_E3V_EVCANFD: length=8, unused-bit-pattern=0
          signal NM_Ladegeraet_CBV_AWB_XIX_NMH_Ladegeraet_XIX_E3V_EVCANFD: start 12, 1 bit, little-endian, data-type-policy=OVERRIDE, i-signal-type=PRIMITIVE, init-value=0, base-type=BT_NM_Ladegeraet_CBV_AWB, compu {0=Cx0_Passiver_WakeUp (CM_NM_Ladegeraet_CBV_AWB_Cx0_Passiver_WakeUp), 1=Cx1_Aktiver_WakeUp (CM_NM_Ladegeraet_CBV_AWB_Cx1_Aktiver_WakeUp)}, range raw 0..1, transfer-property=TRIGGERED  # Das Signal ist zu setzen, wenn das SG aktiv den Bus geweckt hat 0 = Passiver_WakeUp = SG hat das Netzwerk nicht aktiv geweckt 1 = Akitiver_WakeUp = SG hat das Netzwerk aktiv geweckt
          signal NM_Ladegeraet_CBV_CRI_XIX_NMH_Ladegeraet_XIX_E3V_EVCANFD: start 14, 1 bit, little-endian, data-type-policy=OVERRIDE, i-signal-type=PRIMITIVE, base-type=BT_NM_Ladegeraet_CBV_CRI, compu {0=Cx0_NM_ohne_Clusteranforderungen (CM_NM_Ladegeraet_CBV_CRI_Cx0_NM_ohne_Clusteranforderungen), 1=Cx1_NM_mit_Clusteranforderungen (CM_NM_Ladegeraet_CBV_CRI_Cx1_NM_mit_Clusteranforderungen)}, range raw 0..1, transfer-property=TRIGGERED  # Das Signal ist dauerhaft gesetzt, wenn das NM-Layout Cluster- Anforderungen enthält
          signal NM_Ladegeraet_NM_State_XIX_NMH_Ladegeraet_XIX_E3V_EVCANFD: start 16, 6 bit, little-endian, data-type-policy=OVERRIDE, i-signal-type=PRIMITIVE, init-value=0, base-type=BT_NM_Ladegeraet_NM_State, compu {0=Cx0_Init (CM_NM_Ladegeraet_NM_State_Cx0_Init), 1=Cx1_NM_RM_aus_BSM (CM_NM_Ladegeraet_NM_State_Cx1_NM_RM_aus_BSM), 2=Cx2_NM_RM_aus_PBSM (CM_NM_Ladegeraet_NM_State_Cx2_NM_RM_aus_PBSM), 4=Cx4_NM_NO_aus_RM (CM_NM_Ladegeraet_NM_State_Cx4_NM_NO_aus_RM), 8=Cx8_NM_NO_aus_RS (CM_NM_Ladegeraet_NM_State_Cx8_NM_NO_aus_RS), 16=Cx10_reserved (CM_NM_Ladegeraet_NM_State_Cx10_reserved), 32=Cx20_reserved (CM_NM_Ladegeraet_NM_State_Cx20_reserved)}, range raw 0..32, transfer-property=TRIGGERED, to Klima(timeout 2 s)  # 1 = Zustand Repeat Message (<-- Bus-Sleep Mode) 2 = Zustand Repeat Message (<-- Prepare Bus-Sleep Mode) 4 = Zustand Normal Operation (<-- Repeat Message) 8 = Zustand Normal Operation (<-- Ready Sleep)
          signal NM_Ladegeraet_Car_Wakeup_XIX_NMH_Ladegeraet_XIX_E3V_EVCANFD: start 22, 1 bit, little-endian, data-type-policy=OVERRIDE, i-signal-type=PRIMITIVE, init-value=0, base-type=BT_NM_Ladegeraet_Car_Wakeup, compu {0=Cx0_Inaktiv (CM_NM_Ladegeraet_Car_Wakeup_Cx0_Inaktiv), 1=Cx1_Car_Wakeup (CM_NM_Ladegeraet_Car_Wakeup_Cx1_Car_Wakeup)}, range raw 0..1, transfer-property=TRIGGERED  # Car Wakeup (Gateway wertet aus) MQB: Ladestecker gesteckt, entfernt, verriegelt oder entriegelt
          signal NM_Ladegeraet_UDS_CC_XIX_NMH_Ladegeraet_XIX_E3V_EVCANFD: start 23, 1 bit, little-endian, data-type-policy=OVERRIDE, i-signal-type=PRIMITIVE, init-value=0, base-type=BT_NM_Ladegeraet_UDS_CC, compu {0=Cx0_Init (CM_NM_Ladegeraet_UDS_CC_Cx0_Init), 1=Cx1_CC_aktiv (CM_NM_Ladegeraet_UDS_CC_Cx1_CC_aktiv)}, range raw 0..1, transfer-property=TRIGGERED  # Funktionseinschränkung aufgrund aktivem UDS-Communication Control; siehe VW80124
          signal NM_Ladegeraet_NM_aktiv_KL15_XIX_NMH_Ladegeraet_XIX_E3V_EVCANFD: start 24, 1 bit, little-endian, data-type-policy=OVERRIDE, i-signal-type=PRIMITIVE, init-value=0, base-type=BT_NM_Ladegeraet_NM_aktiv_KL15, compu {0=Cx0_Inaktiv (CM_NM_Ladegeraet_NM_aktiv_KL15_Cx0_Inaktiv), 1=Cx1_KL15_EIN (CM_NM_Ladegeraet_NM_aktiv_KL15_Cx1_KL15_EIN)}, range raw 0..1, transfer-property=TRIGGERED  # Steuergerät hat KL15-EIN erkannt
          signal NM_Ladegeraet_NM_aktiv_Diagnose_XIX_NMH_Ladegeraet_XIX_E3V_EVCANFD: start 25, 1 bit, little-endian, data-type-policy=OVERRIDE, i-signal-type=PRIMITIVE, init-value=0, base-type=BT_NM_Ladegeraet_NM_aktiv_Diagnose, compu {0=Cx0_Init (CM_NM_Ladegeraet_NM_aktiv_Diagnose_Cx0_Init), 1=Cx1_Diagnose_aktiv (CM_NM_Ladegeraet_NM_aktiv_Diagnose_Cx1_Diagnose_aktiv)}, range raw 0..1, transfer-property=TRIGGERED  # Diagnose befindet sich nach VW80124 in einer NonDefaultDiagnostic-Session, z.B. ExtendedDiagnostic-Session
          signal NM_Ladegeraet_NM_aktiv_Tmin_XIX_NMH_Ladegeraet_XIX_E3V_EVCANFD: start 26, 1 bit, little-endian, data-type-policy=OVERRIDE, i-signal-type=PRIMITIVE, init-value=0, base-type=BT_NM_Ladegeraet_NM_aktiv_Tmin, compu {0=Cx0_Inaktiv (CM_NM_Ladegeraet_NM_aktiv_Tmin_Cx0_Inaktiv), 1=Cx1_Mindestaktivzeit (CM_NM_Ladegeraet_NM_aktiv_Tmin_Cx1_Mindestaktivzeit)}, range raw 0..1, transfer-property=TRIGGERED  # Mindestaktivzeit ist noch nicht abgelaufen (bei jedem Weckereignis wird die Mindestaktivzeit neu gestartet)
          signal NM_Ladegeraet_NM_aktiv_Bere_CVN_XIX_NMH_Ladegeraet_XIX_E3V_EVCANFD: start 27, 1 bit, little-endian, data-type-policy=OVERRIDE, i-signal-type=PRIMITIVE, init-value=0, base-type=BT_NM_Ladegeraet_NM_aktiv_Bere_CVN, compu {0=Cx0_Init (CM_NM_Ladegeraet_NM_aktiv_Bere_CVN_Cx0_Init), 1=Cx1_CVN_Berechnung_aktiv (CM_NM_Ladegeraet_NM_aktiv_Bere_CVN_Cx1_CVN_Berechnung_aktiv)}, range raw 0..1, transfer-property=TRIGGERED  # Aktiver Nachlauf aufgrund Berechnung des CVN, bei jedem Klemme 15 Wechsel von AUS-->AN Dauer ca. 30s
          signal NM_Ladegeraet_NM_aktiv_Vorkondit_XIX_NMH_Ladegeraet_XIX_E3V_EVCANFD: start 28, 1 bit, little-endian, data-type-policy=OVERRIDE, i-signal-type=PRIMITIVE, init-value=0, base-type=BT_NM_Ladegeraet_NM_aktiv_Vorkondit, compu {0=Cx0_kein_Nachlauf (CM_NM_Ladegeraet_NM_aktiv_Vorkondit_Cx0_kein_Nachlauf), 1=Cx1_Vorkonditionierung_aktiv (CM_NM_Ladegeraet_NM_aktiv_Vorkondit_Cx1_Vorkonditionierung_aktiv)}, range raw 0..1, transfer-property=TRIGGERED  # Wachhalten aufgrund Vorkonditionierung
          signal NM_Ladegeraet_NM_aktiv_CVN_Berec_XIX_NMH_Ladegeraet_XIX_E3V_EVCANFD: start 29, 1 bit, little-endian, data-type-policy=OVERRIDE, i-signal-type=PRIMITIVE, init-value=0, base-type=BT_NM_Ladegeraet_NM_aktiv_CVN_Berec, compu {0=Cx0_kein_Nachlauf (CM_NM_Ladegeraet_NM_aktiv_CVN_Berec_Cx0_kein_Nachlauf), 1=Cx1_CVN_Berechnung_aktiv (CM_NM_Ladegeraet_NM_aktiv_CVN_Berec_Cx1_CVN_Berechnung_aktiv)}, range raw 0..1, transfer-property=TRIGGERED  # Berechnung CVN ist aktiv
          signal NM_Ladegeraet_NM_aktiv_V2L_XIX_NMH_Ladegeraet_XIX_E3V_EVCANFD: start 31, 1 bit, little-endian, data-type-policy=OVERRIDE, i-signal-type=PRIMITIVE, init-value=0, base-type=BT_NM_Ladegeraet_NM_aktiv_V2L, compu {0=Cx0_Init (CM_NM_Ladegeraet_NM_aktiv_V2L_Cx0_Init), 1=Cx1_VehicleToLoad_aktiv (CM_NM_Ladegeraet_NM_aktiv_V2L_Cx1_VehicleToLoad_aktiv)}, range raw 0..1, transfer-property=TRIGGERED  # Bus gefordert bei VehilcleToLoad
          signal NM_Ladegeraet_NM_aktiv_GBTChadem_XIX_NMH_Ladegeraet_XIX_E3V_EVCANFD: start 32, 1 bit, little-endian, data-type-policy=OVERRIDE, i-signal-type=PRIMITIVE, init-value=0, base-type=BT_NM_Ladegeraet_NM_aktiv_GBTChadem, compu {0=Cx0_Init (CM_NM_Ladegeraet_NM_aktiv_GBTChadem_Cx0_Init), 1=Cx1_Statusaend_Ladedose_GBT_Chademo (CM_NM_Ladegeraet_NM_aktiv_GBTChadem_Cx1_Statusaend_Ladedose_GBT_Chademo)}, range raw 0..1, transfer-property=TRIGGERED  # Bus gefordert bei Statusänderung HW-Eingang Ladedose GBT oder Chademo
          signal NM_Ladegeraet_NM_aktiv_PP_change_XIX_NMH_Ladegeraet_XIX_E3V_EVCANFD: start 33, 1 bit, little-endian, data-type-policy=OVERRIDE, i-signal-type=PRIMITIVE, init-value=0, base-type=BT_NM_Ladegeraet_NM_aktiv_PP_change, compu {0=Cx0_Init (CM_NM_Ladegeraet_NM_aktiv_PP_change_Cx0_Init), 1=Cx1_Statusaenderung_PP (CM_NM_Ladegeraet_NM_aktiv_PP_change_Cx1_Statusaenderung_PP)}, range raw 0..1, transfer-property=TRIGGERED  # Bus gefordert bei Statusänderung Proximity Pilot Pin
          signal NM_Ladegeraet_NM_aktiv_CP_change_XIX_NMH_Ladegeraet_XIX_E3V_EVCANFD: start 34, 1 bit, little-endian, data-type-policy=OVERRIDE, i-signal-type=PRIMITIVE, init-value=0, base-type=BT_NM_Ladegeraet_NM_aktiv_CP_change, compu {0=Cx0_Init (CM_NM_Ladegeraet_NM_aktiv_CP_change_Cx0_Init), 1=Cx1_Statusaenderung_CP (CM_NM_Ladegeraet_NM_aktiv_CP_change_Cx1_Statusaenderung_CP)}, range raw 0..1, transfer-property=TRIGGERED  # Bus gefordert bei Statusänderung Control Pilot Pin
          signal NM_Ladegeraet_CAB_V15_XIX_NMH_Ladegeraet_XIX_E3V_EVCANFD: start 40, 24 bit, opaque, data-type-policy=OVERRIDE, i-signal-type=ARRAY, init-value=[0b00000000, 0b00000000, 0b00000000], base-type=BT_NM_Ladegeraet_CAB_V15, compu {0=Cx0_Init (CM_NM_Ladegeraet_CAB_V15_Cx0_Init), 1=Cx1_CAB_01_Antrieb (CM_NM_Ladegeraet_CAB_V15_Cx1_CAB_01_Antrieb), 2=Cx2_CAB_02_Hybrid_Laden (CM_NM_Ladegeraet_CAB_V15_Cx2_CAB_02_Hybrid_Laden), 4=Cx4_CAB_03_Fahrwerk (CM_NM_Ladegeraet_CAB_V15_Cx4_CAB_03_Fahrwerk), 8=Cx8_CAB_04_Fahrerassistenz (CM_NM_Ladegeraet_CAB_V15_Cx8_CAB_04_Fahrerassistenz), 16=Cx10_CAB_05_Komfort (CM_NM_Ladegeraet_CAB_V15_Cx10_CAB_05_Komfort), 32=Cx20_CAB_06_Anzeige (CM_NM_Ladegeraet_CAB_V15_Cx20_CAB_06_Anzeige), 64=Cx40_CAB_07_Connect (CM_NM_Ladegeraet_CAB_V15_Cx40_CAB_07_Connect), 128=Cx80_CAB_08_MIB (CM_NM_Ladegeraet_CAB_V15_Cx80_CAB_08_MIB), 256=Cx100_CAB_09_Standheizung (CM_NM_Ladegeraet_CAB_V15_Cx100_CAB_09_Standheizung), 512=Cx200_CAB_10_MDK (CM_NM_Ladegeraet_CAB_V15_Cx200_CAB_10_MDK), 1024=Cx400_CAB_11_VLAN_Fahrerassistenz (CM_NM_Ladegeraet_CAB_V15_Cx400_CAB_11_VLAN_Fahrerassistenz), 4096=Cx1000_CAB_13_VLAN_Connect (CM_NM_Ladegeraet_CAB_V15_Cx1000_CAB_13_VLAN_Connect), 8192=Cx2000_CAB_14_VLAN_Infotainment (CM_NM_Ladegeraet_CAB_V15_Cx2000_CAB_14_VLAN_Infotainment), 16384=Cx4000_CAB_15_Laden (CM_NM_Ladegeraet_CAB_V15_Cx4000_CAB_15_Laden), 32768=Cx8000_CAB_16_Licht (CM_NM_Ladegeraet_CAB_V15_Cx8000_CAB_16_Licht), 65536=Cx10000_CAB_17_RTM (CM_NM_Ladegeraet_CAB_V15_Cx10000_CAB_17_RTM)}, range raw 0..65536, transfer-property=TRIGGERED  # CAB = Clusteraktivbits (V15)
      frame OBDC_Funktionaler_Req_All_FD_XIX_E3V_EVCANFD: id 0x1C410200, to Klima, frame-length=64, can-addressing-mode=EXTENDED, can-frame-rx-behavior=CAN-FD, can-frame-tx-behavior=CAN-FD
        n pdu OBDC_Funktionaler_Req_All_FD_XIX_E3V_EVCANFD: length=64
      frame OBDC_Klima_Req_FD_XIX_E3V_EVCANFD: id 0x1C400246, to Klima, frame-length=64, can-addressing-mode=EXTENDED, can-frame-rx-behavior=CAN-FD, can-frame-tx-behavior=CAN-FD
        n pdu OBDC_Klima_Req_FD_XIX_E3V_EVCANFD: length=64
      frame OBDC_Klima_Resp_FD_XIX_E3V_EVCANFD: id 0x1C420246, from Klima, frame-length=64, can-addressing-mode=EXTENDED, can-frame-rx-behavior=CAN-FD, can-frame-tx-behavior=CAN-FD
        n pdu OBDC_Klima_Resp_FD_XIX_E3V_EVCANFD: length=64
      frame OBDx_allOBD_Req_XIX_E3V_EVCANFD: id 0x18DB33F1, to Klima, frame-length=8, can-addressing-mode=EXTENDED, can-frame-rx-behavior=CAN-FD, can-frame-tx-behavior=CAN-FD
        n pdu OBDx_allOBD_Req_XIX_E3V_EVCANFD: length=8
      frame OBDx_Klima_Req_XIX_E3V_EVCANFD: id 0x18DA0AF1, to Klima, frame-length=8, can-addressing-mode=EXTENDED, can-frame-rx-behavior=CAN-FD, can-frame-tx-behavior=CAN-FD
        n pdu OBDx_Klima_Req_XIX_E3V_EVCANFD: length=8
      frame OBDx_Klima_Resp_XIX_E3V_EVCANFD: id 0x18DAF10A, from Klima, frame-length=8, can-addressing-mode=EXTENDED, can-frame-rx-behavior=CAN-FD, can-frame-tx-behavior=CAN-FD
        n pdu OBDx_Klima_Resp_XIX_E3V_EVCANFD: length=8
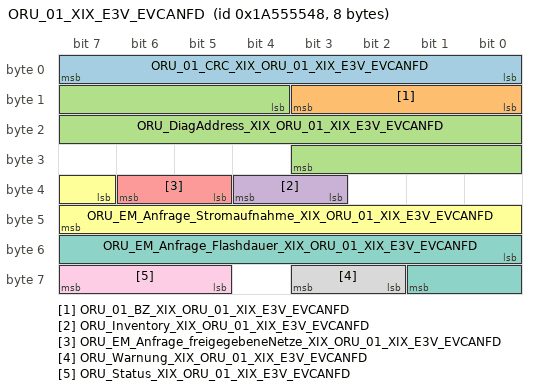
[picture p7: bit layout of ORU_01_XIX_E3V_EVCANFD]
      frame ORU_01_XIX_E3V_EVCANFD: id 0x1A555548, to Klima, frame-length=8, can-addressing-mode=EXTENDED, can-frame-rx-behavior=CAN-FD, can-frame-tx-behavior=CAN-FD
        pdu ORU_01_XIX_E3V_EVCANFD: length=8, minimum-delay=0.1, transmission-mode-true-timing={cyclic-timing={time-offset=0.0, time-period=0.5}, event-controlled-timing={number-of-repetitions=0, repetition-period=0.0}}, unused-bit-pattern=0
          signal ORU_01_CRC_XIX_ORU_01_XIX_E3V_EVCANFD: start 0, 8 bit, little-endian, data-type-policy=OVERRIDE, i-signal-type=PRIMITIVE, base-type=BT_ORU_01_CRC, compu {phys=raw for raw 0..255}, range phys 0..255, raw 0..255, transfer-property=PENDING
          signal ORU_01_BZ_XIX_ORU_01_XIX_E3V_EVCANFD: start 8, 4 bit, little-endian, data-type-policy=OVERRIDE, i-signal-type=PRIMITIVE, base-type=BT_ORU_01_BZ, compu {phys=raw for raw 0..15}, range phys 0..15, raw 0..15, transfer-property=PENDING
          signal ORU_DiagAddress_XIX_ORU_01_XIX_E3V_EVCANFD: start 12, 16 bit, little-endian, data-type-policy=OVERRIDE, i-signal-type=PRIMITIVE, init-value=0, base-type=BT_ORU_DiagAddress, compu {phys=raw for raw 0..65535}, range phys 0..65535, raw 0..65535, transfer-property=PENDING  # Diagnostic address of next ECU to be updated
          signal ORU_Inventory_XIX_ORU_01_XIX_E3V_EVCANFD: start 35, 2 bit, little-endian, data-type-policy=OVERRIDE, i-signal-type=PRIMITIVE, init-value=0, base-type=BT_ORU_Inventory, compu {0=Cx0_Init (CM_ORU_Inventory_Cx0_Init), 1=Cx1_Inventory_Erstellung_nicht_aktiv (CM_ORU_Inventory_Cx1_Inventory_Erstellung_nicht_aktiv), 2=Cx2_Inventory_Erstellung_aktiv (CM_ORU_Inventory_Cx2_Inventory_Erstellung_aktiv)}, range raw 0..2, transfer-property=PENDING  # Signal zur Anzeige, ob die Inventory Erstellung durch ORU aktiv ist. 0 = Init 1 = ORU Inventory Erstellung ist nicht aktiv 2 = ORU Inventory Erstellung ist aktiv
          signal ORU_EM_Anfrage_freigegebeneNetze_XIX_ORU_01_XIX_E3V_EVCANFD: start 37, 2 bit, little-endian, data-type-policy=OVERRIDE, i-signal-type=PRIMITIVE, init-value=0, base-type=BT_ORU_EM_Anfrage_freigegebeneNetze, compu {0=Cx0_only_12V (CM_ORU_EM_Anfrage_freigegebeneNetze_Cx0_only_12V), 1=Cx1_networks_48V_and_12V (CM_ORU_EM_Anfrage_freigegebeneNetze_Cx1_networks_48V_and_12V), 2=Cx2_networks_HV_and_12V (CM_ORU_EM_Anfrage_freigegebeneNetze_Cx2_networks_HV_and_12V), 3=Cx3_networks_HV_and_48V_and_12V (CM_ORU_EM_Anfrage_freigegebeneNetze_Cx3_networks_HV_and_48V_and_12V)}, range raw 0..3, transfer-property=TRIGGERED-ON-CHANGE-WITHOUT-REPETITION, to Klima(timeout 5 s)  # Meldung der während eines konkreten Online Remote Updates freigegebenen Netze (12V, 48V, HV)
          signal ORU_EM_Anfrage_Stromaufnahme_XIX_ORU_01_XIX_E3V_EVCANFD: start 39, 9 bit, little-endian, data-type-policy=OVERRIDE, i-signal-type=PRIMITIVE, init-value=0, base-type=BT_ORU_EM_Anfrage_Stromaufnahme, compu {phys=raw*0.1 for raw 0..511; unit Unit_Amper}, range phys 0..51.1 Unit_Amper, raw 0..511, unit=Unit_Amper, transfer-property=TRIGGERED-ON-CHANGE-WITHOUT-REPETITION, to Klima(timeout 5 s)  # Meldung der voraussichtlichen durchschnittlichen Stromaufnahme eines konkreten Online Remote Updates an das NVEM
          signal ORU_EM_Anfrage_Flashdauer_XIX_ORU_01_XIX_E3V_EVCANFD: start 48, 10 bit, little-endian, data-type-policy=OVERRIDE, i-signal-type=PRIMITIVE, init-value=0, base-type=BT_ORU_EM_Anfrage_Flashdauer, compu {phys=raw*10 for raw 0..1023; unit Unit_Secon}, range phys 0..10230 Unit_Secon, raw 0..1023, unit=Unit_Secon, transfer-property=TRIGGERED-ON-CHANGE-WITHOUT-REPETITION, to Klima(timeout 5 s)  # Anfrage an das Energiemanagement, ob ein konkretes Online Remote Update durchgeführt werden kann - Flashdauer in 10s.
          signal ORU_Warnung_XIX_ORU_01_XIX_E3V_EVCANFD: start 58, 2 bit, little-endian, data-type-policy=OVERRIDE, i-signal-type=PRIMITIVE, init-value=0, base-type=BT_ORU_Warnung, compu {0=Cx0_keine_Anzeige (CM_ORU_Warnung_Cx0_keine_Anzeige), 1=Cx1_Update_unvollstaendig_Prio1 (CM_ORU_Warnung_Cx1_Update_unvollstaendig_Prio1), 2=Cx2_Update_fehlgeschlagen_Prio1 (CM_ORU_Warnung_Cx2_Update_fehlgeschlagen_Prio1), 3=Cx3_reserviert (CM_ORU_Warnung_Cx3_reserviert)}, range raw 0..3, transfer-property=TRIGGERED-ON-CHANGE-WITHOUT-REPETITION  # Wenn durch Störungen der Funktion Online Remote Update nicht sichergestellt ist, dass vor Kunde keine Funktionseinschränkungen auftreten, muss der Benutzer des Fahrzeugs entsprechend gewarnt werden.
          signal ORU_Status_XIX_ORU_01_XIX_E3V_EVCANFD: start 61, 3 bit, little-endian, data-type-policy=OVERRIDE, i-signal-type=PRIMITIVE, init-value=0, base-type=BT_ORU_Status, compu {0=Cx0_IDLE (CM_ORU_Status_Cx0_IDLE), 1=Cx1_PENDING (CM_ORU_Status_Cx1_PENDING), 2=Cx2_PREPARATION (CM_ORU_Status_Cx2_PREPARATION), 3=Cx3_PREPARATION_HV (CM_ORU_Status_Cx3_PREPARATION_HV), 4=Cx4_RUNNING (CM_ORU_Status_Cx4_RUNNING), 5=Cx5_RUNNING_HV (CM_ORU_Status_Cx5_RUNNING_HV), 6=Cx6_PENDING_NOTREADY (CM_ORU_Status_Cx6_PENDING_NOTREADY), 7=Cx7_FAILURE_POWERTRAIN_DISABLED (CM_ORU_Status_Cx7_FAILURE_POWERTRAIN_DISABLED)}, range raw 0..7, transfer-property=TRIGGERED-ON-CHANGE-WITHOUT-REPETITION, to Klima(timeout 5 s)  # Verteilung des internen ORU Zustandes
      frame ORU_03_XIX_E3V_EVCANFD: id 0x1A555842, to Klima, frame-length=8, can-addressing-mode=EXTENDED, can-frame-rx-behavior=CAN-FD, can-frame-tx-behavior=CAN-FD
        pdu ORU_03_XIX_E3V_EVCANFD: length=8, transmission-mode-true-timing=cyclic-timing={time-offset=0, time-period=1.0}, unused-bit-pattern=0
          signal ORU_AP_Mode_XIX_ORU_03_XIX_E3V_EVCANFD: start 12, 2 bit, little-endian, data-type-policy=OVERRIDE, i-signal-type=PRIMITIVE, init-value=3, base-type=BT_ORU_AP_Mode, compu {0=Cx0_NO_AP_MODE (CM_ORU_AP_Mode_Cx0_NO_AP_MODE), 1=Cx1_AP_MODE (CM_ORU_AP_Mode_Cx1_AP_MODE), 2=Cx2_RESERVED (CM_ORU_AP_Mode_Cx2_RESERVED), 3=Cx3_INIT (CM_ORU_AP_Mode_Cx3_INIT)}, range raw 0..3, transfer-property=PENDING, to Klima(timeout 5 s)  # AfterProd Mode für ORU@Factory und weitere zukünftige Anwendungsfälle wie AFiF
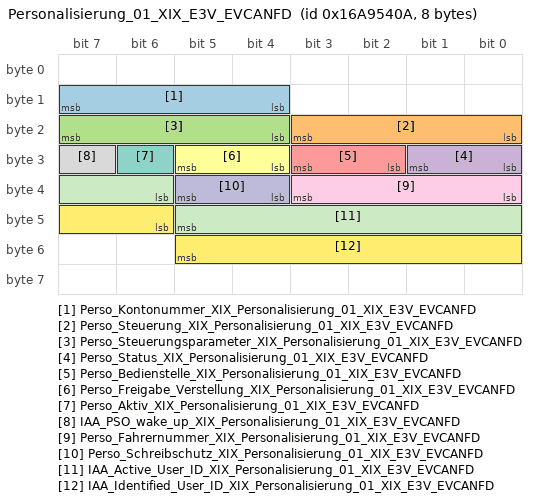
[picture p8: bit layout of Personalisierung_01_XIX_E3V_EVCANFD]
      frame Personalisierung_01_XIX_E3V_EVCANFD: id 0x16A9540A, to Klima, frame-length=8, can-addressing-mode=EXTENDED, can-frame-rx-behavior=CAN-FD, can-frame-tx-behavior=CAN-FD
        pdu Personalisierung_01_XIX_E3V_EVCANFD: length=8, minimum-delay=0.05, transmission-mode-true-timing={cyclic-timing={time-offset=0.0, time-period=1.0}, event-controlled-timing={number-of-repetitions=3, repetition-period=0.2}}, unused-bit-pattern=0
          signal Perso_Kontonummer_XIX_Personalisierung_01_XIX_E3V_EVCANFD: start 12, 4 bit, little-endian, data-type-policy=OVERRIDE, i-signal-type=PRIMITIVE, init-value=0, base-type=BT_Perso_Kontonummer, compu {0=Cx0_kein_Benutzerkonto (CM_Perso_Kontonummer_Cx0_kein_Benutzerkonto), 1=Cx1_Benutzerkonto_1 (CM_Perso_Kontonummer_Cx1_Benutzerkonto_1), 2=Cx2_Benutzerkonto_2 (CM_Perso_Kontonummer_Cx2_Benutzerkonto_2), 3=Cx3_Benutzerkonto_3 (CM_Perso_Kontonummer_Cx3_Benutzerkonto_3), 4=Cx4_Benutzerkonto_4 (CM_Perso_Kontonummer_Cx4_Benutzerkonto_4), 5=Cx5_Benutzerkonto_5 (CM_Perso_Kontonummer_Cx5_Benutzerkonto_5), 6=Cx6_Benutzerkonto_6 (CM_Perso_Kontonummer_Cx6_Benutzerkonto_6), 7=Cx7_Benutzerkonto_7 (CM_Perso_Kontonummer_Cx7_Benutzerkonto_7)}, range raw 0..7, transfer-property=TRIGGERED-ON-CHANGE, to Klima(timeout 5 s)  # Signal gibt die jewels aktuelle Kontonummer für die Personalisierung an. Nicht für AU736 und AU48x.
          signal Perso_Steuerung_XIX_Personalisierung_01_XIX_E3V_EVCANFD: start 16, 4 bit, little-endian, data-type-policy=OVERRIDE, i-signal-type=PRIMITIVE, init-value=0, base-type=BT_Perso_Steuerung, compu {0=Cx0_keine_Steuerung (CM_Perso_Steuerung_Cx0_keine_Steuerung), 1=Cx1_Reset_alle_Konten (CM_Perso_Steuerung_Cx1_Reset_alle_Konten), 2=Cx2_Reset_aktives_Konto (CM_Perso_Steuerung_Cx2_Reset_aktives_Konto), 3=Cx3_Kopiere_aktives_Konto_nach (CM_Perso_Steuerung_Cx3_Kopiere_aktives_Konto_nach), 4=Cx4_Wiederherstellen_aktives_Konto (CM_Perso_Steuerung_Cx4_Wiederherstellen_aktives_Konto), 5=Cx5_Aktivieren_aktives_Konto (CM_Perso_Steuerung_Cx5_Aktivieren_aktives_Konto), 6=Cx6_Reset_Konto (CM_Perso_Steuerung_Cx6_Reset_Konto), 7=Cx7_Reset_alle_Fahrer (CM_Perso_Steuerung_Cx7_Reset_alle_Fahrer), 8=Cx8_Reset_aktiver_Fahrer (CM_Perso_Steuerung_Cx8_Reset_aktiver_Fahrer), 9=Cx9_Reset_Fahrer (CM_Perso_Steuerung_Cx9_Reset_Fahrer)}, range raw 0..9, transfer-property=TRIGGERED-ON-CHANGE, to Klima(timeout 5 s)  # Signal gibt einen Steuerungsbefehl an die Funktionsteilnehmer der Personalisierung. Nicht für AU736 und AU49x.
          signal Perso_Steuerungsparameter_XIX_Personalisierung_01_XIX_E3V_EVCANFD: start 20, 4 bit, little-endian, data-type-policy=OVERRIDE, i-signal-type=PRIMITIVE, init-value=0, base-type=BT_Perso_Steuerungsparameter, compu {0=Cx0_kein_Parameter (CM_Perso_Steuerungsparameter_Cx0_kein_Parameter), 1=Cx1_Benutzerkonto_1 (CM_Perso_Steuerungsparameter_Cx1_Benutzerkonto_1), 2=Cx2_Benutzerkonto_2 (CM_Perso_Steuerungsparameter_Cx2_Benutzerkonto_2), 3=Cx3_Benutzerkonto_3 (CM_Perso_Steuerungsparameter_Cx3_Benutzerkonto_3), 4=Cx4_Benutzerkonto_4 (CM_Perso_Steuerungsparameter_Cx4_Benutzerkonto_4), 5=Cx5_Benutzerkonto_5 (CM_Perso_Steuerungsparameter_Cx5_Benutzerkonto_5), 6=Cx6_Benutzerkonto_6 (CM_Perso_Steuerungsparameter_Cx6_Benutzerkonto_6), 7=Cx7_Benutzerkonto_7 (CM_Perso_Steuerungsparameter_Cx7_Benutzerkonto_7)}, range raw 0..7, transfer-property=TRIGGERED-ON-CHANGE, to Klima(timeout 5 s)  # Signal gibt einen Parameter zum Steuerungsbefehl (Signal Perso_Steuerung) für die Personalisierung an. Nicht für AU736 und AU49x.
          signal Perso_Status_XIX_Personalisierung_01_XIX_E3V_EVCANFD: start 24, 2 bit, little-endian, data-type-policy=OVERRIDE, i-signal-type=PRIMITIVE, init-value=0, base-type=BT_Perso_Status, compu {0=Cx0_deaktiviert (CM_Perso_Status_Cx0_deaktiviert), 1=Cx1_PSO_1x_aktiviert (CM_Perso_Status_Cx1_PSO_1x_aktiviert), 2=Cx2_PSO_2x_aktiviert (CM_Perso_Status_Cx2_PSO_2x_aktiviert)}, range raw 0..2, transfer-property=TRIGGERED-WITHOUT-REPETITION, to Klima(timeout 5 s)  # Codierstatus der Personalisierung Nicht für AU736 und AU49x.
          signal Perso_Bedienstelle_XIX_Personalisierung_01_XIX_E3V_EVCANFD: start 26, 2 bit, little-endian, data-type-policy=OVERRIDE, i-signal-type=PRIMITIVE, init-value=0, base-type=BT_Perso_Bedienstelle, compu {0=Cx0_Init (CM_Perso_Bedienstelle_Cx0_Init), 1=Cx1_Kombiinstrument (CM_Perso_Bedienstelle_Cx1_Kombiinstrument), 2=Cx2_ABT (CM_Perso_Bedienstelle_Cx2_ABT)}, range raw 0..2, transfer-property=TRIGGERED-ON-CHANGE, to Klima(timeout 5 s)  # Signal zeigt an, über welche Bedienstelle die Umschaltung des Benutzerkontos gestartet wurden.
          signal Perso_Freigabe_Verstellung_XIX_Personalisierung_01_XIX_E3V_EVCANFD: start 28, 2 bit, little-endian, data-type-policy=OVERRIDE, i-signal-type=PRIMITIVE, init-value=0, base-type=BT_Perso_Freigabe_Verstellung, compu {0=Cx0_Init (CM_Perso_Freigabe_Verstellung_Cx0_Init), 1=Cx1_freigegeben (CM_Perso_Freigabe_Verstellung_Cx1_freigegeben)}, range raw 0..1, transfer-property=TRIGGERED-ON-CHANGE, to Klima(timeout 5 s)  # Signal zeigt an, ob die Ergonomiefunktionen nach Umschaltung des Benutzerkontos verfahren dürfen.
          signal Perso_Aktiv_XIX_Personalisierung_01_XIX_E3V_EVCANFD: start 30, 1 bit, little-endian, data-type-policy=OVERRIDE, i-signal-type=PRIMITIVE, init-value=0, base-type=BT_Perso_Aktiv, compu {0=Cx0_deaktiviert (CM_Perso_Aktiv_Cx0_deaktiviert), 1=Cx1_aktiviert (CM_Perso_Aktiv_Cx1_aktiviert)}, range raw 0..1, transfer-property=TRIGGERED-ON-CHANGE, to Klima(timeout 5 s)  # Status Personalisierung für den Fahrer aktiviert/ deaktiviert (via HMI)
          signal IAA_PSO_wake_up_XIX_Personalisierung_01_XIX_E3V_EVCANFD: start 31, 1 bit, little-endian, data-type-policy=OVERRIDE, i-signal-type=PRIMITIVE, init-value=0, base-type=BT_IAA_PSO_wake_up, compu {0=Cx0_wake_up_inactive (CM_IAA_PSO_wake_up_Cx0_wake_up_inactive), 1=Cx1_wake_up_active (CM_IAA_PSO_wake_up_Cx1_wake_up_active)}, range raw 0..1, transfer-property=TRIGGERED-ON-CHANGE, to Klima(timeout 5 s)  # Signal zum Wake_up der IAA und PSO Komponenten im Kombi und in der OCU
          signal Perso_Fahrernummer_XIX_Personalisierung_01_XIX_E3V_EVCANFD: start 32, 4 bit, little-endian, data-type-policy=OVERRIDE, i-signal-type=PRIMITIVE, init-value=0, base-type=BT_Perso_Fahrernummer, compu {0=Cx0_kein_Fahrer (CM_Perso_Fahrernummer_Cx0_kein_Fahrer), 1=Cx1_Fahrer_1 (CM_Perso_Fahrernummer_Cx1_Fahrer_1), 2=Cx2_Fahrer_2 (CM_Perso_Fahrernummer_Cx2_Fahrer_2), 3=Cx3_Fahrer_3 (CM_Perso_Fahrernummer_Cx3_Fahrer_3), 4=Cx4_Fahrer_4 (CM_Perso_Fahrernummer_Cx4_Fahrer_4), 5=Cx5_Fahrer_5 (CM_Perso_Fahrernummer_Cx5_Fahrer_5), 6=Cx6_Fahrer_6 (CM_Perso_Fahrernummer_Cx6_Fahrer_6), 7=Cx7_Fahrer_7 (CM_Perso_Fahrernummer_Cx7_Fahrer_7)}, range raw 0..7, transfer-property=TRIGGERED-ON-CHANGE, to Klima(timeout 5 s)  # Signal gibt die jewels aktuelle Nummer des Fahrers für die Personalisierung an. Nicht für AU736 und AU48x.
          signal Perso_Schreibschutz_XIX_Personalisierung_01_XIX_E3V_EVCANFD: start 36, 2 bit, little-endian, data-type-policy=OVERRIDE, i-signal-type=PRIMITIVE, init-value=0, base-type=BT_Perso_Schreibschutz, compu {0=Cx0_Schreibschutz_deaktiviert (CM_Perso_Schreibschutz_Cx0_Schreibschutz_deaktiviert), 1=Cx1_Schreibschutz_aktiviert (CM_Perso_Schreibschutz_Cx1_Schreibschutz_aktiviert)}, range raw 0..1, transfer-property=TRIGGERED-ON-CHANGE, to Klima(timeout 5 s)  # Signal zeigt an, ob der Schreibschutz der Personalisierung aktiv ist.
          signal IAA_Active_User_ID_XIX_Personalisierung_01_XIX_E3V_EVCANFD: start 38, 8 bit, little-endian, data-type-policy=OVERRIDE, i-signal-type=PRIMITIVE, init-value=0, base-type=BT_IAA_Active_User_ID, compu {phys=raw for raw 0..255; unit Unit_None}, range phys 0..255 Unit_None, raw 0..255, unit=Unit_None, transfer-property=TRIGGERED-ON-CHANGE, to Klima(timeout 5 s)  # Signal gibt die IAA Nutzer ID des aktiven IAA Nutzers an.
          signal IAA_Identified_User_ID_XIX_Personalisierung_01_XIX_E3V_EVCANFD: start 46, 8 bit, little-endian, data-type-policy=OVERRIDE, i-signal-type=PRIMITIVE, init-value=0, base-type=BT_IAA_Identified_User_ID, compu {phys=raw for raw 0..255; unit Unit_None}, range phys 0..255 Unit_None, raw 0..255, unit=Unit_None, transfer-property=TRIGGERED-ON-CHANGE, to Klima(timeout 5 s)  # Signal gibt die IAA Nutzer ID des vom BCM identifizierten IAA Nutzers an
      frame POS_GNSS_DR_01_XIX_E3V_EVCANFD: id 0x12DD55B4, to Klima, frame-length=64, can-addressing-mode=EXTENDED, can-frame-rx-behavior=CAN-FD, can-frame-tx-behavior=CAN-FD
        pdu POS_GNSS_DR_01_XIX_E3V_EVCANFD: length=56, transmission-mode-true-timing=cyclic-timing={time-offset=0, time-period=0.1}, unused-bit-pattern=0
          signal POS_GNSS_DR_Nachrichtenp_ID01_XIX_POS_GNSS_DR_01_XIX_E3V_EVCANFD: start 12, 4 bit, little-endian, data-type-policy=OVERRIDE, i-signal-type=PRIMITIVE, init-value=0, base-type=BT_POS_GNSS_DR_Nachrichtenp_ID01, compu {phys=raw for raw 0..15; unit Unit_None}, range phys 0..15 Unit_None, raw 0..15, unit=Unit_None, transfer-property=PENDING  # +1 für jedes neue Paket. Zyklische ID-Vergabe (Zähler). Zur Identifizierung zusammenhängender Nachrichten, die die Daten derselben DR-Ortung vom GNSS-Modul enthalten und somit zum selben Zyklus gehören. D.h. Daten in den Nachrichten wurden zur selben Zeit erzeugt. Der Zähler läuft um.
          signal POS_GNSS_DR_Breite_Ortung_XIX_POS_GNSS_DR_01_XIX_E3V_EVCANFD: start 16, 35 bit, little-endian, data-type-policy=OVERRIDE, i-signal-type=PRIMITIVE, init-value=34359738366, base-type=BT_POS_GNSS_DR_Breite_Ortung, invalid-value=Invalid_POS_GNSS_DR_Breite_Ortung_XIX_POS_GNSS_DR_01_XIX_E3V_EVCANFD:34359738367, compu {phys=raw*1e-08-90 for raw 0..18000000000, 34359738366=Cx7fffffffe_Init (CM_POS_GNSS_DR_Breite_Ortung_Cx7fffffffe_Init), 34359738367=Cx7ffffffff_Fehler (CM_POS_GNSS_DR_Breite_Ortung_Cx7ffffffff_Fehler); unit Unit_DegreOfArc}, range phys -90..90 Unit_DegreOfArc, raw 0..34359738367, unit=Unit_DegreOfArc, transfer-property=PENDING  # Breitengrad des Ortungsergebnisses entsprechend der DR-Position des GNSS-Moduls.
          signal POS_GNSS_DR_FahrzeugZeit_NanoSek_XIX_POS_GNSS_DR_01_XIX_E3V_EVCANFD: start 51, 30 bit, little-endian, data-type-policy=OVERRIDE, i-signal-type=PRIMITIVE, init-value=1073741822, base-type=BT_POS_GNSS_DR_FahrzeugZeit_NanoSek, invalid-value=Invalid_POS_GNSS_DR_FahrzeugZeit_NanoSek_XIX_POS_GNSS_DR_01_XIX_E3V_EVCANFD:1073741823, compu {phys=raw for raw 0..999999999, 1073741822=Cx3ffffffe_Init (CM_POS_GNSS_DR_FahrzeugZeit_NanoSek_Cx3ffffffe_Init), 1073741823=Cx3fffffff_Fehler (CM_POS_GNSS_DR_FahrzeugZeit_NanoSek_Cx3fffffff_Fehler); unit Unit_NanoSecon}, range phys 0..999999999 Unit_NanoSecon, raw 0..1073741823, unit=Unit_NanoSecon, transfer-property=PENDING  # Nachkommastellen der Sekunden für die DR-Position des GNSS-Moduls. Angabe in Nanosekunden, Zeitbasis: hochpraezise Fahrzeugzeit (Precise Local Time, PLT)
          signal POS_GNSS_DR_FahrzeugZeit_Sek_XIX_POS_GNSS_DR_01_XIX_E3V_EVCANFD: start 81, 32 bit, little-endian, data-type-policy=OVERRIDE, i-signal-type=PRIMITIVE, init-value=4294967294, base-type=BT_POS_GNSS_DR_FahrzeugZeit_Sek, invalid-value=Invalid_POS_GNSS_DR_FahrzeugZeit_Sek_XIX_POS_GNSS_DR_01_XIX_E3V_EVCANFD:4294967295, compu {phys=raw for raw 0..4294967293, 4294967294=Cxfffffffe_Init (CM_POS_GNSS_DR_FahrzeugZeit_Sek_Cxfffffffe_Init), 4294967295=Cxffffffff_Fehler (CM_POS_GNSS_DR_FahrzeugZeit_Sek_Cxffffffff_Fehler); unit Unit_Secon}, range phys 0..4294967293 Unit_Secon, raw 0..4294967295, unit=Unit_Secon, transfer-property=PENDING  # Sekunden des Zeitstempels für die DR-Position des GNSS-Moduls. Zeitbasis: hochpraezise Fahrzeugzeit (Precise Local Time, PLT), Sekunden seit dem Start der internen Fahrzeugzeit
          signal POS_GNSS_DR_Geschw_3D_XIX_POS_GNSS_DR_01_XIX_E3V_EVCANFD: start 113, 14 bit, little-endian, data-type-policy=OVERRIDE, i-signal-type=PRIMITIVE, init-value=16382, base-type=BT_POS_GNSS_DR_Geschw_3D, invalid-value=Invalid_POS_GNSS_DR_Geschw_3D_XIX_POS_GNSS_DR_01_XIX_E3V_EVCANFD:16383, compu {phys=raw*0.01 for raw 0..16300, 16381=Cx3ffd_hoeher_als_163 (CM_POS_GNSS_DR_Geschw_3D_Cx3ffd_hoeher_als_163), 16382=Cx3ffe_Init (CM_POS_GNSS_DR_Geschw_3D_Cx3ffe_Init), 16383=Cx3fff_Fehler (CM_POS_GNSS_DR_Geschw_3D_Cx3fff_Fehler); unit Unit_MeterPerSecon}, range phys 0..163 Unit_MeterPerSecon, raw 0..16383, unit=Unit_MeterPerSecon, transfer-property=PENDING  # 3D-Geschwindigkeit in m pro Sekunde entsprechend der DR-Position des GNSS-Moduls.
          signal POS_GNSS_DR_Gierwinkel_XIX_POS_GNSS_DR_01_XIX_E3V_EVCANFD: start 127, 12 bit, little-endian, data-type-policy=OVERRIDE, i-signal-type=PRIMITIVE, init-value=4094, base-type=BT_POS_GNSS_DR_Gierwinkel, invalid-value=Invalid_POS_GNSS_DR_Gierwinkel_XIX_POS_GNSS_DR_01_XIX_E3V_EVCANFD:4095, compu {phys=raw*0.1 for raw 0..3599, 4094=Cxffe_Init (CM_POS_GNSS_DR_Gierwinkel_Cxffe_Init), 4095=Cxfff_Fehler (CM_POS_GNSS_DR_Gierwinkel_Cxfff_Fehler); unit Unit_DegreOfArc}, range phys 0..359.9 Unit_DegreOfArc, raw 0..4095, unit=Unit_DegreOfArc, transfer-property=PENDING  # Ausrichtung des Fahrzeugs (Gierwinkel, Richtung der Längsachse bzw. Winkel um die vertikale Achse des Fahrzeugs) entsprechend der DR-Position des GNSS-Moduls
          signal POS_GNSS_DR_Guete_E_GrH_Ausr_XIX_POS_GNSS_DR_01_XIX_E3V_EVCANFD: start 139, 12 bit, little-endian, data-type-policy=OVERRIDE, i-signal-type=PRIMITIVE, init-value=4094, base-type=BT_POS_GNSS_DR_Guete_E_GrH_Ausr, invalid-value=Invalid_POS_GNSS_DR_Guete_E_GrH_Ausr_XIX_POS_GNSS_DR_01_XIX_E3V_EVCANFD:4095, compu {phys=raw*0.1 for raw 0..3599, 4094=Cxffe_Init (CM_POS_GNSS_DR_Guete_E_GrH_Ausr_Cxffe_Init), 4095=Cxfff_Fehler (CM_POS_GNSS_DR_Guete_E_GrH_Ausr_Cxfff_Fehler); unit Unit_DegreOfArc}, range phys 0..359.9 Unit_DegreOfArc, raw 0..4095, unit=Unit_DegreOfArc, transfer-property=PENDING  # Ausrichtung der großen Halbachse der horizontalen Fehlerellipse (für die horizontale Positionsgüte) bezüglich der DR-Position des GNSS-Moduls.
          signal POS_GNSS_DR_Guete_E_GrHalbachse_XIX_POS_GNSS_DR_01_XIX_E3V_EVCANFD: start 151, 15 bit, little-endian, data-type-policy=OVERRIDE, i-signal-type=PRIMITIVE, init-value=32766, base-type=BT_POS_GNSS_DR_Guete_E_GrHalbachse, invalid-value=Invalid_POS_GNSS_DR_Guete_E_GrHalbachse_XIX_POS_GNSS_DR_01_XIX_E3V_EVCANFD:32767, compu {phys=raw*0.01 for raw 0..25000, 32766=Cx7ffe_Init (CM_POS_GNSS_DR_Guete_E_GrHalbachse_Cx7ffe_Init), 32767=Cx7fff_Fehler (CM_POS_GNSS_DR_Guete_E_GrHalbachse_Cx7fff_Fehler); unit Unit_Meter}, range phys 0..250 Unit_Meter, raw 0..32767, unit=Unit_Meter, transfer-property=PENDING  # Länge der großen Halbachse der horizontalen Fehlerellipse (für die horizontale Positionsgüte) bezüglich der DR-Position des GNSS-Moduls.
          signal POS_GNSS_DR_Guete_E_KlHalbachse_XIX_POS_GNSS_DR_01_XIX_E3V_EVCANFD: start 166, 15 bit, little-endian, data-type-policy=OVERRIDE, i-signal-type=PRIMITIVE, init-value=32766, base-type=BT_POS_GNSS_DR_Guete_E_KlHalbachse, invalid-value=Invalid_POS_GNSS_DR_Guete_E_KlHalbachse_XIX_POS_GNSS_DR_01_XIX_E3V_EVCANFD:32767, compu {phys=raw*0.01 for raw 0..25000, 32766=Cx7ffe_Init (CM_POS_GNSS_DR_Guete_E_KlHalbachse_Cx7ffe_Init), 32767=Cx7fff_Fehler (CM_POS_GNSS_DR_Guete_E_KlHalbachse_Cx7fff_Fehler); unit Unit_Meter}, range phys 0..250 Unit_Meter, raw 0..32767, unit=Unit_Meter, transfer-property=PENDING  # Länge der kleinen Halbachse der horizontalen Fehlerellipse (für die horizontale Positionsgüte) bezüglich der DR-Position des GNSS-Moduls.
          signal POS_GNSS_DR_Guete_Geschw_3D_XIX_POS_GNSS_DR_01_XIX_E3V_EVCANFD: start 181, 10 bit, little-endian, data-type-policy=OVERRIDE, i-signal-type=PRIMITIVE, init-value=1022, base-type=BT_POS_GNSS_DR_Guete_Geschw_3D, invalid-value=Invalid_POS_GNSS_DR_Guete_Geschw_3D_XIX_POS_GNSS_DR_01_XIX_E3V_EVCANFD:1023, compu {phys=raw*0.01 for raw 0..1000, 1022=Cx3fe_Init (CM_POS_GNSS_DR_Guete_Geschw_3D_Cx3fe_Init), 1023=Cx3ff_Fehler (CM_POS_GNSS_DR_Guete_Geschw_3D_Cx3ff_Fehler); unit Unit_MeterPerSecon}, range phys 0..10 Unit_MeterPerSecon, raw 0..1023, unit=Unit_MeterPerSecon, transfer-property=PENDING  # Gesamtgenauigkeit bezüglich der 3D-Geschwindigkeit am Erdboden entsprechend der DR-Position des GNSS-Moduls.
          signal POS_GNSS_DR_Guete_Gierwinkel_XIX_POS_GNSS_DR_01_XIX_E3V_EVCANFD: start 191, 11 bit, little-endian, data-type-policy=OVERRIDE, i-signal-type=PRIMITIVE, init-value=2046, base-type=BT_POS_GNSS_DR_Guete_Gierwinkel, invalid-value=Invalid_POS_GNSS_DR_Guete_Gierwinkel_XIX_POS_GNSS_DR_01_XIX_E3V_EVCANFD:2047, compu {phys=raw*0.1 for raw 0..1800, 2046=Cx7fe_Init (CM_POS_GNSS_DR_Guete_Gierwinkel_Cx7fe_Init), 2047=Cx7ff_Fehler (CM_POS_GNSS_DR_Guete_Gierwinkel_Cx7ff_Fehler); unit Unit_DegreOfArc}, range phys 0..180 Unit_DegreOfArc, raw 0..2047, unit=Unit_DegreOfArc, transfer-property=PENDING  # Gesamtgenauigkeit bezüglich der Ausrichtung (Gierwinkel) entsprechend der DR-Position des GNSS-Moduls.
          signal POS_GNSS_DR_Guete_horizontal_XIX_POS_GNSS_DR_01_XIX_E3V_EVCANFD: start 202, 15 bit, little-endian, data-type-policy=OVERRIDE, i-signal-type=PRIMITIVE, init-value=32766, base-type=BT_POS_GNSS_DR_Guete_horizontal, invalid-value=Invalid_POS_GNSS_DR_Guete_horizontal_XIX_POS_GNSS_DR_01_XIX_E3V_EVCANFD:32767, compu {phys=raw*0.01 for raw 0..25000, 32766=Cx7ffe_Init (CM_POS_GNSS_DR_Guete_horizontal_Cx7ffe_Init), 32767=Cx7fff_Fehler (CM_POS_GNSS_DR_Guete_horizontal_Cx7fff_Fehler); unit Unit_Meter}, range phys 0..250 Unit_Meter, raw 0..32767, unit=Unit_Meter, transfer-property=PENDING  # Gesamtgenauigkeit bezüglich der 2D-Position (horizontal) entsprechend der DR-Position des GNSS-Moduls.
          signal POS_GNSS_DR_Guete_vertikal_XIX_POS_GNSS_DR_01_XIX_E3V_EVCANFD: start 217, 15 bit, little-endian, data-type-policy=OVERRIDE, i-signal-type=PRIMITIVE, init-value=32766, base-type=BT_POS_GNSS_DR_Guete_vertikal, invalid-value=Invalid_POS_GNSS_DR_Guete_vertikal_XIX_POS_GNSS_DR_01_XIX_E3V_EVCANFD:32767, compu {phys=raw*0.01 for raw 0..25000, 32766=Cx7ffe_Init (CM_POS_GNSS_DR_Guete_vertikal_Cx7ffe_Init), 32767=Cx7fff_Fehler (CM_POS_GNSS_DR_Guete_vertikal_Cx7fff_Fehler); unit Unit_Meter}, range phys 0..250 Unit_Meter, raw 0..32767, unit=Unit_Meter, transfer-property=PENDING  # Gesamtgenauigkeit bezüglich der 1D-Position (vertikal) entsprechend der DR-Position des GNSS-Moduls.
          signal POS_GNSS_DR_Laenge_Ortung_XIX_POS_GNSS_DR_01_XIX_E3V_EVCANFD: start 232, 36 bit, little-endian, data-type-policy=OVERRIDE, i-signal-type=PRIMITIVE, init-value=68719476734, base-type=BT_POS_GNSS_DR_Laenge_Ortung, invalid-value=Invalid_POS_GNSS_DR_Laenge_Ortung_XIX_POS_GNSS_DR_01_XIX_E3V_EVCANFD:68719476735, compu {phys=raw*1e-08-180 for raw 0..36000000000, 68719476734=Cxffffffffe_Init (CM_POS_GNSS_DR_Laenge_Ortung_Cxffffffffe_Init), 68719476735=Cxfffffffff_Fehler (CM_POS_GNSS_DR_Laenge_Ortung_Cxfffffffff_Fehler); unit Unit_DegreOfArc}, range phys -180..180 Unit_DegreOfArc, raw 0..68719476735, unit=Unit_DegreOfArc, transfer-property=PENDING  # Längengrad des Ortungsergebnisses entsprechend der DR-Position des GNSS-Moduls.
          signal POS_GNSS_DR_Ortung_Hoehe_MSL_XIX_POS_GNSS_DR_01_XIX_E3V_EVCANFD: start 268, 20 bit, little-endian, data-type-policy=OVERRIDE, i-signal-type=PRIMITIVE, init-value=1048574, base-type=BT_POS_GNSS_DR_Ortung_Hoehe_MSL, invalid-value=Invalid_POS_GNSS_DR_Ortung_Hoehe_MSL_XIX_POS_GNSS_DR_01_XIX_E3V_EVCANFD:1048575, compu {phys=raw*0.01-500 for raw 0..1048500, 1048574=Cxffffe_Init (CM_POS_GNSS_DR_Ortung_Hoehe_MSL_Cxffffe_Init), 1048575=Cxfffff_Fehler (CM_POS_GNSS_DR_Ortung_Hoehe_MSL_Cxfffff_Fehler); unit Unit_Meter}, range phys -500..9985 Unit_Meter, raw 0..1048575, unit=Unit_Meter, transfer-property=PENDING  # Höhe über dem Meeresspiegel entsprechend der DR-Position des GNSS-Moduls.
          signal POS_GNSS_DR_Ausrichtung_Geschw_XIX_POS_GNSS_DR_01_XIX_E3V_EVCANFD: start 288, 12 bit, little-endian, data-type-policy=OVERRIDE, i-signal-type=PRIMITIVE, init-value=0, base-type=BT_POS_GNSS_DR_Ausrichtung_Geschw, invalid-value=Invalid_POS_GNSS_DR_Ausrichtung_Geschw_XIX_POS_GNSS_DR_01_XIX_E3V_EVCANFD:4095, compu {phys=raw*0.1 for raw 0..3599, 4094=Cxffe_Init (CM_POS_GNSS_DR_Ausrichtung_Geschw_Cxffe_Init), 4095=Cxfff_Fehler (CM_POS_GNSS_DR_Ausrichtung_Geschw_Cxfff_Fehler); unit Unit_DegreOfArc}, range phys 0..359.9 Unit_DegreOfArc, raw 0..4095, unit=Unit_DegreOfArc, transfer-property=PENDING  # Ausrichtung des Ortungsergebnisses in Richtung des Geschwindigkeitsvektors entsprechend der DR-Position des GNSS-Moduls.
          signal POS_GNSS_DR_Guete_Ausricht_Gesch_XIX_POS_GNSS_DR_01_XIX_E3V_EVCANFD: start 300, 11 bit, little-endian, data-type-policy=OVERRIDE, i-signal-type=PRIMITIVE, init-value=0, base-type=BT_POS_GNSS_DR_Guete_Ausricht_Gesch, invalid-value=Invalid_POS_GNSS_DR_Guete_Ausricht_Gesch_XIX_POS_GNSS_DR_01_XIX_E3V_EVCANFD:2047, compu {phys=raw*0.1 for raw 0..1799, 2046=Cx7fe_Init (CM_POS_GNSS_DR_Guete_Ausricht_Gesch_Cx7fe_Init), 2047=Cx7ff_Fehler (CM_POS_GNSS_DR_Guete_Ausricht_Gesch_Cx7ff_Fehler); unit Unit_DegreOfArc}, range phys 0..179.9 Unit_DegreOfArc, raw 0..2047, unit=Unit_DegreOfArc, transfer-property=PENDING  # Güte der Ausrichtung des Ortungsergebnisses in Richtung des Geschwindigkeitsvektors entsprechend der DR-Position des GNSS-Moduls.
          signal POS_GNSS_DR_Fahrtrichtung_XIX_POS_GNSS_DR_01_XIX_E3V_EVCANFD: start 311, 2 bit, little-endian, data-type-policy=OVERRIDE, i-signal-type=PRIMITIVE, init-value=0, base-type=BT_POS_GNSS_DR_Fahrtrichtung, invalid-value=Invalid_POS_GNSS_DR_Fahrtrichtung_XIX_POS_GNSS_DR_01_XIX_E3V_EVCANFD:3, compu {0=Cx0_Init (CM_POS_GNSS_DR_Fahrtrichtung_Cx0_Init), 1=Cx1_vorwaerts (CM_POS_GNSS_DR_Fahrtrichtung_Cx1_vorwaerts), 2=Cx2_rueckwaerts (CM_POS_GNSS_DR_Fahrtrichtung_Cx2_rueckwaerts), 3=Cx3_Fehler (CM_POS_GNSS_DR_Fahrtrichtung_Cx3_Fehler)}, range raw 0..3, transfer-property=PENDING  # Fahrtrichtung des Ortungsergebnisses entsprechend der DR-Position des GNSS-Moduls.
          signal GNSS_DR_Ortung_Hoehe_XIX_POS_GNSS_DR_01_XIX_E3V_EVCANFD: start 313, 12 bit, little-endian, data-type-policy=OVERRIDE, i-signal-type=PRIMITIVE, init-value=4094, base-type=BT_GNSS_DR_Ortung_Hoehe, invalid-value=Invalid_GNSS_DR_Ortung_Hoehe_XIX_POS_GNSS_DR_01_XIX_E3V_EVCANFD:4095, compu {phys=raw*2-500 for raw 0..4093, 4094=Cxffe_Init (CM_GNSS_DR_Ortung_Hoehe_Cxffe_Init), 4095=Cxfff_Fehler (CM_GNSS_DR_Ortung_Hoehe_Cxfff_Fehler); unit Unit_Meter}, range phys -500..7686 Unit_Meter, raw 0..4095, unit=Unit_Meter, transfer-property=PENDING, to Klima(timeout 1 s)  # Dead Reckoning Höhe über dem Meeresspiegel
      frame PSD_04_XIX_E3V_EVCANFD: id 0x462, to Klima, frame-length=8, can-addressing-mode=STANDARD, can-frame-rx-behavior=CAN-FD, can-frame-tx-behavior=CAN-FD
        pdu PSD_04_XIX_E3V_EVCANFD: length=8, transmission-mode-true-timing=cyclic-timing={time-offset=0, time-period=0.15}, unused-bit-pattern=0
          signal PSD_Segment_ID_XIX_PSD_04_XIX_E3V_EVCANFD: start 0, 6 bit, little-endian, data-type-policy=OVERRIDE, i-signal-type=PRIMITIVE, init-value=0, base-type=BT_PSD_Segment_ID, compu {0=Cx0_keine_Segmentinformationen_vorhanden (CM_PSD_Segment_ID_Cx0_keine_Segmentinformationen_vorhanden) (keine Segmentinformationen vorhanden), 1=Cx1_Fehlerwert (CM_PSD_Segment_ID_Cx1_Fehlerwert), phys=raw for raw 2..63}, range phys 2..63, raw 0..63, transfer-property=PENDING, to Klima(timeout 1.5 s)  # Identifier des prädiktiven Streckensegments
          signal PSD_Vorgaenger_Segment_ID_XIX_PSD_04_XIX_E3V_EVCANFD: start 6, 6 bit, little-endian, data-type-policy=OVERRIDE, i-signal-type=PRIMITIVE, init-value=0, base-type=BT_PSD_Vorgaenger_Segment_ID, compu {0=Cx0_keine_Segmentinformation_vorhanden (CM_PSD_Vorgaenger_Segment_ID_Cx0_keine_Segmentinformation_vorhanden) (keine Segmentinformation vorhanden), 1=Cx1_Fehlerwert (CM_PSD_Vorgaenger_Segment_ID_Cx1_Fehlerwert), phys=raw for raw 2..63}, range phys 2..63, raw 0..63, transfer-property=PENDING, to Klima(timeout 1.5 s)  # An dem Streckensegment mit diesem Identifier schließt sich das neue Segment mit der ID "PSD_01_Segment_ID" an.
          signal PSD_Segmentlaenge_XIX_PSD_04_XIX_E3V_EVCANFD: start 12, 7 bit, little-endian, data-type-policy=OVERRIDE, i-signal-type=PRIMITIVE, init-value=0, base-type=BT_PSD_Segmentlaenge, compu {phys=raw*2 for raw 0..127; unit Unit_Meter}, range phys 0..254 Unit_Meter, raw 0..127, unit=Unit_Meter, transfer-property=PENDING, to Klima(timeout 1.5 s)  # Gesamtlänge des prädiktiven Streckensegments
          signal PSD_Strassenkategorie_XIX_PSD_04_XIX_E3V_EVCANFD: start 19, 3 bit, little-endian, data-type-policy=OVERRIDE, i-signal-type=PRIMITIVE, init-value=7, base-type=BT_PSD_Strassenkategorie, compu {0=Cx0_Rest_Feldweg_Schotterweg_Privatweg (CM_PSD_Strassenkategorie_Cx0_Rest_Feldweg_Schotterweg_Privatweg), 1=Cx1_Ortsstrasse (CM_PSD_Strassenkategorie_Cx1_Ortsstrasse) (Ortsstraße), 2=Cx2_Kreisstrasse (CM_PSD_Strassenkategorie_Cx2_Kreisstrasse) (Kreisstraße), 3=Cx3_Landstrasse (CM_PSD_Strassenkategorie_Cx3_Landstrasse) (Landstraße), 4=Cx4_Bundesstrasse (CM_PSD_Strassenkategorie_Cx4_Bundesstrasse) (Bundesstraße), 5=Cx5_Autobahn (CM_PSD_Strassenkategorie_Cx5_Autobahn), 7=Cx7_Init (CM_PSD_Strassenkategorie_Cx7_Init)}, range raw 0..7, transfer-property=PENDING, to Klima(timeout 1.5 s)  # Klassifizierung der Straße des beschriebenen Segments
          signal PSD_Endkruemmung_XIX_PSD_04_XIX_E3V_EVCANFD: start 22, 8 bit, little-endian, data-type-policy=OVERRIDE, i-signal-type=PRIMITIVE, init-value=0, base-type=BT_PSD_Endkruemmung, compu {phys=raw for raw 0..254, 255=Cxff_Gerade (CM_PSD_Endkruemmung_Cxff_Gerade); unit Unit_None}, range phys 0..254 Unit_None, raw 0..255, unit=Unit_None, transfer-property=PENDING, to Klima(timeout 1.5 s)  # "Endkrümmung der Klotoide des übermittelten Streckensegments. Die Anfangskrümmung des folgenden Streckensegments entspricht der Endkrümmung dieses Segments. Krümmung = 1/(1+0.155 * x²) [1/m]
          signal PSD_Endkruemmung_Vorz_XIX_PSD_04_XIX_E3V_EVCANFD: start 30, 1 bit, little-endian, data-type-policy=OVERRIDE, i-signal-type=PRIMITIVE, init-value=0, base-type=BT_PSD_Endkruemmung_Vorz, compu {0=Cx0_Kruemmung_positiv (CM_PSD_Endkruemmung_Vorz_Cx0_Kruemmung_positiv), 1=Cx1_Kruemmung_negativ (CM_PSD_Endkruemmung_Vorz_Cx1_Kruemmung_negativ)}, range raw 0..1, transfer-property=PENDING, to Klima(timeout 1.5 s)
          signal PSD_Idenditaets_ID_XIX_PSD_04_XIX_E3V_EVCANFD: start 31, 6 bit, little-endian, data-type-policy=OVERRIDE, i-signal-type=PRIMITIVE, init-value=0, base-type=BT_PSD_Idenditaets_ID, invalid-value=Invalid_PSD_Idenditaets_ID_XIX_PSD_04_XIX_E3V_EVCANFD:1, compu {0=Cx0_keine_Segment_Informationen_vorhanden (CM_PSD_Idenditaets_ID_Cx0_keine_Segment_Informationen_vorhanden), 1=Cx1_Fehler (CM_PSD_Idenditaets_ID_Cx1_Fehler), phys=raw for raw 2..63}, range phys 2..63, raw 0..63, transfer-property=PENDING, to Klima(timeout 1.5 s)  # Identifier auf ein Streckensegment, dass mit dem aktuell übertragenen geometrisch identisch ist.
          signal PSD_ADAS_Qualitaet_XIX_PSD_04_XIX_E3V_EVCANFD: start 37, 1 bit, little-endian, data-type-policy=OVERRIDE, i-signal-type=PRIMITIVE, init-value=0, base-type=BT_PSD_ADAS_Qualitaet, compu {0=Cx0_keine_ADAS_Qualitaet (CM_PSD_ADAS_Qualitaet_Cx0_keine_ADAS_Qualitaet), 1=Cx1_ADAS_Qualitaet (CM_PSD_ADAS_Qualitaet_Cx1_ADAS_Qualitaet)}, range raw 0..1, transfer-property=PENDING, to Klima(timeout 1.5 s)  # ADAS Qualtität des Streckensegments.
          signal PSD_wahrscheinlichster_Pfad_XIX_PSD_04_XIX_E3V_EVCANFD: start 38, 1 bit, little-endian, data-type-policy=OVERRIDE, i-signal-type=PRIMITIVE, init-value=0, base-type=BT_PSD_wahrscheinlichster_Pfad, compu {0=Cx0_Pfad_mit_geringer_Wahrscheinlichkeit (CM_PSD_wahrscheinlichster_Pfad_Cx0_Pfad_mit_geringer_Wahrscheinlichkeit), 1=Cx1_wahrscheinlichster_Pfad (CM_PSD_wahrscheinlichster_Pfad_Cx1_wahrscheinlichster_Pfad)}, range raw 0..1, transfer-property=PENDING, to Klima(timeout 1.5 s)  # Identifiziert den vom Navigationssystem berechneten wahrscheinlichsten Pfad des Fahrzeuges.
          signal PSD_Geradester_Pfad_XIX_PSD_04_XIX_E3V_EVCANFD: start 39, 1 bit, little-endian, data-type-policy=OVERRIDE, i-signal-type=PRIMITIVE, init-value=0, base-type=BT_PSD_Geradester_Pfad, compu {0=Cx0_nicht_geradester_PFad (CM_PSD_Geradester_Pfad_Cx0_nicht_geradester_PFad), 1=Cx1_geradester_Pfad (CM_PSD_Geradester_Pfad_Cx1_geradester_Pfad)}, range raw 0..1, transfer-property=PENDING, to Klima(timeout 1.5 s)  # Segment ist Teil des geradesten Pfades
          signal PSD_Fahrspuren_Anzahl_XIX_PSD_04_XIX_E3V_EVCANFD: start 40, 3 bit, little-endian, data-type-policy=OVERRIDE, i-signal-type=PRIMITIVE, init-value=1, base-type=BT_PSD_Fahrspuren_Anzahl, compu {0=Cx0_Einbahnstrasse_in_falsche_Richtung (CM_PSD_Fahrspuren_Anzahl_Cx0_Einbahnstrasse_in_falsche_Richtung), 1=Cx1_eine_Fahrspur (CM_PSD_Fahrspuren_Anzahl_Cx1_eine_Fahrspur), 2=Cx2_zwei_Fahrspuren (CM_PSD_Fahrspuren_Anzahl_Cx2_zwei_Fahrspuren), 3=Cx3_drei_Fahrspuren (CM_PSD_Fahrspuren_Anzahl_Cx3_drei_Fahrspuren), 4=Cx4_vier_Fahrspuren (CM_PSD_Fahrspuren_Anzahl_Cx4_vier_Fahrspuren), 5=Cx5_fuenf_Fahrspuren (CM_PSD_Fahrspuren_Anzahl_Cx5_fuenf_Fahrspuren), 6=Cx6_sechs_Fahrspuren (CM_PSD_Fahrspuren_Anzahl_Cx6_sechs_Fahrspuren), 7=Cx7_mehr_als_sechs_Fahrspuren (CM_PSD_Fahrspuren_Anzahl_Cx7_mehr_als_sechs_Fahrspuren)}, range raw 0..7, transfer-property=PENDING, to Klima(timeout 1.5 s)  # Anzahl der Fahrspuren in Fahrtrichtung
          signal PSD_Bebauung_XIX_PSD_04_XIX_E3V_EVCANFD: start 43, 1 bit, little-endian, data-type-policy=OVERRIDE, i-signal-type=PRIMITIVE, init-value=0, base-type=BT_PSD_Bebauung, compu {0=Cx0_ausserhalb_bebauten_Gebietes (CM_PSD_Bebauung_Cx0_ausserhalb_bebauten_Gebietes), 1=Cx1_innerhalb_bebauten_Gebietes (CM_PSD_Bebauung_Cx1_innerhalb_bebauten_Gebietes)}, range raw 0..1, transfer-property=PENDING, to Klima(timeout 1.5 s)  # Segement befindet sich innerhalb bebauten Gebietes
          signal PSD_Segment_Komplett_XIX_PSD_04_XIX_E3V_EVCANFD: start 44, 1 bit, little-endian, data-type-policy=OVERRIDE, i-signal-type=PRIMITIVE, init-value=0, base-type=BT_PSD_Segment_Komplett, compu {0=Cx0_Segment_Attribute_nicht_komplett (CM_PSD_Segment_Komplett_Cx0_Segment_Attribute_nicht_komplett), 1=Cx1_Segment_Attribute_komplett (CM_PSD_Segment_Komplett_Cx1_Segment_Attribute_komplett)}, range raw 0..1, transfer-property=PENDING, to Klima(timeout 1.5 s)  # Zeigt, ob alle Attribute für das Segment übertragen worden sind
          signal PSD_Rampe_XIX_PSD_04_XIX_E3V_EVCANFD: start 45, 2 bit, little-endian, data-type-policy=OVERRIDE, i-signal-type=PRIMITIVE, init-value=0, base-type=BT_PSD_Rampe, compu {0=Cx0_Strasse_mit_Gegenverkehr (CM_PSD_Rampe_Cx0_Strasse_mit_Gegenverkehr), 1=Cx1_Auffahrt_Einbahnstr (CM_PSD_Rampe_Cx1_Auffahrt_Einbahnstr), 2=Cx2_Abfahrt_Einbahnstr (CM_PSD_Rampe_Cx2_Abfahrt_Einbahnstr), 3=Cx3_Einbahnstrasse (CM_PSD_Rampe_Cx3_Einbahnstrasse)}, range raw 0..3, transfer-property=PENDING, to Klima(timeout 1.5 s)
          signal PSD_Anfangskruemmung_XIX_PSD_04_XIX_E3V_EVCANFD: start 47, 8 bit, little-endian, data-type-policy=OVERRIDE, i-signal-type=PRIMITIVE, init-value=0, base-type=BT_PSD_Anfangskruemmung, compu {phys=raw for raw 0..254, 255=Cxff_Gerade (CM_PSD_Anfangskruemmung_Cxff_Gerade)}, range phys 0..254, raw 0..255, transfer-property=PENDING, to Klima(timeout 1.5 s)  # Startkrümmung der Klothoide des übermittelten abzweigenden Streckensegments. 1/(1+0.155 * x^2) {1/m}"
          signal PSD_Anfangskruemmung_Vorz_XIX_PSD_04_XIX_E3V_EVCANFD: start 55, 1 bit, little-endian, data-type-policy=OVERRIDE, i-signal-type=PRIMITIVE, init-value=0, base-type=BT_PSD_Anfangskruemmung_Vorz, compu {0=Cx0_positiv (CM_PSD_Anfangskruemmung_Vorz_Cx0_positiv), 1=Cx1_negativ (CM_PSD_Anfangskruemmung_Vorz_Cx1_negativ)}, range raw 0..1, transfer-property=PENDING, to Klima(timeout 1.5 s)  # Vorzeichen für die Startkrümmung bei Abzweigungen
          signal PSD_Abzweigerichtung_XIX_PSD_04_XIX_E3V_EVCANFD: start 56, 1 bit, little-endian, data-type-policy=OVERRIDE, i-signal-type=PRIMITIVE, init-value=0, base-type=BT_PSD_Abzweigerichtung, compu {0=Cx0_rects_abzweigende_Strasse (CM_PSD_Abzweigerichtung_Cx0_rects_abzweigende_Strasse), 1=Cx1_links_abzweigende_Strasse (CM_PSD_Abzweigerichtung_Cx1_links_abzweigende_Strasse)}, range raw 0..1, transfer-property=PENDING, to Klima(timeout 1.5 s)  # Richtung, in der die Abzweigung von der Hauptroute abzweigt
          signal PSD_Abzweigewinkel_XIX_PSD_04_XIX_E3V_EVCANFD: start 57, 7 bit, little-endian, data-type-policy=OVERRIDE, i-signal-type=PRIMITIVE, init-value=0, base-type=BT_PSD_Abzweigewinkel, compu {phys=raw*1.417323 for raw 0..127}, range phys 0..180.000021, raw 0..127, transfer-property=PENDING, to Klima(timeout 1.5 s)  # Winkel, unter dem die Abzweigung von der Hauptroute abzweigt.
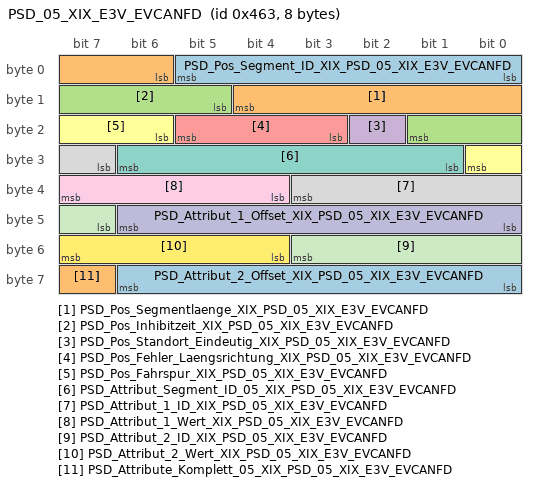
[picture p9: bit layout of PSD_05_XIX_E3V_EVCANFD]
      frame PSD_05_XIX_E3V_EVCANFD: id 0x463, to Klima, frame-length=8, can-addressing-mode=STANDARD, can-frame-rx-behavior=CAN-FD, can-frame-tx-behavior=CAN-FD
        pdu PSD_05_XIX_E3V_EVCANFD: length=8, transmission-mode-true-timing=cyclic-timing={time-offset=0, time-period=0.15}, unused-bit-pattern=0
          signal PSD_Pos_Segment_ID_XIX_PSD_05_XIX_E3V_EVCANFD: start 0, 6 bit, little-endian, data-type-policy=OVERRIDE, i-signal-type=PRIMITIVE, init-value=0, base-type=BT_PSD_Pos_Segment_ID, compu {0=Cx0_keine_Position_gegeben (CM_PSD_Pos_Segment_ID_Cx0_keine_Position_gegeben) (keine Position gegeben), 1=Cx1_Fehlerwert (CM_PSD_Pos_Segment_ID_Cx1_Fehlerwert), phys=raw for raw 2..63}, range phys 2..63, raw 0..63, transfer-property=PENDING, to Klima(timeout 1.5 s)  # Identifier des Streckensegments, auf dem sich das Fahrzeug aktuell befindet
          signal PSD_Pos_Segmentlaenge_XIX_PSD_05_XIX_E3V_EVCANFD: start 6, 7 bit, little-endian, data-type-policy=OVERRIDE, i-signal-type=PRIMITIVE, init-value=0, base-type=BT_PSD_Pos_Segmentlaenge, compu {phys=raw*2 for raw 0..127; unit Unit_Meter}, range phys 0..254 Unit_Meter, raw 0..127, unit=Unit_Meter, transfer-property=PENDING, to Klima(timeout 1.5 s)  # Verbleibende Länge des Streckensegments, auf dem sich das Fahrzeug aktuell befindet
          signal PSD_Pos_Inhibitzeit_XIX_PSD_05_XIX_E3V_EVCANFD: start 13, 5 bit, little-endian, data-type-policy=OVERRIDE, i-signal-type=PRIMITIVE, init-value=0, base-type=BT_PSD_Pos_Inhibitzeit, compu {phys=raw*10 for raw 0..31; unit Unit_MilliSecon}, range phys 0..310 Unit_MilliSecon, raw 0..31, unit=Unit_MilliSecon, transfer-property=PENDING, to Klima(timeout 1.5 s)  # Zeitspanne zwischen Generierung der PSD Daten im Navigationssystem und Versand der Daten auf den Most
          signal PSD_Pos_Standort_Eindeutig_XIX_PSD_05_XIX_E3V_EVCANFD: start 18, 1 bit, little-endian, data-type-policy=OVERRIDE, i-signal-type=PRIMITIVE, init-value=0, base-type=BT_PSD_Pos_Standort_Eindeutig, compu {0=Cx0_mehrdeutiger_Standort (CM_PSD_Pos_Standort_Eindeutig_Cx0_mehrdeutiger_Standort), 1=Cx1_eindeutiger_Standort (CM_PSD_Pos_Standort_Eindeutig_Cx1_eindeutiger_Standort)}, range raw 0..1, transfer-property=PENDING, to Klima(timeout 1.5 s)  # Ist die Position des Fahrzeugs eindeutig dem aktuelle Segment zugeordnet, oder gibt es fahrbare alternative Segmente, die bei akteller GPS-Position ebenfalls als aktuelles Segment möglich wären.
          signal PSD_Pos_Fehler_Laengsrichtung_XIX_PSD_05_XIX_E3V_EVCANFD: start 19, 3 bit, little-endian, data-type-policy=OVERRIDE, i-signal-type=PRIMITIVE, init-value=0, base-type=BT_PSD_Pos_Fehler_Laengsrichtung, compu {0=Cx0_Init (CM_PSD_Pos_Fehler_Laengsrichtung_Cx0_Init), 1=Cx1_2m (CM_PSD_Pos_Fehler_Laengsrichtung_Cx1_2m) (< 2m), 2=Cx2_5m (CM_PSD_Pos_Fehler_Laengsrichtung_Cx2_5m) (< 5m), 3=Cx3_10m (CM_PSD_Pos_Fehler_Laengsrichtung_Cx3_10m) (< 10m), 4=Cx4_20m (CM_PSD_Pos_Fehler_Laengsrichtung_Cx4_20m) (< 20m), 5=Cx5_50m (CM_PSD_Pos_Fehler_Laengsrichtung_Cx5_50m) (< 50m), 6=Cx6_50m (CM_PSD_Pos_Fehler_Laengsrichtung_Cx6_50m) (> 50m), 7=Cx7_Off_Road (CM_PSD_Pos_Fehler_Laengsrichtung_Cx7_Off_Road) (Off-Road)}, range raw 0..7, transfer-property=PENDING, to Klima(timeout 1.5 s)  # Laengsfehler der Positionierung
          signal PSD_Pos_Fahrspur_XIX_PSD_05_XIX_E3V_EVCANFD: start 22, 3 bit, little-endian, data-type-policy=OVERRIDE, i-signal-type=PRIMITIVE, init-value=0, base-type=BT_PSD_Pos_Fahrspur, compu {0=Cx0_unbekannt (CM_PSD_Pos_Fahrspur_Cx0_unbekannt), 1=Cx1_Erste_Spur_von_rechts (CM_PSD_Pos_Fahrspur_Cx1_Erste_Spur_von_rechts), 2=Cx2_Zweite_Spur_von_rechts (CM_PSD_Pos_Fahrspur_Cx2_Zweite_Spur_von_rechts), 3=Cx3_Dritte_Spur_von_rechts (CM_PSD_Pos_Fahrspur_Cx3_Dritte_Spur_von_rechts), 4=Cx4_Vierte_Spur_von_rechts (CM_PSD_Pos_Fahrspur_Cx4_Vierte_Spur_von_rechts), 5=Cx5_Fuenfte_Spur_von_rechts (CM_PSD_Pos_Fahrspur_Cx5_Fuenfte_Spur_von_rechts), 6=Cx6_Sechte_Spur_von_rechts (CM_PSD_Pos_Fahrspur_Cx6_Sechte_Spur_von_rechts), 7=Cx7_Siebte_oder_weitere_Spur_von_rechts (CM_PSD_Pos_Fahrspur_Cx7_Siebte_oder_weitere_Spur_von_rechts)}, range raw 0..7, transfer-property=PENDING, to Klima(timeout 1.5 s)  # Spur, auf der sich das Fahrzeug aktuell befindet
          signal PSD_Attribut_Segment_ID_05_XIX_PSD_05_XIX_E3V_EVCANFD: start 25, 6 bit, little-endian, data-type-policy=OVERRIDE, i-signal-type=PRIMITIVE, init-value=0, base-type=BT_PSD_Attribut_Segment_ID_05, invalid-value=Invalid_PSD_Attribut_Segment_ID_05_XIX_PSD_05_XIX_E3V_EVCANFD:1, compu {0=Cx0_keine_Segment_Information (CM_PSD_Attribut_Segment_ID_05_Cx0_keine_Segment_Information), 1=Cx1_Fehler (CM_PSD_Attribut_Segment_ID_05_Cx1_Fehler), phys=raw for raw 2..63}, range phys 2..63, raw 0..63, transfer-property=PENDING, to Klima(timeout 1.5 s)  # Identifier des Streckensegments, für das die weiteren Attribute in der Botschaft gültig sind
          signal PSD_Attribut_1_ID_XIX_PSD_05_XIX_E3V_EVCANFD: start 31, 5 bit, little-endian, data-type-policy=OVERRIDE, i-signal-type=PRIMITIVE, init-value=0, base-type=BT_PSD_Attribut_1_ID, compu {0=Cx0_keine_Information (CM_PSD_Attribut_1_ID_Cx0_keine_Information), phys=raw for raw 1..31}, range phys 1..31, raw 0..31, transfer-property=PENDING, to Klima(timeout 1.5 s)  # Identifier des ersten Attributes
          signal PSD_Attribut_1_Wert_XIX_PSD_05_XIX_E3V_EVCANFD: start 36, 4 bit, little-endian, data-type-policy=OVERRIDE, i-signal-type=PRIMITIVE, init-value=0, base-type=BT_PSD_Attribut_1_Wert, compu {phys=raw for raw 0..15; unit Unit_None}, range phys 0..15 Unit_None, raw 0..15, unit=Unit_None, transfer-property=PENDING, to Klima(timeout 1.5 s)  # Wert des ersten Attributes
          signal PSD_Attribut_1_Offset_XIX_PSD_05_XIX_E3V_EVCANFD: start 40, 7 bit, little-endian, data-type-policy=OVERRIDE, i-signal-type=PRIMITIVE, init-value=0, base-type=BT_PSD_Attribut_1_Offset, compu {phys=raw*2 for raw 0..127; unit Unit_Meter}, range phys 0..254 Unit_Meter, raw 0..127, unit=Unit_Meter, transfer-property=PENDING, to Klima(timeout 1.5 s)  # Positionsoffset im Segment für die Position des Attributs
          signal PSD_Attribut_2_ID_XIX_PSD_05_XIX_E3V_EVCANFD: start 47, 5 bit, little-endian, data-type-policy=OVERRIDE, i-signal-type=PRIMITIVE, init-value=0, base-type=BT_PSD_Attribut_2_ID, compu {0=Cx0_keine_Information (CM_PSD_Attribut_2_ID_Cx0_keine_Information), phys=raw for raw 1..31}, range phys 1..31, raw 0..31, transfer-property=PENDING, to Klima(timeout 1.5 s)  # Identifier des zweiten Attributes
          signal PSD_Attribut_2_Wert_XIX_PSD_05_XIX_E3V_EVCANFD: start 52, 4 bit, little-endian, data-type-policy=OVERRIDE, i-signal-type=PRIMITIVE, init-value=0, base-type=BT_PSD_Attribut_2_Wert, compu {phys=raw for raw 0..15; unit Unit_None}, range phys 0..15 Unit_None, raw 0..15, unit=Unit_None, transfer-property=PENDING, to Klima(timeout 1.5 s)  # Wert des zweiten Attributes
          signal PSD_Attribut_2_Offset_XIX_PSD_05_XIX_E3V_EVCANFD: start 56, 7 bit, little-endian, data-type-policy=OVERRIDE, i-signal-type=PRIMITIVE, init-value=0, base-type=BT_PSD_Attribut_2_Offset, compu {phys=raw*2 for raw 0..127; unit Unit_Meter}, range phys 0..254 Unit_Meter, raw 0..127, unit=Unit_Meter, transfer-property=PENDING, to Klima(timeout 1.5 s)  # Positionsoffset im Segment für die Position des Attributs
          signal PSD_Attribute_Komplett_05_XIX_PSD_05_XIX_E3V_EVCANFD: start 63, 1 bit, little-endian, data-type-policy=OVERRIDE, i-signal-type=PRIMITIVE, init-value=0, base-type=BT_PSD_Attribute_Komplett_05, compu {0=Cx0_Attribute_nicht_komplett (CM_PSD_Attribute_Komplett_05_Cx0_Attribute_nicht_komplett), 1=Cx1_Attribute_komplett (CM_PSD_Attribute_Komplett_05_Cx1_Attribute_komplett)}, range raw 0..1, transfer-property=PENDING, to Klima(timeout 1.5 s)  # Zeigt, ob alle Attribute für das Segment übertragen worden sind
      frame PSD_06_XIX_E3V_EVCANFD: id 0x464, to Klima, frame-length=8, can-addressing-mode=STANDARD, can-frame-rx-behavior=CAN-FD, can-frame-tx-behavior=CAN-FD
        multiplexed i pdu PSD_06_XIX_E3V_EVCANFD:
          length=8
          dynamic-part{segment-position{segment-byte-order=little-endian, segment-length=64, segment-position=0}, dynamic-part-alternatives=[{i-pdu=PSD_06_Mx00_XIX_E3V_EVCANFD, initial-dynamic-part=true, selector-field-code=0}, {i-pdu=PSD_06_Mx01_XIX_E3V_EVCANFD, initial-dynamic-part=false, selector-field-code=1}, {i-pdu=PSD_06_Mx02_XIX_E3V_EVCANFD, initial-dynamic-part=false, selector-field-code=2}, {i-pdu=PSD_06_Mx03_XIX_E3V_EVCANFD, initial-dynamic-part=false, selector-field-code=3}, {i-pdu=PSD_06_Mx04_XIX_E3V_EVCANFD, initial-dynamic-part=false, selector-field-code=4}]}
          selector-field-byte-order=little-endian
          selector-field-length=3
          selector-field-start-position=0
          trigger-mode=DYNAMIC-PART-TRIGGER
          unused-bit-pattern=0
      frame PSD_LR_01_XIX_E3V_EVCANFD: id 0x465, to Klima, frame-length=8, can-addressing-mode=STANDARD, can-frame-rx-behavior=CAN-FD, can-frame-tx-behavior=CAN-FD
        multiplexed i pdu PSD_LR_01_XIX_E3V_EVCANFD:
          length=8
          dynamic-part{segment-position{segment-byte-order=little-endian, segment-length=62, segment-position=2}, dynamic-part-alternatives=[{i-pdu=PSD_LR_01_Mx00_XIX_E3V_EVCANFD, initial-dynamic-part=true, selector-field-code=0}, {i-pdu=PSD_LR_01_Mx01_XIX_E3V_EVCANFD, initial-dynamic-part=false, selector-field-code=1}, {i-pdu=PSD_LR_01_Mx02_XIX_E3V_EVCANFD, initial-dynamic-part=false, selector-field-code=2}, {i-pdu=PSD_LR_01_Mx03_XIX_E3V_EVCANFD, initial-dynamic-part=false, selector-field-code=3}]}
          selector-field-byte-order=little-endian
          selector-field-length=2
          selector-field-start-position=2
          static-part{segment-position{segment-byte-order=little-endian, segment-length=2, segment-position=0}, i-pdu=PSD_LR_01_MxStatic_XIX_E3V_EVCANFD}
          trigger-mode=DYNAMIC-PART-TRIGGER
          unused-bit-pattern=0
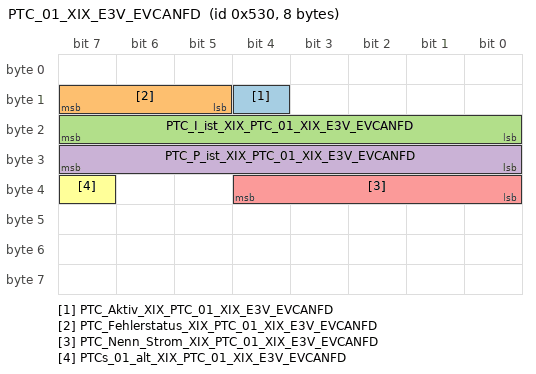
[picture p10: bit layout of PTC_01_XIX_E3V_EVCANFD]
      frame PTC_01_XIX_E3V_EVCANFD: id 0x530, from Klima, frame-length=8, can-addressing-mode=STANDARD, can-frame-rx-behavior=CAN-FD, can-frame-tx-behavior=CAN-FD
        pdu PTC_01_XIX_E3V_EVCANFD: length=8, transmission-mode-true-timing=cyclic-timing={time-offset=0.0, time-period=0.2}, unused-bit-pattern=0
          signal PTC_Aktiv_XIX_PTC_01_XIX_E3V_EVCANFD: start 12, 1 bit, little-endian, data-type-policy=OVERRIDE, i-signal-type=PRIMITIVE, init-value=0, base-type=BT_PTC_Aktiv, compu {phys=raw for raw 0..1}, range phys 0..1, raw 0..1, transfer-property=PENDING  # 1 = PTC-Elemente werden bestromt (Heizanforderung vom Bediengeraet und Aussen- und Kuehlwasser-temperaturbedingung erfuellt Vorhalt fuer VW, nicht Audi B8
          signal PTC_Fehlerstatus_XIX_PTC_01_XIX_E3V_EVCANFD: start 13, 3 bit, little-endian, data-type-policy=OVERRIDE, i-signal-type=PRIMITIVE, init-value=0, base-type=BT_PTC_Fehlerstatus, compu {phys=raw for raw 0..7}, range phys 0..7, raw 0..7, transfer-property=PENDING  # Fehlerstatus PTC Zuheizer; 0 = kein Fehler; 1 = Unterspannung; 2 = Ueberspannung; 3 = Ueberstrom; 4 = HW defekt; 5 = Ueberhitzung; 6...7 nicht definiert Vorhalt fuer VW, nicht Audi B8
          signal PTC_I_ist_XIX_PTC_01_XIX_E3V_EVCANFD: start 16, 8 bit, little-endian, data-type-policy=OVERRIDE, i-signal-type=PRIMITIVE, init-value=254, base-type=BT_PTC_I_ist, compu {phys=raw for raw 0..253, 254=Cxfe_Init (CM_PTC_I_ist_Cxfe_Init), 255=Cxff_Fehler (CM_PTC_I_ist_Cxff_Fehler); unit Unit_Amper}, range phys 0..253 Unit_Amper, raw 0..255, unit=Unit_Amper, transfer-property=PENDING  # PTC Stromverbrauch (max. 120A)
          signal PTC_P_ist_XIX_PTC_01_XIX_E3V_EVCANFD: start 24, 8 bit, little-endian, data-type-policy=OVERRIDE, i-signal-type=PRIMITIVE, init-value=254, base-type=BT_PTC_P_ist, compu {phys=raw*10 for raw 0..253, 254=Cxfe_Init (CM_PTC_P_ist_Cxfe_Init), 255=Cxff_Fehler (CM_PTC_P_ist_Cxff_Fehler); unit Unit_Watt}, range phys 0..2530 Unit_Watt, raw 0..255, unit=Unit_Watt, transfer-property=PENDING  # PTC Leistungsaufnahme
          signal PTC_Nenn_Strom_XIX_PTC_01_XIX_E3V_EVCANFD: start 32, 5 bit, little-endian, data-type-policy=OVERRIDE, i-signal-type=PRIMITIVE, init-value=0, base-type=BT_PTC_Nenn_Strom, compu {phys=raw*10 for raw 0..31; unit Unit_Amper}, range phys 0..310 Unit_Amper, raw 0..31, unit=Unit_Amper, transfer-property=PENDING  # Summe der Nennstroeme aller PTC-Heizelemente
          signal PTCs_01_alt_XIX_PTC_01_XIX_E3V_EVCANFD: start 39, 1 bit, little-endian, data-type-policy=OVERRIDE, i-signal-type=PRIMITIVE, init-value=1, base-type=BT_PTCs_01_alt, compu {0=Cx0_aktuell (CM_PTCs_01_alt_Cx0_aktuell), 1=Cx1_veraltet (CM_PTCs_01_alt_Cx1_veraltet)}, range raw 0..1, transfer-property=PENDING  # Veraltet Bit für die LIN-Botschaft PTCs_01. Betroffene Signale: PTC_I_ist PTC_P_ist
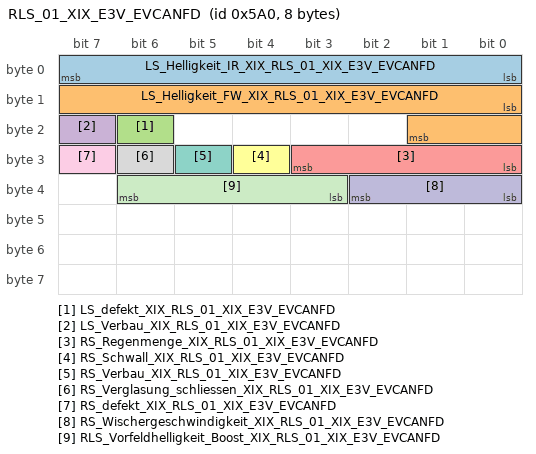
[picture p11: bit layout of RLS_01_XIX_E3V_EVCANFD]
      frame RLS_01_XIX_E3V_EVCANFD: id 0x5A0, to Klima, frame-length=8, can-addressing-mode=STANDARD, can-frame-rx-behavior=CAN-FD, can-frame-tx-behavior=CAN-FD
        pdu RLS_01_XIX_E3V_EVCANFD: length=8, transmission-mode-true-timing=cyclic-timing={time-offset=0.0, time-period=0.2}, unused-bit-pattern=0  # 8Byte ab MLBevo LIN-CAN (1:1) Botschaften werden geroutet - wenn entsprechender Slave codiert ist - wenn fehlerfreie Kommunikation zum Slave besteht - bei fehlerhafter Kommunikation zum Slave wird die Botschaft für 4s mit den letzten gültigen Werten versendet
          signal LS_Helligkeit_IR_XIX_RLS_01_XIX_E3V_EVCANFD: start 0, 8 bit, little-endian, data-type-policy=OVERRIDE, i-signal-type=PRIMITIVE, init-value=254, base-type=BT_LS_Helligkeit_IR, invalid-value=Invalid_LS_Helligkeit_IR_XIX_RLS_01_XIX_E3V_EVCANFD:255, compu {phys=raw*400 for raw 0..253, 254=Cxfe_Init (CM_LS_Helligkeit_IR_Cxfe_Init), 255=Cxff_Fehler (CM_LS_Helligkeit_IR_Cxff_Fehler); unit Unit_Lux}, range phys 0..101200 Unit_Lux, raw 0..255, unit=Unit_Lux, transfer-property=PENDING, to Klima(timeout 2 s)  # Globalfeldhelligkeit
          signal LS_Helligkeit_FW_XIX_RLS_01_XIX_E3V_EVCANFD: start 8, 10 bit, little-endian, data-type-policy=OVERRIDE, i-signal-type=PRIMITIVE, init-value=1022, base-type=BT_LS_Helligkeit_FW, invalid-value=Invalid_LS_Helligkeit_FW_XIX_RLS_01_XIX_E3V_EVCANFD:1023, compu {phys=raw*6 for raw 0..1021, 1022=Cx3fe_Init (CM_LS_Helligkeit_FW_Cx3fe_Init), 1023=Cx3ff_Fehler (CM_LS_Helligkeit_FW_Cx3ff_Fehler); unit Unit_Lux}, range phys 0..6126 Unit_Lux, raw 0..1023, unit=Unit_Lux, transfer-property=PENDING  # Vorfeldhelligkeit
          signal LS_defekt_XIX_RLS_01_XIX_E3V_EVCANFD: start 22, 1 bit, little-endian, data-type-policy=OVERRIDE, i-signal-type=PRIMITIVE, init-value=0, base-type=BT_LS_defekt, compu {0=Cx0_OK (CM_LS_defekt_Cx0_OK), 1=Cx1_defekt (CM_LS_defekt_Cx1_defekt)}, range raw 0..1, transfer-property=PENDING  # Fehlererkennung Lichtsensor
          signal LS_Verbau_XIX_RLS_01_XIX_E3V_EVCANFD: start 23, 1 bit, little-endian, data-type-policy=OVERRIDE, i-signal-type=PRIMITIVE, init-value=0, base-type=BT_LS_Verbau, compu {0=Cx0_Init (CM_LS_Verbau_Cx0_Init), 1=Cx1_Lichtsensor_verbaut (CM_LS_Verbau_Cx1_Lichtsensor_verbaut)}, range raw 0..1, transfer-property=PENDING  # Verbauinfo Lichtsensor
          signal RS_Regenmenge_XIX_RLS_01_XIX_E3V_EVCANFD: start 24, 4 bit, little-endian, data-type-policy=OVERRIDE, i-signal-type=PRIMITIVE, init-value=14, base-type=BT_RS_Regenmenge, invalid-value=Invalid_RS_Regenmenge_XIX_RLS_01_XIX_E3V_EVCANFD:15, compu {0=Cx0_0 (CM_RS_Regenmenge_Cx0_0), 1=Cx1_0_0_bis_0_3 (CM_RS_Regenmenge_Cx1_0_0_bis_0_3) (0,0_bis_0,3), 2=Cx2_0_31_bis_1_4 (CM_RS_Regenmenge_Cx2_0_31_bis_1_4) (0,31_bis_1,4), 3=Cx3_1_41_bis_2_0 (CM_RS_Regenmenge_Cx3_1_41_bis_2_0) (1,41_bis_2,0), 4=Cx4_2_01_bis_2_8 (CM_RS_Regenmenge_Cx4_2_01_bis_2_8) (2,01_bis_2,8), 5=Cx5_2_81_bis_3_3 (CM_RS_Regenmenge_Cx5_2_81_bis_3_3) (2,81_bis_3,3), 6=Cx6_3_31_bis_4_0 (CM_RS_Regenmenge_Cx6_3_31_bis_4_0) (3,31_bis_4,0), 7=Cx7_4_01_bis_5_0 (CM_RS_Regenmenge_Cx7_4_01_bis_5_0) (4,01_bis_5,0), 8=Cx8_5_01_bis_7_0 (CM_RS_Regenmenge_Cx8_5_01_bis_7_0) (5,01_bis_7,0), 9=Cx9_7_01_bis_9_0 (CM_RS_Regenmenge_Cx9_7_01_bis_9_0) (7,01_bis_9,0), 10=Cxa_9_01_bis_11_0 (CM_RS_Regenmenge_Cxa_9_01_bis_11_0) (9,01_bis_11,0), 11=Cxb_11_01_bis_15_0 (CM_RS_Regenmenge_Cxb_11_01_bis_15_0) (11,01_bis_15,0), 12=Cxc_15_01_bis_22_0 (CM_RS_Regenmenge_Cxc_15_01_bis_22_0) (15,01_bis_22,0), 13=Cxd_22_01 (CM_RS_Regenmenge_Cxd_22_01) (>22,01), 14=Cxe_Init (CM_RS_Regenmenge_Cxe_Init), 15=Cxf_Fehler (CM_RS_Regenmenge_Cxf_Fehler)}, range raw 0..15, transfer-property=PENDING, to Klima(timeout 2 s)  # Regenmenge
          signal RS_Schwall_XIX_RLS_01_XIX_E3V_EVCANFD: start 28, 1 bit, little-endian, data-type-policy=OVERRIDE, i-signal-type=PRIMITIVE, init-value=0, base-type=BT_RS_Schwall, compu {0=Cx0_Aus (CM_RS_Schwall_Cx0_Aus), 1=Cx1_Ein (CM_RS_Schwall_Cx1_Ein)}, range raw 0..1, transfer-property=PENDING  # Schwallereignis
          signal RS_Verbau_XIX_RLS_01_XIX_E3V_EVCANFD: start 29, 1 bit, little-endian, data-type-policy=OVERRIDE, i-signal-type=PRIMITIVE, init-value=0, base-type=BT_RS_Verbau, compu {0=Cx0_Init (CM_RS_Verbau_Cx0_Init), 1=Cx1_Regensensor_verbaut (CM_RS_Verbau_Cx1_Regensensor_verbaut) (Regensensor verbaut)}, range raw 0..1, transfer-property=PENDING  # Verbauinfo Regensensor
          signal RS_Verglasung_schliessen_XIX_RLS_01_XIX_E3V_EVCANFD: start 30, 1 bit, little-endian, data-type-policy=OVERRIDE, i-signal-type=PRIMITIVE, init-value=0, base-type=BT_RS_Verglasung_schliessen, compu {0=Cx0_Verglasung_nicht_schliessen (CM_RS_Verglasung_schliessen_Cx0_Verglasung_nicht_schliessen) (Verglasung nicht schliessen), 1=Cx1_Verglasung_schliessen (CM_RS_Verglasung_schliessen_Cx1_Verglasung_schliessen) (Verglasung schliessen)}, range raw 0..1, transfer-property=PENDING  # Anforderung: Verglasung schliessen
          signal RS_defekt_XIX_RLS_01_XIX_E3V_EVCANFD: start 31, 1 bit, little-endian, data-type-policy=OVERRIDE, i-signal-type=PRIMITIVE, init-value=0, base-type=BT_RS_defekt, compu {0=Cx0_OK (CM_RS_defekt_Cx0_OK), 1=Cx1_defekt (CM_RS_defekt_Cx1_defekt)}, range raw 0..1, transfer-property=PENDING, to Klima(timeout 2 s)  # Fehlererkennung Regensensor
          signal RS_Wischergeschwindigkeit_XIX_RLS_01_XIX_E3V_EVCANFD: start 32, 3 bit, little-endian, data-type-policy=OVERRIDE, i-signal-type=PRIMITIVE, init-value=0, base-type=BT_RS_Wischergeschwindigkeit, compu {0=Cx0_kein_Wischen (CM_RS_Wischergeschwindigkeit_Cx0_kein_Wischen) (kein Wischen), 1=Cx1_42_Huebe_min (CM_RS_Wischergeschwindigkeit_Cx1_42_Huebe_min) (42 Huebe/min), 2=Cx2_45_Huebe_min (CM_RS_Wischergeschwindigkeit_Cx2_45_Huebe_min) (45 Huebe/min), 3=Cx3_48_Huebe_min (CM_RS_Wischergeschwindigkeit_Cx3_48_Huebe_min) (48 Huebe/min), 4=Cx4_51_Huebe_min (CM_RS_Wischergeschwindigkeit_Cx4_51_Huebe_min) (51 Huebe/min), 5=Cx5_54_Huebe_min (CM_RS_Wischergeschwindigkeit_Cx5_54_Huebe_min) (54 Huebe/min), 6=Cx6_57_Huebe_min (CM_RS_Wischergeschwindigkeit_Cx6_57_Huebe_min) (57 Huebe/min), 7=Cx7_60_Huebe_min (CM_RS_Wischergeschwindigkeit_Cx7_60_Huebe_min) (60 Huebe/min)}, range raw 0..7, transfer-property=PENDING, to Klima(timeout 2 s)  # Wischergeschwindigkeit (Hübe/min)
          signal RLS_Vorfeldhelligkeit_Boost_XIX_RLS_01_XIX_E3V_EVCANFD: start 35, 4 bit, little-endian, data-type-policy=OVERRIDE, i-signal-type=PRIMITIVE, init-value=15, base-type=BT_RLS_Vorfeldhelligkeit_Boost, compu {0=Cx0_groesser_24413_Lux (CM_RLS_Vorfeldhelligkeit_Boost_Cx0_groesser_24413_Lux), 1=Cx1_bis_24413_Lux (CM_RLS_Vorfeldhelligkeit_Boost_Cx1_bis_24413_Lux), 2=Cx2_bis_22193_Lux (CM_RLS_Vorfeldhelligkeit_Boost_Cx2_bis_22193_Lux), 3=Cx3_bis_20176_Lux (CM_RLS_Vorfeldhelligkeit_Boost_Cx3_bis_20176_Lux), 4=Cx4_bis_18342_Lux (CM_RLS_Vorfeldhelligkeit_Boost_Cx4_bis_18342_Lux), 5=Cx5_bis_16647_Lux (CM_RLS_Vorfeldhelligkeit_Boost_Cx5_bis_16647_Lux), 6=Cx6_bis_15158_Lux (CM_RLS_Vorfeldhelligkeit_Boost_Cx6_bis_15158_Lux), 7=Cx7_bis_13780_Lux (CM_RLS_Vorfeldhelligkeit_Boost_Cx7_bis_13780_Lux), 8=Cx8_bis_12527_Lux (CM_RLS_Vorfeldhelligkeit_Boost_Cx8_bis_12527_Lux), 9=Cx9_bis_11388_Lux (CM_RLS_Vorfeldhelligkeit_Boost_Cx9_bis_11388_Lux), 10=Cxa_bis_10353_Lux (CM_RLS_Vorfeldhelligkeit_Boost_Cxa_bis_10353_Lux), 11=Cxb_bis_9412_Lux (CM_RLS_Vorfeldhelligkeit_Boost_Cxb_bis_9412_Lux), 12=Cxc_bis_8556_Lux (CM_RLS_Vorfeldhelligkeit_Boost_Cxc_bis_8556_Lux), 13=Cxd_bis_7778_Lux (CM_RLS_Vorfeldhelligkeit_Boost_Cxd_bis_7778_Lux), 14=Cxe_bis_7071_Lux (CM_RLS_Vorfeldhelligkeit_Boost_Cxe_bis_7071_Lux), 15=Cxf_bis_6428_Lux (CM_RLS_Vorfeldhelligkeit_Boost_Cxf_bis_6428_Lux)}, range raw 0..15, transfer-property=PENDING  # erweiterte Helligkeitssensierung für HUD
